VERSION "eCMP INFO-DIV vehicle review 2026-11-03; 125000 bit/s; PSA-RE 67f7581e7622410efdbb29c7eda3b86982b9b450; Apache-2.0"

NS_ :

BS_:

BU_: AAS AMPLI AVP BCM BGP BSG BSI BTA BTEL BTT CDC CMB CRT DIAG_TOOL EDP_C EMF FMUX IC ICSV IDVR IVC_D MATT MDS OVIP PDS_C RAD RBG SDCM VTH WLC

BO_ 305 ICSV_AudioSourceCommand: 8 ICSV
 SG_ ListJumpRequest : 63|8@0+ (1,0) [0|254] ""  CDC
 SG_ CdChangerKnobStepCounter : 55|8@0+ (1,0) [0|255] ""  CDC
 SG_ ValidatedItemNumber : 42|3@0+ (1,0) [0|7] ""  CDC
 SG_ UnicodeSupport : 43|1@0+ (1,0) [0|1] ""  CDC
 SG_ CdChangerListMode : 44|1@0+ (1,0) [0|1] ""  CDC
 SG_ DisplayListLineCount : 47|3@0+ (1,0) [1|6] ""  CDC
 SG_ TrackNumberSelect : 39|8@0+ (1,0) [1|255] ""  CDC
 SG_ ListFocusItemNumber : 26|3@0+ (1,0) [0|7] ""  CDC
 SG_ Unused1 : 31|5@0+ (1,0) [0|31] ""  CDC
 SG_ DiscNumberCommand : 19|4@0+ (1,0) [0|15] ""  CDC
 SG_ NextDiscNumberCommand : 23|4@0+ (1,0) [0|15] ""  CDC
 SG_ CdPlayMode : 9|2@0+ (1,0) [0|3] ""  CDC
 SG_ TrackDiscRepeatMode : 11|2@0+ (1,0) [0|3] ""  CDC
 SG_ AudioMasterMp3Compatible : 12|1@0+ (1,0) [0|1] ""  CDC
 SG_ CdChangerCommandSeries : 15|3@0+ (1,0) [0|7] ""  CDC
 SG_ CdChangerCommand : 2|3@0+ (1,0) [0|7] ""  CDC
 SG_ RandomTrackRestartRequest : 3|1@0+ (1,0) [0|1] ""  CDC
 SG_ CdcKnobSyncRequest : 4|1@0+ (1,0) [0|1] ""  CDC
 SG_ RandomTableSeek : 6|2@0+ (1,0) [0|3] ""  CDC
 SG_ CdChangerOnOff : 7|1@0+ (1,0) [0|1] ""  CDC

BO_ 321 SDCM_UidTableEncryptedToBsi: 8 SDCM
 SG_ FlowPadding5 m3 : 63|8@0+ (1,0) [0|255] "raw"  BSI
 SG_ FirstData6 m1 : 63|8@0+ (1,0) [0|255] "raw"  BSI
 SG_ UnknownData7 m4 : 63|8@0+ (1,0) [0|255] "raw"  BSI
 SG_ ConsecutiveData7 m2 : 63|8@0+ (1,0) [0|255] "raw"  BSI
 SG_ SingleData7 m0 : 63|8@0+ (1,0) [0|255] "raw"  BSI
 SG_ FlowPadding4 m3 : 55|8@0+ (1,0) [0|255] "raw"  BSI
 SG_ FirstData5 m1 : 55|8@0+ (1,0) [0|255] "raw"  BSI
 SG_ UnknownData6 m4 : 55|8@0+ (1,0) [0|255] "raw"  BSI
 SG_ ConsecutiveData6 m2 : 55|8@0+ (1,0) [0|255] "raw"  BSI
 SG_ SingleData6 m0 : 55|8@0+ (1,0) [0|255] "raw"  BSI
 SG_ FlowPadding3 m3 : 47|8@0+ (1,0) [0|255] "raw"  BSI
 SG_ FirstData4 m1 : 47|8@0+ (1,0) [0|255] "raw"  BSI
 SG_ UnknownData5 m4 : 47|8@0+ (1,0) [0|255] "raw"  BSI
 SG_ ConsecutiveData5 m2 : 47|8@0+ (1,0) [0|255] "raw"  BSI
 SG_ SingleData5 m0 : 47|8@0+ (1,0) [0|255] "raw"  BSI
 SG_ FlowPadding2 m3 : 39|8@0+ (1,0) [0|255] "raw"  BSI
 SG_ FirstData3 m1 : 39|8@0+ (1,0) [0|255] "raw"  BSI
 SG_ UnknownData4 m4 : 39|8@0+ (1,0) [0|255] "raw"  BSI
 SG_ ConsecutiveData4 m2 : 39|8@0+ (1,0) [0|255] "raw"  BSI
 SG_ SingleData4 m0 : 39|8@0+ (1,0) [0|255] "raw"  BSI
 SG_ FlowPadding1 m3 : 31|8@0+ (1,0) [0|255] "raw"  BSI
 SG_ FirstData2 m1 : 31|8@0+ (1,0) [0|255] "raw"  BSI
 SG_ UnknownData3 m4 : 31|8@0+ (1,0) [0|255] "raw"  BSI
 SG_ ConsecutiveData3 m2 : 31|8@0+ (1,0) [0|255] "raw"  BSI
 SG_ SingleData3 m0 : 31|8@0+ (1,0) [0|255] "raw"  BSI
 SG_ FirstData1 m1 : 23|8@0+ (1,0) [0|255] "raw"  BSI
 SG_ UnknownData2 m4 : 23|8@0+ (1,0) [0|255] "raw"  BSI
 SG_ ConsecutiveData2 m2 : 23|8@0+ (1,0) [0|255] "raw"  BSI
 SG_ SingleData2 m0 : 23|8@0+ (1,0) [0|255] "raw"  BSI
 SG_ SeparationTimeRaw m3 : 23|8@0+ (1,0) [0|255] "raw"  BSI
 SG_ UnknownData1 m4 : 15|8@0+ (1,0) [0|255] "raw"  BSI
 SG_ ConsecutiveData1 m2 : 15|8@0+ (1,0) [0|255] "raw"  BSI
 SG_ SingleData1 m0 : 15|8@0+ (1,0) [0|255] "raw"  BSI
 SG_ BlockSize m3 : 15|8@0+ (1,0) [0|255] "raw"  BSI
 SG_ UnknownPciLow m4 : 3|4@0+ (1,0) [0|15] "raw"  BSI
 SG_ FlowStatus m3 : 3|4@0+ (1,0) [0|15] "raw"  BSI
 SG_ ConsecutiveSequence m2 : 3|4@0+ (1,0) [0|15] "raw"  BSI
 SG_ FirstFrameLength m1 : 3|12@0+ (1,0) [0|4095] "raw"  BSI
 SG_ SingleFrameLength m0 : 3|4@0+ (1,0) [0|15] "raw"  BSI
 SG_ IsoTpFrameType M : 7|4@0+ (1,0) [0|15] ""  BSI

BO_ 347 EMF_ProfileSettingsScreen: 8 EMF
 SG_ AmlaActivationRequest : 56|1@0+ (1,0) [0|1] ""  BSI
 SG_ AfsActivationRequest : 57|1@0+ (1,0) [0|1] ""  BSI
 SG_ ArsActivationRequest : 58|1@0+ (1,0) [0|1] ""  BSI
 SG_ IrvInhibitRequest : 59|1@0+ (1,0) [0|1] ""  BSI
 SG_ DaeModeSelection4wd : 61|2@0+ (1,0) [0|3] ""  BSI
 SG_ DaeModeSelection : 63|2@0+ (1,0) [0|3] ""  BSI
 SG_ DriverAlertAssistActivati_e419b7 : 48|1@0+ (1,0) [0|1] ""  BSI
 SG_ LoadedArmAccessLockRequest : 49|1@0+ (1,0) [0|1] ""  BSI
 SG_ LoadedArmAccessRequest : 50|1@0+ (1,0) [0|1] ""  BSI
 SG_ IlvScreenRequest : 51|1@0+ (1,0) [0|1] ""  BSI
 SG_ GrilleLightingFunctionStatus : 52|1@0+ (1,0) [0|1] ""  BSI
 SG_ CafrActivationRequest : 53|1@0+ (1,0) [0|1] ""  BSI
 SG_ UserProfileSelection : 55|2@0+ (1,0) [0|3] ""  BSI
 SG_ EtsrActivationRequest : 40|1@0+ (1,0) [0|1] ""  BSI
 SG_ SeeModeSelection : 41|1@0+ (1,0) [0|1] ""  BSI
 SG_ ReverseMirrorIndexingRequest : 42|1@0+ (1,0) [0|1] ""  BSI
 SG_ TpmsInitFunctionRequest : 43|1@0+ (1,0) [0|1] ""  BSI
 SG_ CollisionRiskBrakingType : 44|1@0+ (1,0) [0|1] ""  BSI
 SG_ ArcSensitivityLevel : 46|2@0+ (1,0) [0|3] ""  BSI
 SG_ ArcFunctionActive : 47|1@0+ (1,0) [0|1] ""  BSI
 SG_ ConfigurableButtonFunction : 35|4@0+ (1,0) [0|15] ""  BSI
 SG_ RearFlapMotorizationFunct_177f8c : 36|1@0+ (1,0) [0|1] ""  BSI
 SG_ AutomaticRearWiperInReverse : 37|1@0+ (1,0) [0|1] ""  BSI
 SG_ BlindSpotMonitoringFeedbackType : 38|1@0+ (1,0) [0|1] ""  BSI
 SG_ ParkingAidSetup : 39|1@0+ (1,0) [0|1] ""  BSI
 SG_ AutomaticHeadlightsSwitchingOn : 24|1@0+ (1,0) [0|1] ""  BSI
 SG_ UnlockingLightingDuration : 26|2@0+ (1,0) [0|3] ""  BSI
 SG_ UnlockingLightingFunction : 27|1@0+ (1,0) [0|1] ""  BSI
 SG_ MotorwayLightingFunction : 28|1@0+ (1,0) [0|1] ""  BSI
 SG_ FollowMeHomeDuration : 30|2@0+ (1,0) [0|3] ""  BSI
 SG_ FollowMeHome : 31|1@0+ (1,0) [0|1] ""  BSI
 SG_ AmbientLighting : 16|1@0+ (1,0) [0|1] ""  BSI
 SG_ DlrFunction : 17|1@0+ (1,0) [0|1] ""  BSI
 SG_ AdaptiveLighting : 18|1@0+ (1,0) [0|1] ""  BSI
 SG_ DriverGreeting : 19|1@0+ (1,0) [0|1] ""  BSI
 SG_ RearOpeningsSelectivityStatus : 20|1@0+ (1,0) [0|1] ""  BSI
 SG_ CabOpeningsSelectivityFun_dd2313 : 21|1@0+ (1,0) [0|1] ""  BSI
 SG_ DoorUnlockingModeOnKey : 22|1@0+ (1,0) [0|1] ""  BSI
 SG_ AutomaticElectricParkingB_11b15b : 23|1@0+ (1,0) [0|1] ""  BSI
 SG_ VehicleSoundHarmony : 9|2@0+ (1,0) [0|3] ""  BSI
 SG_ VehicleConfigurationDataValid : 10|1@0+ (1,0) [0|1] ""  BSI
 SG_ AmbientLightingLevel : 13|3@0+ (1,0) [0|7] ""  BSI
 SG_ TemperatureUnit : 14|1@0+ (1,0) [0|1] ""  BSI
 SG_ ConfigVolumeUnit : 15|1@0+ (1,0) [0|1] ""  BSI
 SG_ ConfigConsumptionUnit : 0|1@0+ (1,0) [0|1] ""  BSI
 SG_ DistanceUnit : 1|1@0+ (1,0) [0|1] ""  BSI
 SG_ VehicleLanguage : 6|5@0+ (1,0) [0|31] ""  BSI
 SG_ UnitLanguageDataValidity : 7|1@0+ (1,0) [0|1] ""  BSI

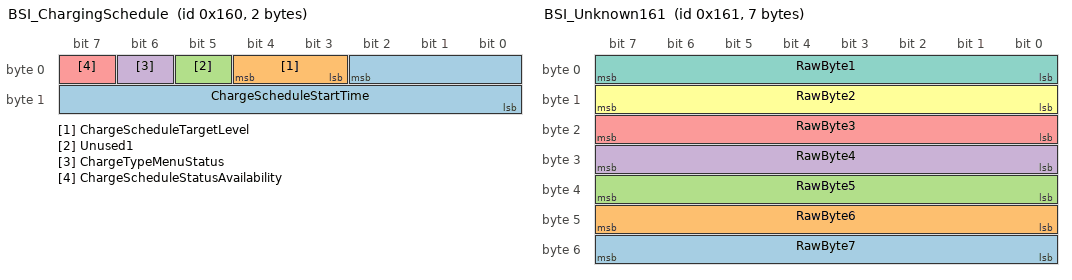
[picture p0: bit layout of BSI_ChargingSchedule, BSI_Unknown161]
BO_ 352 BSI_ChargingSchedule: 2 BSI
 SG_ ChargeScheduleStartTime : 2|11@0+ (1,0) [0|1440] "min"  MDS,BTEL,OVIP
 SG_ ChargeScheduleTargetLevel : 4|2@0+ (1,0) [0|3] ""  MDS,BTEL,OVIP
 SG_ Unused1 : 5|1@0+ (1,0) [0|1] ""  MDS,BTEL,OVIP
 SG_ ChargeTypeMenuStatus : 6|1@0+ (1,0) [0|1] ""  MDS,BTEL,OVIP
 SG_ ChargeScheduleStatusAvailability : 7|1@0+ (1,0) [0|1] ""  MDS,BTEL,OVIP

BO_ 353 BSI_Unknown161: 7 BSI
 SG_ RawByte7 : 55|8@0+ (1,0) [0|255] "raw" Vector__XXX
 SG_ RawByte6 : 47|8@0+ (1,0) [0|255] "raw" Vector__XXX
 SG_ RawByte5 : 39|8@0+ (1,0) [0|255] "raw" Vector__XXX
 SG_ RawByte4 : 31|8@0+ (1,0) [0|255] "raw" Vector__XXX
 SG_ RawByte3 : 23|8@0+ (1,0) [0|255] "raw" Vector__XXX
 SG_ RawByte2 : 15|8@0+ (1,0) [0|255] "raw" Vector__XXX
 SG_ RawByte1 : 7|8@0+ (1,0) [0|255] "raw" Vector__XXX

BO_ 354 ICSV_CdChangerStatus: 7 ICSV
 SG_ CdcFrontPushButtonNumber : 51|4@0+ (1,0) [0|15] ""  RAD,EMF,BTEL,OVIP,BSI
 SG_ CdcEjectLoadButtonPressed : 53|2@0+ (1,0) [0|3] ""  RAD,EMF,BTEL,OVIP,BSI
 SG_ Unused5 : 55|2@0+ (1,0) [0|3] ""  RAD,EMF,BTEL,OVIP,BSI
 SG_ DiscPresenceCd1 : 40|1@0+ (1,0) [0|1] ""  RAD,EMF,BTEL,OVIP,BSI
 SG_ DiscPresenceCd2 : 41|1@0+ (1,0) [0|1] ""  RAD,EMF,BTEL,OVIP,BSI
 SG_ DiscPresenceCd3 : 42|1@0+ (1,0) [0|1] ""  RAD,EMF,BTEL,OVIP,BSI
 SG_ DiscPresenceCd4 : 43|1@0+ (1,0) [0|1] ""  RAD,EMF,BTEL,OVIP,BSI
 SG_ DiscPresenceCd5 : 44|1@0+ (1,0) [0|1] ""  RAD,EMF,BTEL,OVIP,BSI
 SG_ DiscPresenceCd6 : 45|1@0+ (1,0) [0|1] ""  RAD,EMF,BTEL,OVIP,BSI
 SG_ DiscPresenceCd7 : 46|1@0+ (1,0) [0|1] ""  RAD,EMF,BTEL,OVIP,BSI
 SG_ DiscPresenceCd8 : 47|1@0+ (1,0) [0|1] ""  RAD,EMF,BTEL,OVIP,BSI
 SG_ Unused4 : 39|8@0+ (1,0) [0|255] ""  RAD,EMF,BTEL,OVIP,BSI
 SG_ CdcCurrentDiscNumber : 27|4@0+ (1,0) [1|15] ""  RAD,EMF,BTEL,OVIP,BSI
 SG_ Unused3 : 29|2@0+ (1,0) [0|3] ""  RAD,EMF,BTEL,OVIP,BSI
 SG_ CdcAccessType : 31|2@0+ (1,0) [0|3] ""  RAD,EMF,BTEL,OVIP,BSI
 SG_ CdcCapacity : 19|4@0+ (1,0) [0|15] ""  RAD,EMF,BTEL,OVIP,BSI
 SG_ CdcMagazinePresence : 20|1@0+ (1,0) [0|1] ""  RAD,EMF,BTEL,OVIP,BSI
 SG_ CdcDoorStatus : 21|1@0+ (1,0) [0|1] ""  RAD,EMF,BTEL,OVIP,BSI
 SG_ CdcStatusError : 22|1@0+ (1,0) [0|1] ""  RAD,EMF,BTEL,OVIP,BSI
 SG_ CdcOverTemperature : 23|1@0+ (1,0) [0|1] ""  RAD,EMF,BTEL,OVIP,BSI
 SG_ CdcPlayerState : 10|3@0+ (1,0) [0|7] ""  RAD,EMF,BTEL,OVIP,BSI
 SG_ CdcTextAvailable : 11|1@0+ (1,0) [0|1] ""  RAD,EMF,BTEL,OVIP,BSI
 SG_ DiscError : 12|1@0+ (1,0) [0|1] ""  RAD,EMF,BTEL,OVIP,BSI
 SG_ DiscUpsideDown : 13|1@0+ (1,0) [0|1] ""  RAD,EMF,BTEL,OVIP,BSI
 SG_ CdcMp3Support : 14|1@0+ (1,0) [0|1] ""  RAD,EMF,BTEL,OVIP,BSI
 SG_ CdcDiscAccessInProgress : 15|1@0+ (1,0) [0|1] ""  RAD,EMF,BTEL,OVIP,BSI
 SG_ Unused2 : 1|2@0+ (1,0) [0|3] ""  RAD,EMF,BTEL,OVIP,BSI
 SG_ CdcTrackDiscRepeatState : 3|2@0+ (1,0) [0|3] ""  RAD,EMF,BTEL,OVIP,BSI
 SG_ Unused1 : 4|1@0+ (1,0) [0|1] ""  RAD,EMF,BTEL,OVIP,BSI
 SG_ CdcChangerType : 5|1@0+ (1,0) [0|1] ""  RAD,EMF,BTEL,OVIP,BSI
 SG_ CdcListModeRequest : 6|1@0+ (1,0) [0|1] ""  RAD,EMF,BTEL,OVIP,BSI
 SG_ CdcOnOffStatus : 7|1@0+ (1,0) [0|1] ""  RAD,EMF,BTEL,OVIP,BSI

BO_ 355 ICSV_KmlListNone: 8 ICSV
 SG_ FlowPadding5 m3 : 63|8@0+ (1,0) [0|255] "raw"  EMF
 SG_ FirstData6 m1 : 63|8@0+ (1,0) [0|255] "raw"  EMF
 SG_ UnknownData7 m4 : 63|8@0+ (1,0) [0|255] "raw"  EMF
 SG_ ConsecutiveData7 m2 : 63|8@0+ (1,0) [0|255] "raw"  EMF
 SG_ SingleData7 m0 : 63|8@0+ (1,0) [0|255] "raw"  EMF
 SG_ FlowPadding4 m3 : 55|8@0+ (1,0) [0|255] "raw"  EMF
 SG_ FirstData5 m1 : 55|8@0+ (1,0) [0|255] "raw"  EMF
 SG_ UnknownData6 m4 : 55|8@0+ (1,0) [0|255] "raw"  EMF
 SG_ ConsecutiveData6 m2 : 55|8@0+ (1,0) [0|255] "raw"  EMF
 SG_ SingleData6 m0 : 55|8@0+ (1,0) [0|255] "raw"  EMF
 SG_ FlowPadding3 m3 : 47|8@0+ (1,0) [0|255] "raw"  EMF
 SG_ FirstData4 m1 : 47|8@0+ (1,0) [0|255] "raw"  EMF
 SG_ UnknownData5 m4 : 47|8@0+ (1,0) [0|255] "raw"  EMF
 SG_ ConsecutiveData5 m2 : 47|8@0+ (1,0) [0|255] "raw"  EMF
 SG_ SingleData5 m0 : 47|8@0+ (1,0) [0|255] "raw"  EMF
 SG_ FlowPadding2 m3 : 39|8@0+ (1,0) [0|255] "raw"  EMF
 SG_ FirstData3 m1 : 39|8@0+ (1,0) [0|255] "raw"  EMF
 SG_ UnknownData4 m4 : 39|8@0+ (1,0) [0|255] "raw"  EMF
 SG_ ConsecutiveData4 m2 : 39|8@0+ (1,0) [0|255] "raw"  EMF
 SG_ SingleData4 m0 : 39|8@0+ (1,0) [0|255] "raw"  EMF
 SG_ FlowPadding1 m3 : 31|8@0+ (1,0) [0|255] "raw"  EMF
 SG_ FirstData2 m1 : 31|8@0+ (1,0) [0|255] "raw"  EMF
 SG_ UnknownData3 m4 : 31|8@0+ (1,0) [0|255] "raw"  EMF
 SG_ ConsecutiveData3 m2 : 31|8@0+ (1,0) [0|255] "raw"  EMF
 SG_ SingleData3 m0 : 31|8@0+ (1,0) [0|255] "raw"  EMF
 SG_ FirstData1 m1 : 23|8@0+ (1,0) [0|255] "raw"  EMF
 SG_ UnknownData2 m4 : 23|8@0+ (1,0) [0|255] "raw"  EMF
 SG_ ConsecutiveData2 m2 : 23|8@0+ (1,0) [0|255] "raw"  EMF
 SG_ SingleData2 m0 : 23|8@0+ (1,0) [0|255] "raw"  EMF
 SG_ SeparationTimeRaw m3 : 23|8@0+ (1,0) [0|255] "raw"  EMF
 SG_ UnknownData1 m4 : 15|8@0+ (1,0) [0|255] "raw"  EMF
 SG_ ConsecutiveData1 m2 : 15|8@0+ (1,0) [0|255] "raw"  EMF
 SG_ SingleData1 m0 : 15|8@0+ (1,0) [0|255] "raw"  EMF
 SG_ BlockSize m3 : 15|8@0+ (1,0) [0|255] "raw"  EMF
 SG_ UnknownPciLow m4 : 3|4@0+ (1,0) [0|15] "raw"  EMF
 SG_ FlowStatus m3 : 3|4@0+ (1,0) [0|15] "raw"  EMF
 SG_ ConsecutiveSequence m2 : 3|4@0+ (1,0) [0|15] "raw"  EMF
 SG_ FirstFrameLength m1 : 3|12@0+ (1,0) [0|4095] "raw"  EMF
 SG_ SingleFrameLength m0 : 3|4@0+ (1,0) [0|15] "raw"  EMF
 SG_ IsoTpFrameType M : 7|4@0+ (1,0) [0|15] ""  EMF

BO_ 357 BTEL_RadioStatusGeneral: 6 BTEL
 SG_ RawByte6 : 47|8@0+ (1,0) [0|255] "raw" Vector__XXX
 SG_ Unused1 : 38|7@0+ (1,0) [0|127] ""  CRT,FMUX,CMB,EMF,BSI,AMPLI,MDS,BTA
 SG_ MixedChannelMute : 39|1@0+ (1,0) [0|1] ""  CRT,FMUX,CMB,EMF,BSI,AMPLI,MDS,BTA
 SG_ BtSrc : 25|2@0+ (1,0) [0|3] ""  CRT,FMUX,CMB,EMF,BSI,AMPLI,MDS,BTA
 SG_ SupportedDigitalRadio : 28|3@0+ (1,0) [0|7] ""  CRT,FMUX,CMB,EMF,BSI,AMPLI,MDS,BTA
 SG_ CdAudioCompression : 31|3@0+ (1,0) [0|7] ""  CRT,FMUX,CMB,EMF,BSI,AMPLI,MDS,BTA
 SG_ NoSrc : 18|3@0+ (1,0) [0|7] ""  CRT,FMUX,CMB,EMF,BSI,AMPLI,MDS,BTA
 SG_ SrcKml : 19|1@0+ (1,0) [0|1] ""  CRT,FMUX,CMB,EMF,BSI,AMPLI,MDS,BTA
 SG_ SrcSel : 22|3@0+ (1,0) [0|7] ""  CRT,FMUX,CMB,EMF,BSI,AMPLI,MDS,BTA
 SG_ SrcMix : 23|1@0+ (1,0) [0|1] ""  CRT,FMUX,CMB,EMF,BSI,AMPLI,MDS,BTA
 SG_ TimeshiftHoldRequest : 8|1@0+ (1,0) [0|1] ""  CRT,FMUX,CMB,EMF,BSI,AMPLI,MDS,BTA
 SG_ UsbSrc : 10|2@0+ (1,0) [0|3] ""  CRT,FMUX,CMB,EMF,BSI,AMPLI,MDS,BTA
 SG_ CdcSrc : 12|2@0+ (1,0) [0|3] ""  CRT,FMUX,CMB,EMF,BSI,AMPLI,MDS,BTA
 SG_ CdSrc : 14|2@0+ (1,0) [0|3] ""  CRT,FMUX,CMB,EMF,BSI,AMPLI,MDS,BTA
 SG_ TunSrc : 15|1@0+ (1,0) [0|1] ""  CRT,FMUX,CMB,EMF,BSI,AMPLI,MDS,BTA
 SG_ UsbSourceType : 0|1@0+ (1,0) [0|1] ""  CRT,FMUX,CMB,EMF,BSI,AMPLI,MDS,BTA
 SG_ DynamicsCompression : 1|1@0+ (1,0) [0|1] ""  CRT,FMUX,CMB,EMF,BSI,AMPLI,MDS,BTA
 SG_ HifiVersion : 2|1@0+ (1,0) [0|1] ""  CRT,FMUX,CMB,EMF,BSI,AMPLI,MDS,BTA
 SG_ BiTuner : 3|1@0+ (1,0) [0|1] ""  CRT,FMUX,CMB,EMF,BSI,AMPLI,MDS,BTA
 SG_ RadioOnRequest : 4|1@0+ (1,0) [0|1] ""  CRT,FMUX,CMB,EMF,BSI,AMPLI,MDS,BTA
 SG_ Mute : 5|1@0+ (1,0) [0|1] ""  CRT,FMUX,CMB,EMF,BSI,AMPLI,MDS,BTA
 SG_ AmpliOn : 6|1@0+ (1,0) [0|1] ""  CRT,FMUX,CMB,EMF,BSI,AMPLI,MDS,BTA
 SG_ Power : 7|1@0+ (1,0) [0|1] ""  CRT,FMUX,CMB,EMF,BSI,AMPLI,MDS,BTA

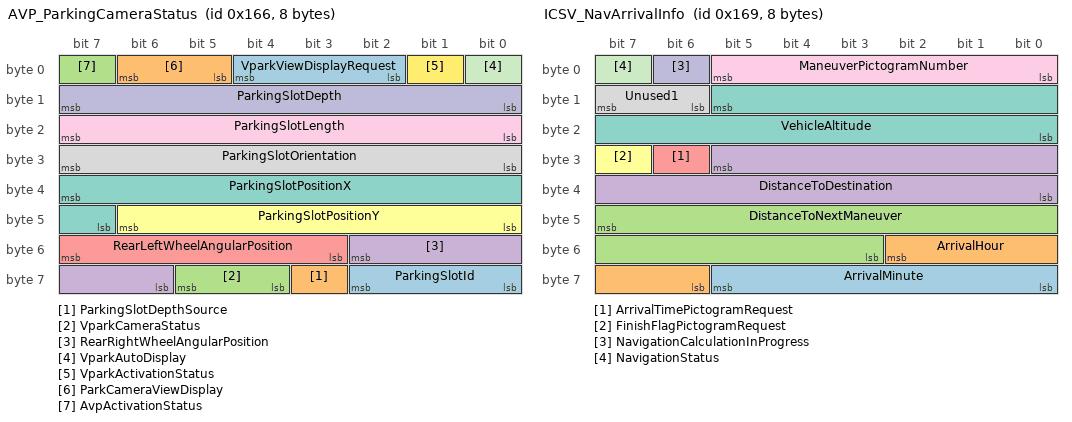
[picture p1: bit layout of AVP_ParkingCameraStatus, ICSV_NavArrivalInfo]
BO_ 358 AVP_ParkingCameraStatus: 8 AVP
 SG_ ParkingSlotId : 58|3@0+ (1,0) [0|7] ""  ICSV,CMB,BTEL,OVIP,AAS,RAD
 SG_ ParkingSlotDepthSource : 59|1@0+ (1,0) [0|1] ""  ICSV,CMB,BTEL,OVIP,AAS,RAD
 SG_ VparkCameraStatus : 61|2@0+ (1,0) [0|3] ""  ICSV,CMB,BTEL,OVIP,AAS,RAD
 SG_ RearRightWheelAngularPosition : 50|5@0+ (1,0) [0|31] ""  ICSV,CMB,BTEL,OVIP,AAS,RAD
 SG_ RearLeftWheelAngularPosition : 55|5@0+ (1,0) [0|31] ""  ICSV,CMB,BTEL,OVIP,AAS,RAD
 SG_ ParkingSlotPositionY : 46|7@0+ (4,-252) [-252|252] "cm"  ICSV,CMB,BTEL,OVIP,AAS,RAD
 SG_ ParkingSlotPositionX : 39|9@0+ (4,-1020) [-1020|1024] "cm"  ICSV,CMB,BTEL,OVIP,AAS,RAD
 SG_ ParkingSlotOrientation : 31|8@0+ (1,0) [0|255] "°"  ICSV,CMB,BTEL,OVIP,AAS,RAD
 SG_ ParkingSlotLength : 23|8@0+ (4,0) [0|1020] "cm"  ICSV,CMB,BTEL,OVIP,AAS,RAD
 SG_ ParkingSlotDepth : 15|8@0+ (4,0) [0|1020] "cm"  ICSV,CMB,BTEL,OVIP,AAS,RAD
 SG_ VparkAutoDisplay : 0|1@0+ (1,0) [0|1] ""  ICSV,CMB,BTEL,OVIP,AAS,RAD
 SG_ VparkActivationStatus : 1|1@0+ (1,0) [0|1] ""  ICSV,CMB,BTEL,OVIP,AAS,RAD
 SG_ VparkViewDisplayRequest : 4|3@0+ (1,0) [0|7] ""  ICSV,CMB,BTEL,OVIP,AAS,RAD
 SG_ ParkCameraViewDisplay : 6|2@0+ (1,0) [0|3] ""  ICSV,CMB,BTEL,OVIP,AAS,RAD
 SG_ AvpActivationStatus : 7|1@0+ (1,0) [0|1] ""  ICSV,CMB,BTEL,OVIP,AAS,RAD

BO_ 359 BTEL_EmfControlData: 8 BTEL
 SG_ Unused3 : 57|2@0+ (1,0) [0|3] ""  CMB,BSI,RAD,ICSV
 SG_ MainMenuSelection : 60|3@0+ (1,0) [0|7] ""  CMB,BSI,RAD,ICSV
 SG_ WifiSettingsUpdateAck : 61|1@0+ (1,0) [0|1] ""  CMB,BSI,RAD,ICSV
 SG_ HmiUserAction : 63|2@0+ (1,0) [0|3] ""  CMB,BSI,RAD,ICSV
 SG_ HmiPopupIdAck : 55|8@0+ (1,0) [0|255] ""  CMB,BSI,RAD,ICSV
 SG_ InteractiveMessagePointer : 38|15@0+ (1,0) [0|32767] ""  CMB,BSI,RAD,ICSV
 SG_ CheckStopRequest : 39|1@0+ (1,0) [0|1] ""  CMB,BSI,RAD,ICSV
 SG_ TotalMileageForTrip : 23|16@0+ (0.5,0) [0|10000] "km"  CMB,BSI,RAD,ICSV
 SG_ PreconditioningDelay : 11|4@0+ (5,0) [0|30] "min"  CMB,BSI,RAD,ICSV
 SG_ TelematicsFunctionsStatus : 12|1@0+ (1,0) [0|1] ""  CMB,BSI,RAD,ICSV
 SG_ BlackPanelStatus : 13|1@0+ (1,0) [0|1] ""  CMB,BSI,RAD,ICSV
 SG_ Unused2 : 14|1@0+ (1,0) [0|1] ""  CMB,BSI,RAD,ICSV
 SG_ ThermalPreconditioningRequest : 15|1@0+ (1,0) [0|1] ""  CMB,BSI,RAD,ICSV
 SG_ Unused1 : 2|3@0+ (1,0) [0|7] ""  CMB,BSI,RAD,ICSV
 SG_ ResetMaintenanceRequest : 3|1@0+ (1,0) [0|1] ""  CMB,BSI,RAD,ICSV
 SG_ EmergencyCallStatus : 4|1@0+ (1,0) [0|1] ""  CMB,BSI,RAD,ICSV
 SG_ CheckAlertRequest : 5|1@0+ (1,0) [0|1] ""  CMB,BSI,RAD,ICSV
 SG_ ResetTotalsTrip2Request : 6|1@0+ (1,0) [0|1] ""  CMB,BSI,RAD,ICSV
 SG_ ResetTotalsTrip1Request : 7|1@0+ (1,0) [0|1] ""  CMB,BSI,RAD,ICSV

BO_ 360 BSI_CombineAlertsIndicators: 8 BSI
 SG_ HadcWarningLightControl : 57|2@0+ (1,0) [0|3] ""  OVIP,CMB,VTH,MATT,MDS,BTEL,RAD
 SG_ LaneDepartureWarningLightRequest : 59|2@0+ (1,0) [0|3] ""  OVIP,CMB,VTH,MATT,MDS,BTEL,RAD
 SG_ HudRightWarningLight : 60|1@0+ (1,0) [0|1] ""  OVIP,CMB,VTH,MATT,MDS,BTEL,RAD
 SG_ HudLeftWarningLight : 61|1@0+ (1,0) [0|1] ""  OVIP,CMB,VTH,MATT,MDS,BTEL,RAD
 SG_ FarcIndicatorRequest : 63|2@0+ (1,0) [0|3] ""  OVIP,CMB,VTH,MATT,MDS,BTEL,RAD
 SG_ BrakeAssistFault : 48|1@0+ (1,0) [0|1] ""  OVIP,CMB,VTH,MATT,MDS,BTEL,RAD
 SG_ CurrentGearDrive : 52|4@0+ (1,0) [0|15] ""  OVIP,CMB,VTH,MATT,MDS,BTEL,RAD
 SG_ EmfAvailabilityAck : 53|1@0+ (1,0) [0|1] ""  OVIP,CMB,VTH,MATT,MDS,BTEL,RAD
 SG_ AmbienceButtonAuthorization : 54|1@0+ (1,0) [0|1] ""  OVIP,CMB,VTH,MATT,MDS,BTEL,RAD
 SG_ HudEnabled : 55|1@0+ (1,0) [0|1] ""  OVIP,CMB,VTH,MATT,MDS,BTEL,RAD
 SG_ Unused1 : 40|1@0+ (1,0) [0|1] ""  OVIP,CMB,VTH,MATT,MDS,BTEL,RAD
 SG_ DaFaultLightTestMode : 41|1@0+ (1,0) [0|1] ""  OVIP,CMB,VTH,MATT,MDS,BTEL,RAD
 SG_ DaFault2UpdateBit : 42|1@0+ (1,0) [0|1] ""  OVIP,CMB,VTH,MATT,MDS,BTEL,RAD
 SG_ DaFaultType : 44|2@0+ (1,0) [0|3] ""  OVIP,CMB,VTH,MATT,MDS,BTEL,RAD
 SG_ DaFault1UpdateBit : 45|1@0+ (1,0) [0|1] ""  OVIP,CMB,VTH,MATT,MDS,BTEL,RAD
 SG_ DaFaultIndicatorRequest : 47|2@0+ (1,0) [0|3] ""  OVIP,CMB,VTH,MATT,MDS,BTEL,RAD
 SG_ SttIndicator : 33|2@0+ (1,0) [0|3] ""  OVIP,CMB,VTH,MATT,MDS,BTEL,RAD
 SG_ PowerSteeringFault : 34|1@0+ (1,0) [0|1] ""  OVIP,CMB,VTH,MATT,MDS,BTEL,RAD
 SG_ Caar : 36|2@0+ (1,0) [0|3] ""  OVIP,CMB,VTH,MATT,MDS,BTEL,RAD
 SG_ SafetyFault : 37|1@0+ (1,0) [0|1] ""  OVIP,CMB,VTH,MATT,MDS,BTEL,RAD
 SG_ TurnLightsFault : 38|1@0+ (1,0) [0|1] ""  OVIP,CMB,VTH,MATT,MDS,BTEL,RAD
 SG_ DieselWaterFault : 39|1@0+ (1,0) [0|1] ""  OVIP,CMB,VTH,MATT,MDS,BTEL,RAD
 SG_ MilRequestUpdateBit : 24|1@0+ (1,0) [0|1] ""  OVIP,CMB,VTH,MATT,MDS,BTEL,RAD
 SG_ EobdFault : 25|1@0+ (1,0) [0|1] ""  OVIP,CMB,VTH,MATT,MDS,BTEL,RAD
 SG_ BrakesFault : 26|1@0+ (1,0) [0|1] ""  OVIP,CMB,VTH,MATT,MDS,BTEL,RAD
 SG_ GearboxFault : 27|1@0+ (1,0) [0|1] ""  OVIP,CMB,VTH,MATT,MDS,BTEL,RAD
 SG_ AsrFault : 28|1@0+ (1,0) [0|1] ""  OVIP,CMB,VTH,MATT,MDS,BTEL,RAD
 SG_ AbsFault : 29|1@0+ (1,0) [0|1] ""  OVIP,CMB,VTH,MATT,MDS,BTEL,RAD
 SG_ ParkingBrakeTightFault : 30|1@0+ (1,0) [0|1] ""  OVIP,CMB,VTH,MATT,MDS,BTEL,RAD
 SG_ ParkingBrakeFault : 31|1@0+ (1,0) [0|1] ""  OVIP,CMB,VTH,MATT,MDS,BTEL,RAD
 SG_ AlternatorFault : 16|1@0+ (1,0) [0|1] ""  OVIP,CMB,VTH,MATT,MDS,BTEL,RAD
 SG_ BatteryFault : 17|1@0+ (1,0) [0|1] ""  OVIP,CMB,VTH,MATT,MDS,BTEL,RAD
 SG_ SuspensionFault : 18|1@0+ (1,0) [0|1] ""  OVIP,CMB,VTH,MATT,MDS,BTEL,RAD
 SG_ RefEhbFault : 19|1@0+ (1,0) [0|1] ""  OVIP,CMB,VTH,MATT,MDS,BTEL,RAD
 SG_ RearRearRightSeatbeltBlink : 20|1@0+ (1,0) [0|1] ""  OVIP,CMB,VTH,MATT,MDS,BTEL,RAD
 SG_ RearRearRightSeatbelt : 21|1@0+ (1,0) [0|1] ""  OVIP,CMB,VTH,MATT,MDS,BTEL,RAD
 SG_ RearRearLeftSeatbeltBlink : 22|1@0+ (1,0) [0|1] ""  OVIP,CMB,VTH,MATT,MDS,BTEL,RAD
 SG_ RearRearLeftSeatbelt : 23|1@0+ (1,0) [0|1] ""  OVIP,CMB,VTH,MATT,MDS,BTEL,RAD
 SG_ PlusStartIndicator : 8|1@0+ (1,0) [0|1] ""  OVIP,CMB,VTH,MATT,MDS,BTEL,RAD
 SG_ MaxRpmLvl2 : 9|1@0+ (1,0) [0|1] ""  OVIP,CMB,VTH,MATT,MDS,BTEL,RAD
 SG_ MaxRpmLvl1 : 10|1@0+ (1,0) [0|1] ""  OVIP,CMB,VTH,MATT,MDS,BTEL,RAD
 SG_ AutoWipeStatus : 11|1@0+ (1,0) [0|1] ""  OVIP,CMB,VTH,MATT,MDS,BTEL,RAD
 SG_ ParticleFilterFault : 12|1@0+ (1,0) [0|1] ""  OVIP,CMB,VTH,MATT,MDS,BTEL,RAD
 SG_ PollutionFault : 13|1@0+ (1,0) [0|1] ""  OVIP,CMB,VTH,MATT,MDS,BTEL,RAD
 SG_ PunctureAlert : 14|1@0+ (1,0) [0|1] ""  OVIP,CMB,VTH,MATT,MDS,BTEL,RAD
 SG_ UnderinflationAlert : 15|1@0+ (1,0) [0|1] ""  OVIP,CMB,VTH,MATT,MDS,BTEL,RAD
 SG_ DsgFaultLightState : 0|1@0+ (1,0) [0|1] ""  OVIP,CMB,VTH,MATT,MDS,BTEL,RAD
 SG_ ColdEngineAlert : 1|1@0+ (1,0) [0|1] ""  OVIP,CMB,VTH,MATT,MDS,BTEL,RAD
 SG_ BrakeLevelAlert : 2|1@0+ (1,0) [0|1] ""  OVIP,CMB,VTH,MATT,MDS,BTEL,RAD
 SG_ OilPressureAlert : 3|1@0+ (1,0) [0|1] ""  OVIP,CMB,VTH,MATT,MDS,BTEL,RAD
 SG_ OilLevelAlert : 4|1@0+ (1,0) [0|1] ""  OVIP,CMB,VTH,MATT,MDS,BTEL,RAD
 SG_ CoolantLevelAlert : 5|1@0+ (1,0) [0|1] ""  OVIP,CMB,VTH,MATT,MDS,BTEL,RAD
 SG_ GearboxRatioCount : 6|1@0+ (1,0) [0|1] ""  OVIP,CMB,VTH,MATT,MDS,BTEL,RAD
 SG_ CoolantTemperatureAlert : 7|1@0+ (1,0) [0|1] ""  OVIP,CMB,VTH,MATT,MDS,BTEL,RAD

BO_ 361 ICSV_NavArrivalInfo: 8 ICSV
 SG_ ArrivalMinute : 61|6@0+ (1,0) [0|59] "min"  BSI,VTH,MATT,CMB
 SG_ ArrivalHour : 50|5@0+ (1,0) [0|23] "h"  BSI,VTH,MATT,CMB
 SG_ DistanceToNextManeuver : 47|13@0+ (1,0) [0|8191] ""  BSI,VTH,MATT,CMB
 SG_ DistanceToDestination : 29|14@0+ (1,0) [0|16383] ""  BSI,VTH,MATT,CMB
 SG_ ArrivalTimePictogramRequest : 30|1@0+ (1,0) [0|1] ""  BSI,VTH,MATT,CMB
 SG_ FinishFlagPictogramRequest : 31|1@0+ (1,0) [0|1] ""  BSI,VTH,MATT,CMB
 SG_ VehicleAltitude : 13|14@0+ (1,-999) [-999|15383] "m"  BSI,VTH,MATT,CMB
 SG_ Unused1 : 15|2@0+ (1,0) [0|3] ""  BSI,VTH,MATT,CMB
 SG_ ManeuverPictogramNumber : 5|6@0+ (1,0) [0|63] ""  BSI,VTH,MATT,CMB
 SG_ NavigationCalculationInProgress : 6|1@0+ (1,0) [0|1] ""  BSI,VTH,MATT,CMB
 SG_ NavigationStatus : 7|1@0+ (1,0) [0|1] ""  BSI,VTH,MATT,CMB

BO_ 385 BSI_UidTableEncryptedToSdcm: 8 BSI
 SG_ FlowPadding5 m3 : 63|8@0+ (1,0) [0|255] "raw"  SDCM
 SG_ FirstData6 m1 : 63|8@0+ (1,0) [0|255] "raw"  SDCM
 SG_ UnknownData7 m4 : 63|8@0+ (1,0) [0|255] "raw"  SDCM
 SG_ ConsecutiveData7 m2 : 63|8@0+ (1,0) [0|255] "raw"  SDCM
 SG_ SingleData7 m0 : 63|8@0+ (1,0) [0|255] "raw"  SDCM
 SG_ FlowPadding4 m3 : 55|8@0+ (1,0) [0|255] "raw"  SDCM
 SG_ FirstData5 m1 : 55|8@0+ (1,0) [0|255] "raw"  SDCM
 SG_ UnknownData6 m4 : 55|8@0+ (1,0) [0|255] "raw"  SDCM
 SG_ ConsecutiveData6 m2 : 55|8@0+ (1,0) [0|255] "raw"  SDCM
 SG_ SingleData6 m0 : 55|8@0+ (1,0) [0|255] "raw"  SDCM
 SG_ FlowPadding3 m3 : 47|8@0+ (1,0) [0|255] "raw"  SDCM
 SG_ FirstData4 m1 : 47|8@0+ (1,0) [0|255] "raw"  SDCM
 SG_ UnknownData5 m4 : 47|8@0+ (1,0) [0|255] "raw"  SDCM
 SG_ ConsecutiveData5 m2 : 47|8@0+ (1,0) [0|255] "raw"  SDCM
 SG_ SingleData5 m0 : 47|8@0+ (1,0) [0|255] "raw"  SDCM
 SG_ FlowPadding2 m3 : 39|8@0+ (1,0) [0|255] "raw"  SDCM
 SG_ FirstData3 m1 : 39|8@0+ (1,0) [0|255] "raw"  SDCM
 SG_ UnknownData4 m4 : 39|8@0+ (1,0) [0|255] "raw"  SDCM
 SG_ ConsecutiveData4 m2 : 39|8@0+ (1,0) [0|255] "raw"  SDCM
 SG_ SingleData4 m0 : 39|8@0+ (1,0) [0|255] "raw"  SDCM
 SG_ FlowPadding1 m3 : 31|8@0+ (1,0) [0|255] "raw"  SDCM
 SG_ FirstData2 m1 : 31|8@0+ (1,0) [0|255] "raw"  SDCM
 SG_ UnknownData3 m4 : 31|8@0+ (1,0) [0|255] "raw"  SDCM
 SG_ ConsecutiveData3 m2 : 31|8@0+ (1,0) [0|255] "raw"  SDCM
 SG_ SingleData3 m0 : 31|8@0+ (1,0) [0|255] "raw"  SDCM
 SG_ FirstData1 m1 : 23|8@0+ (1,0) [0|255] "raw"  SDCM
 SG_ UnknownData2 m4 : 23|8@0+ (1,0) [0|255] "raw"  SDCM
 SG_ ConsecutiveData2 m2 : 23|8@0+ (1,0) [0|255] "raw"  SDCM
 SG_ SingleData2 m0 : 23|8@0+ (1,0) [0|255] "raw"  SDCM
 SG_ SeparationTimeRaw m3 : 23|8@0+ (1,0) [0|255] "raw"  SDCM
 SG_ UnknownData1 m4 : 15|8@0+ (1,0) [0|255] "raw"  SDCM
 SG_ ConsecutiveData1 m2 : 15|8@0+ (1,0) [0|255] "raw"  SDCM
 SG_ SingleData1 m0 : 15|8@0+ (1,0) [0|255] "raw"  SDCM
 SG_ BlockSize m3 : 15|8@0+ (1,0) [0|255] "raw"  SDCM
 SG_ UnknownPciLow m4 : 3|4@0+ (1,0) [0|15] "raw"  SDCM
 SG_ FlowStatus m3 : 3|4@0+ (1,0) [0|15] "raw"  SDCM
 SG_ ConsecutiveSequence m2 : 3|4@0+ (1,0) [0|15] "raw"  SDCM
 SG_ FirstFrameLength m1 : 3|12@0+ (1,0) [0|4095] "raw"  SDCM
 SG_ SingleFrameLength m0 : 3|4@0+ (1,0) [0|15] "raw"  SDCM
 SG_ IsoTpFrameType M : 7|4@0+ (1,0) [0|15] ""  SDCM

BO_ 387 MDS_OdiEventPacketBuffer: 4 MDS
 SG_ OdiEventPacketBuffer : 7|32@0+ (1,0) [0|4294967295] ""  BTEL

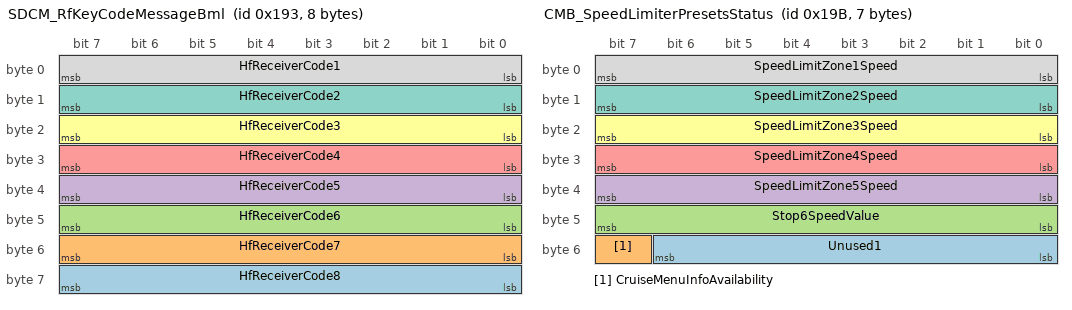
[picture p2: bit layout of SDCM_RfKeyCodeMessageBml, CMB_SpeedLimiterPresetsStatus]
BO_ 403 SDCM_RfKeyCodeMessageBml: 8 SDCM
 SG_ HfReceiverCode8 : 63|8@0+ (1,0) [0|255] ""  BSI,BCM
 SG_ HfReceiverCode7 : 55|8@0+ (1,0) [0|255] ""  BSI,BCM
 SG_ HfReceiverCode6 : 47|8@0+ (1,0) [0|255] ""  BSI,BCM
 SG_ HfReceiverCode5 : 39|8@0+ (1,0) [0|255] ""  BSI,BCM
 SG_ HfReceiverCode4 : 31|8@0+ (1,0) [0|255] ""  BSI,BCM
 SG_ HfReceiverCode3 : 23|8@0+ (1,0) [0|255] ""  BSI,BCM
 SG_ HfReceiverCode2 : 15|8@0+ (1,0) [0|255] ""  BSI,BCM
 SG_ HfReceiverCode1 : 7|8@0+ (1,0) [0|255] ""  BSI,BCM

BO_ 411 CMB_SpeedLimiterPresetsStatus: 7 CMB
 SG_ Unused1 : 54|7@0+ (1,0) [0|127] ""  BSI
 SG_ CruiseMenuInfoAvailability : 55|1@0+ (1,0) [0|1] ""  BSI
 SG_ Stop6SpeedValue : 47|8@0+ (1,0) [0|253] "km/h"  BSI
 SG_ SpeedLimitZone5Speed : 39|8@0+ (1,0) [0|254] "km/h"  BSI
 SG_ SpeedLimitZone4Speed : 31|8@0+ (1,0) [0|254] "km/h"  BSI
 SG_ SpeedLimitZone3Speed : 23|8@0+ (1,0) [0|254] "km/h"  BSI
 SG_ SpeedLimitZone2Speed : 15|8@0+ (1,0) [0|254] "km/h"  BSI
 SG_ SpeedLimitZone1Speed : 7|8@0+ (1,0) [0|254] "km/h"  BSI

BO_ 412 BSI_EcoDrivingAdvice: 8 BSI
 SG_ Unused3 : 56|1@0+ (1,0) [0|1] ""  BTEL,OVIP,CMB,MATT
 SG_ EcocoachAdvice31Active : 57|1@0+ (1,0) [0|1] ""  BTEL,OVIP,CMB,MATT
 SG_ EcocoachAdvice30Active : 58|1@0+ (1,0) [0|1] ""  BTEL,OVIP,CMB,MATT
 SG_ EcocoachAdvice29Active : 59|1@0+ (1,0) [0|1] ""  BTEL,OVIP,CMB,MATT
 SG_ EcocoachAdvice28Active : 60|1@0+ (1,0) [0|1] ""  BTEL,OVIP,CMB,MATT
 SG_ EcocoachAdvice27Active : 61|1@0+ (1,0) [0|1] ""  BTEL,OVIP,CMB,MATT
 SG_ EcocoachAdvice26Active : 62|1@0+ (1,0) [0|1] ""  BTEL,OVIP,CMB,MATT
 SG_ EcocoachAdvice25Active : 63|1@0+ (1,0) [0|1] ""  BTEL,OVIP,CMB,MATT
 SG_ EcocoachAdvice24Active : 48|1@0+ (1,0) [0|1] ""  BTEL,OVIP,CMB,MATT
 SG_ EcocoachAdvice23Active : 49|1@0+ (1,0) [0|1] ""  BTEL,OVIP,CMB,MATT
 SG_ EcocoachAdvice22Active : 50|1@0+ (1,0) [0|1] ""  BTEL,OVIP,CMB,MATT
 SG_ EcocoachAdvice21Active : 51|1@0+ (1,0) [0|1] ""  BTEL,OVIP,CMB,MATT
 SG_ EcocoachAdvice20Active : 52|1@0+ (1,0) [0|1] ""  BTEL,OVIP,CMB,MATT
 SG_ EcocoachAdvice19Active : 53|1@0+ (1,0) [0|1] ""  BTEL,OVIP,CMB,MATT
 SG_ EcocoachAdvice18Active : 54|1@0+ (1,0) [0|1] ""  BTEL,OVIP,CMB,MATT
 SG_ EcocoachAdvice17Active : 55|1@0+ (1,0) [0|1] ""  BTEL,OVIP,CMB,MATT
 SG_ EcocoachAdvice16Active : 40|1@0+ (1,0) [0|1] ""  BTEL,OVIP,CMB,MATT
 SG_ EcocoachAdvice15Active : 41|1@0+ (1,0) [0|1] ""  BTEL,OVIP,CMB,MATT
 SG_ EcocoachAdvice14Active : 42|1@0+ (1,0) [0|1] ""  BTEL,OVIP,CMB,MATT
 SG_ EcocoachAdvice13Active : 43|1@0+ (1,0) [0|1] ""  BTEL,OVIP,CMB,MATT
 SG_ EcocoachAdvice12Active : 44|1@0+ (1,0) [0|1] ""  BTEL,OVIP,CMB,MATT
 SG_ EcocoachAdvice11Active : 45|1@0+ (1,0) [0|1] ""  BTEL,OVIP,CMB,MATT
 SG_ EcocoachAdvice10Active : 46|1@0+ (1,0) [0|1] ""  BTEL,OVIP,CMB,MATT
 SG_ EcocoachAdvice9Active : 47|1@0+ (1,0) [0|1] ""  BTEL,OVIP,CMB,MATT
 SG_ EcocoachAdvice8Active : 32|1@0+ (1,0) [0|1] ""  BTEL,OVIP,CMB,MATT
 SG_ EcocoachAdvice7Active : 33|1@0+ (1,0) [0|1] ""  BTEL,OVIP,CMB,MATT
 SG_ EcocoachAdvice6Active : 34|1@0+ (1,0) [0|1] ""  BTEL,OVIP,CMB,MATT
 SG_ EcocoachAdvice5Active : 35|1@0+ (1,0) [0|1] ""  BTEL,OVIP,CMB,MATT
 SG_ EcocoachAdvice4Active : 36|1@0+ (1,0) [0|1] ""  BTEL,OVIP,CMB,MATT
 SG_ EcocoachAdvice3Active : 37|1@0+ (1,0) [0|1] ""  BTEL,OVIP,CMB,MATT
 SG_ EcocoachAdvice2Active : 38|1@0+ (1,0) [0|1] ""  BTEL,OVIP,CMB,MATT
 SG_ EcocoachAdvice1Active : 39|1@0+ (1,0) [0|1] ""  BTEL,OVIP,CMB,MATT
 SG_ Unused2 : 24|1@0+ (1,0) [0|1] ""  BTEL,OVIP,CMB,MATT
 SG_ EcocoachFreewheelTime : 23|15@0+ (1,0) [0|32765] "min"  BTEL,OVIP,CMB,MATT
 SG_ Unused1 : 9|2@0+ (1,0) [0|3] ""  BTEL,OVIP,CMB,MATT
 SG_ EcocoachFreewheelDistance : 7|14@0+ (1,0) [0|10000] "km"  BTEL,OVIP,CMB,MATT

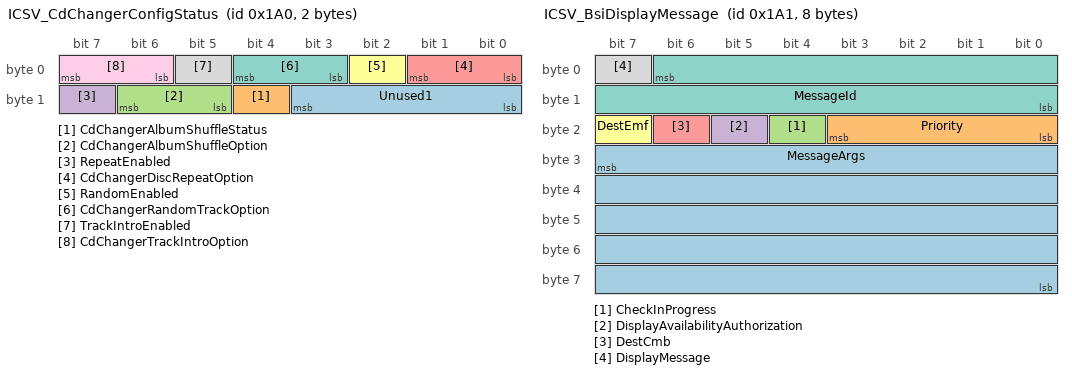
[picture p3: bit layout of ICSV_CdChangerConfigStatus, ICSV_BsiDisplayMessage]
BO_ 416 ICSV_CdChangerConfigStatus: 2 ICSV
 SG_ Unused1 : 11|4@0+ (1,0) [0|15] ""  EMF,BTEL,RAD,OVIP
 SG_ CdChangerAlbumShuffleStatus : 12|1@0+ (1,0) [0|1] ""  EMF,BTEL,RAD,OVIP
 SG_ CdChangerAlbumShuffleOption : 14|2@0+ (1,0) [0|3] ""  EMF,BTEL,RAD,OVIP
 SG_ RepeatEnabled : 15|1@0+ (1,0) [0|1] ""  EMF,BTEL,RAD,OVIP
 SG_ CdChangerDiscRepeatOption : 1|2@0+ (1,0) [0|3] ""  EMF,BTEL,RAD,OVIP
 SG_ RandomEnabled : 2|1@0+ (1,0) [0|1] ""  EMF,BTEL,RAD,OVIP
 SG_ CdChangerRandomTrackOption : 4|2@0+ (1,0) [0|3] ""  EMF,BTEL,RAD,OVIP
 SG_ TrackIntroEnabled : 5|1@0+ (1,0) [0|1] ""  EMF,BTEL,RAD,OVIP
 SG_ CdChangerTrackIntroOption : 7|2@0+ (1,0) [0|3] ""  EMF,BTEL,RAD,OVIP

BO_ 417 ICSV_BsiDisplayMessage: 8 ICSV
 SG_ MessageArgs : 31|40@0+ (1,0) [0|1099511627775] ""  EMF,CMB,BTEL,MATT,OVIP,VTH,RAD
 SG_ Priority : 19|4@0+ (1,0) [0|14] ""  EMF,CMB,BTEL,MATT,OVIP,VTH,RAD
 SG_ CheckInProgress : 20|1@0+ (1,0) [0|1] ""  EMF,CMB,BTEL,MATT,OVIP,VTH,RAD
 SG_ DisplayAvailabilityAuthorization : 21|1@0+ (1,0) [0|1] ""  EMF,CMB,BTEL,MATT,OVIP,VTH,RAD
 SG_ DestCmb : 22|1@0+ (1,0) [0|1] ""  EMF,CMB,BTEL,MATT,OVIP,VTH,RAD
 SG_ DestEmf : 23|1@0+ (1,0) [0|1] ""  EMF,CMB,BTEL,MATT,OVIP,VTH,RAD
 SG_ MessageId : 6|15@0+ (1,0) [0|32767] ""  EMF,CMB,BTEL,MATT,OVIP,VTH,RAD
 SG_ DisplayMessage : 7|1@0+ (1,0) [0|1] ""  EMF,CMB,BTEL,MATT,OVIP,VTH,RAD

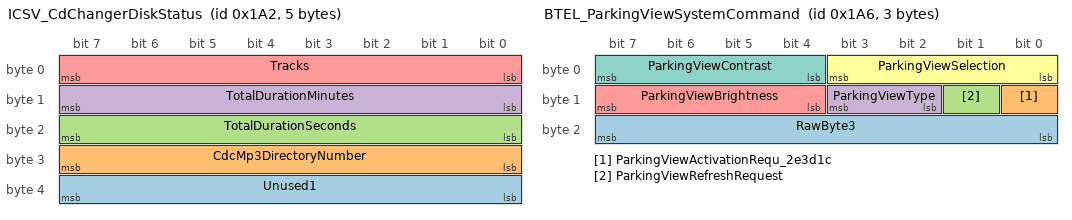
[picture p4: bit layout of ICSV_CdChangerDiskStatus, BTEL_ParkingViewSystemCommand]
BO_ 418 ICSV_CdChangerDiskStatus: 5 ICSV
 SG_ Unused1 : 39|8@0+ (1,0) [0|255] ""  RAD,BTEL,OVIP,EMF
 SG_ CdcMp3DirectoryNumber : 31|8@0+ (1,0) [0|254] ""  RAD,BTEL,OVIP,EMF
 SG_ TotalDurationSeconds : 23|8@0+ (1,0) [0|254] ""  RAD,BTEL,OVIP,EMF
 SG_ TotalDurationMinutes : 15|8@0+ (1,0) [0|254] ""  RAD,BTEL,OVIP,EMF
 SG_ Tracks : 7|8@0+ (1,0) [0|254] ""  RAD,BTEL,OVIP,EMF

BO_ 419 RAD_HandsfreeKitGeneralInfo: 7 RAD
 SG_ Unused1 : 49|2@0+ (1,0) [0|3] ""  OVIP,EMF,BSI
 SG_ AutoHoldModeConfig : 51|2@0+ (1,0) [0|3] ""  OVIP,EMF,BSI
 SG_ AutoHoldMode : 52|1@0+ (1,0) [0|1] ""  OVIP,EMF,BSI
 SG_ CallType : 55|3@0+ (1,0) [0|7] ""  OVIP,EMF,BSI
 SG_ BatteryStatusSimple : 47|8@0+ (1,0) [0|100] ""  OVIP,EMF,BSI
 SG_ PairingListAccess : 33|2@0+ (1,0) [0|3] ""  OVIP,EMF,BSI
 SG_ ImportDirectoryAccess : 35|2@0+ (1,0) [0|3] ""  OVIP,EMF,BSI
 SG_ CallLogAvailable : 37|2@0+ (1,0) [0|3] ""  OVIP,EMF,BSI
 SG_ CombinedDirectoryAccess : 39|2@0+ (1,0) [0|3] ""  OVIP,EMF,BSI
 SG_ PhoneBatteryLevel : 31|8@0+ (1,0) [0|100] ""  OVIP,EMF,BSI
 SG_ NetworkQuality : 23|8@0+ (1,0) [0|100] ""  OVIP,EMF,BSI
 SG_ PairingStatus : 8|1@0+ (1,0) [0|1] ""  OVIP,EMF,BSI
 SG_ BluetoothAvailable : 9|1@0+ (1,0) [0|1] ""  OVIP,EMF,BSI
 SG_ KmlMuteRequest : 10|1@0+ (1,0) [0|1] ""  OVIP,EMF,BSI
 SG_ Charging : 11|1@0+ (1,0) [0|1] ""  OVIP,EMF,BSI
 SG_ CallForwarding : 12|1@0+ (1,0) [0|1] ""  OVIP,EMF,BSI
 SG_ VoicemailStatus : 13|1@0+ (1,0) [0|1] ""  OVIP,EMF,BSI
 SG_ MessagesStatus : 15|2@0+ (1,0) [0|3] ""  OVIP,EMF,BSI
 SG_ VoicemailAvailable : 0|1@0+ (1,0) [0|1] ""  OVIP,EMF,BSI
 SG_ RoamingStatus : 1|1@0+ (1,0) [0|1] ""  OVIP,EMF,BSI
 SG_ SecretMode : 2|1@0+ (1,0) [0|1] ""  OVIP,EMF,BSI
 SG_ HeadsetStatus : 3|1@0+ (1,0) [0|1] ""  OVIP,EMF,BSI
 SG_ AutoAnswerModeConfig : 5|2@0+ (1,0) [0|3] ""  OVIP,EMF,BSI
 SG_ AutoAnswerMode : 6|1@0+ (1,0) [0|1] ""  OVIP,EMF,BSI
 SG_ NumberAvailable : 7|1@0+ (1,0) [0|1] ""  OVIP,EMF,BSI

BO_ 421 ICSV_RadioStatusVolume: 1 ICSV
 SG_ Volume : 4|5@0+ (1,0) [0|30] ""  CRT,FMUX,EMF,AMPLI
 SG_ VolumeChanging : 7|3@0+ (1,0) [0|7] ""  CRT,FMUX,EMF,AMPLI

BO_ 422 BTEL_ParkingViewSystemCommand: 3 BTEL
 SG_ RawByte3 : 23|8@0+ (1,0) [0|255] "raw" Vector__XXX
 SG_ ParkingViewActivationRequ_2e3d1c : 8|1@0+ (1,0) [0|1] ""  BSI
 SG_ ParkingViewRefreshRequest : 9|1@0+ (1,0) [0|1] ""  BSI
 SG_ ParkingViewType : 11|2@0+ (1,0) [0|3] ""  BSI
 SG_ ParkingViewBrightness : 15|4@0+ (1,-5) [-5|5] ""  BSI
 SG_ ParkingViewSelection : 3|4@0+ (1,0) [0|15] ""  BSI
 SG_ ParkingViewContrast : 7|4@0+ (1,-5) [-5|5] ""  BSI

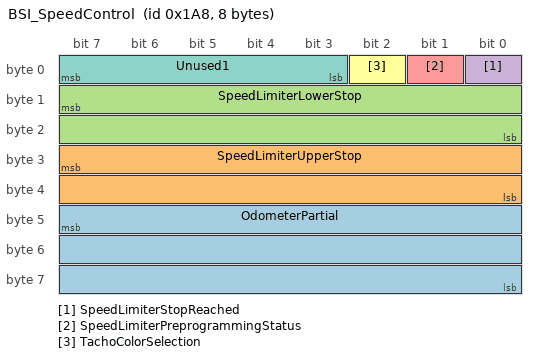
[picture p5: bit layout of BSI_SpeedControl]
BO_ 424 BSI_SpeedControl: 8 BSI
 SG_ OdometerPartial : 47|24@0+ (0.001,0) [0|16777.214] "km"  BGP,CMB,VTH,MATT
 SG_ SpeedLimiterUpperStop : 31|16@0+ (0.01,0) [0|254] "km/h"  BGP,CMB,VTH,MATT
 SG_ SpeedLimiterLowerStop : 15|16@0+ (0.01,0) [0|254] "km/h"  BGP,CMB,VTH,MATT
 SG_ SpeedLimiterStopReached : 0|1@0+ (1,0) [0|1] ""  BGP,CMB,VTH,MATT
 SG_ SpeedLimiterPreprogrammingStatus : 1|1@0+ (1,0) [0|1] ""  BGP,CMB,VTH,MATT
 SG_ TachoColorSelection : 2|1@0+ (1,0) [0|1] ""  BGP,CMB,VTH,MATT
 SG_ Unused1 : 7|5@0+ (1,0) [0|31] ""  BGP,CMB,VTH,MATT

BO_ 425 ICSV_IviButtonRequests: 8 ICSV
 SG_ ParkingCameraViewSelection : 58|3@0+ (1,0) [0|7] ""  AAS,BSI,CMB,AVP
 SG_ CruiseProgrammedSpeedRequest : 59|1@0+ (1,0) [0|1] ""  AAS,BSI,CMB,AVP
 SG_ SurroundCameraPanoramicVi_18c86a : 60|1@0+ (1,0) [0|1] ""  AAS,BSI,CMB,AVP
 SG_ SurroundCameraFrontViewButton : 61|1@0+ (1,0) [0|1] ""  AAS,BSI,CMB,AVP
 SG_ SurroundCameraRearViewButton : 62|1@0+ (1,0) [0|1] ""  AAS,BSI,CMB,AVP
 SG_ SurroundCameraActivationButton : 63|1@0+ (1,0) [0|1] ""  AAS,BSI,CMB,AVP
 SG_ CheckButtonRequest : 48|1@0+ (1,0) [0|1] ""  AAS,BSI,CMB,AVP
 SG_ TouchscreenBrightnessRequest : 52|4@0+ (1,0) [0|15] ""  AAS,BSI,CMB,AVP
 SG_ BtelOperatingPhase : 54|2@0+ (1,0) [0|3] ""  AAS,BSI,CMB,AVP
 SG_ SttButtonStatus : 55|1@0+ (1,0) [0|1] ""  AAS,BSI,CMB,AVP
 SG_ TpmsButtonInput : 40|1@0+ (1,0) [0|1] ""  AAS,BSI,CMB,AVP
 SG_ PushButtonPressed : 41|1@0+ (1,0) [0|1] ""  AAS,BSI,CMB,AVP
 SG_ ScpStateChangeRequest : 42|1@0+ (1,0) [0|1] ""  AAS,BSI,CMB,AVP
 SG_ MediaDisplayFaultArc : 43|1@0+ (1,0) [0|1] ""  AAS,BSI,CMB,AVP
 SG_ CruiseProgrammedSpeedPosition : 46|3@0+ (1,0) [0|7] ""  AAS,BSI,CMB,AVP
 SG_ CruiseProgrammedSpeedValidation : 47|1@0+ (1,0) [0|1] ""  AAS,BSI,CMB,AVP
 SG_ CruiseProgrammedSpeedSetpoint : 39|8@0+ (1,0) [0|254] "km/h"  AAS,BSI,CMB,AVP
 SG_ CruiseSetpointMemoRequest : 24|1@0+ (1,0) [0|1] ""  AAS,BSI,CMB,AVP
 SG_ MpdButtonStatus : 25|1@0+ (1,0) [0|1] ""  AAS,BSI,CMB,AVP
 SG_ AasButtonStatus : 26|1@0+ (1,0) [0|1] ""  AAS,BSI,CMB,AVP
 SG_ CafrButtonInput : 27|1@0+ (1,0) [0|1] ""  AAS,BSI,CMB,AVP
 SG_ SideTrajectoryButtonStatus : 28|1@0+ (1,0) [0|1] ""  AAS,BSI,CMB,AVP
 SG_ SamButtonStatus : 29|1@0+ (1,0) [0|1] ""  AAS,BSI,CMB,AVP
 SG_ ArtivPlusButtonStatus : 30|1@0+ (1,0) [0|1] ""  AAS,BSI,CMB,AVP
 SG_ ArtivMinusButtonStatus : 31|1@0+ (1,0) [0|1] ""  AAS,BSI,CMB,AVP
 SG_ InteractiveMessagePointer : 14|15@0+ (1,0) [0|32767] ""  AAS,BSI,CMB,AVP
 SG_ CheckStopRequest : 15|1@0+ (1,0) [0|1] ""  AAS,BSI,CMB,AVP
 SG_ ResetTotalsTrip2Request : 0|1@0+ (1,0) [0|1] ""  AAS,BSI,CMB,AVP
 SG_ ResetTotalsTrip1Request : 1|1@0+ (1,0) [0|1] ""  AAS,BSI,CMB,AVP
 SG_ ArtivButtonStatus : 2|1@0+ (1,0) [0|1] ""  AAS,BSI,CMB,AVP
 SG_ CpkMenuSelection : 4|2@0+ (1,0) [0|3] ""  AAS,BSI,CMB,AVP
 SG_ TelematicsFunctionsStatus : 5|1@0+ (1,0) [0|1] ""  AAS,BSI,CMB,AVP
 SG_ EmergencyCallStatus : 6|1@0+ (1,0) [0|1] ""  AAS,BSI,CMB,AVP
 SG_ BlackPanelStatus : 7|1@0+ (1,0) [0|1] ""  AAS,BSI,CMB,AVP

BO_TX_BU_ 305 : ICSV,BTEL,RAD,OVIP;
BO_TX_BU_ 347 : EMF,RAD,MATT,BTEL,CMB,ICSV,OVIP;
BO_TX_BU_ 354 : ICSV,CDC;
BO_TX_BU_ 355 : ICSV,RAD;
BO_TX_BU_ 357 : BTEL,ICSV,RAD,OVIP;
BO_TX_BU_ 359 : BTEL,EMF;
BO_TX_BU_ 361 : ICSV,BTEL,OVIP;
BO_TX_BU_ 411 : CMB,ICSV,BTEL,OVIP;
BO_TX_BU_ 416 : ICSV,CDC;
BO_TX_BU_ 417 : ICSV,BSI;
BO_TX_BU_ 418 : ICSV,CDC;
BO_TX_BU_ 419 : RAD,ICSV;
BO_TX_BU_ 421 : ICSV,OVIP,BTEL,RAD;
BO_TX_BU_ 425 : ICSV,BTEL,OVIP;
CM_ BO_ 305 "DATABASE_CANDIDATE: physical interpretation unverified; capture/layout evidence reported separately. INFO-DIV CAN, 125000 bit/s; CAN ID 0x131. PSA-RE title: AUDIO_SOURCE_COMMAND. CD player / audio source commands sent for network monitoring purposes: play/stop, disc and track number, playback mode and random seek. Source: https://github.com/prototux/PSA-RE/blob/67f7581e7622410efdbb29c7eda3b86982b9b450/buses/AEE2010.full/LS.INFO-DIV/131.yml. Source sender alternatives: ICSV,BTEL,RAD,OVIP; physical TX/gateway forwarding not verified. Observed 5869 frames in info_apka.csv,info_buzeni_obc.csv,info_charging.csv,info_standby.csv,info_start_jizda.csv,infocan.csv; DLCs [8]. ";
CM_ SG_ 305 ListJumpRequest "DATABASE_CANDIDATE: physical interpretation unverified; capture/layout evidence reported separately. PSA-RE bits 8.7-8.0. Request to jump within the list Upstream default raw=255 (not necessarily valid data).";
CM_ SG_ 305 CdChangerKnobStepCounter "DATABASE_CANDIDATE: physical interpretation unverified; capture/layout evidence reported separately. PSA-RE bits 7.7-7.0. CD changer control knob step counter Upstream default raw=0 (not necessarily valid data).";
CM_ SG_ 305 ValidatedItemNumber "DATABASE_CANDIDATE: physical interpretation unverified; capture/layout evidence reported separately. PSA-RE bits 6.2-6.0. Number of the validated list item Upstream default raw=0 (not necessarily valid data).";
CM_ SG_ 305 UnicodeSupport "DATABASE_CANDIDATE: physical interpretation unverified; capture/layout evidence reported separately. PSA-RE bits 6.3. Unicode support handled by the system (Japanese/Chinese) Upstream default raw=0 (not necessarily valid data).";
CM_ SG_ 305 CdChangerListMode "DATABASE_CANDIDATE: physical interpretation unverified; capture/layout evidence reported separately. PSA-RE bits 6.4. CD changer list mode requested Upstream default raw=0 (not necessarily valid data).";
CM_ SG_ 305 DisplayListLineCount "DATABASE_CANDIDATE: physical interpretation unverified; capture/layout evidence reported separately. PSA-RE bits 6.7-6.5. Number of lines that can be displayed on the EMF (multifunction display) Upstream default raw=1 (not necessarily valid data).";
CM_ SG_ 305 TrackNumberSelect "DATABASE_CANDIDATE: physical interpretation unverified; capture/layout evidence reported separately. PSA-RE bits 5.7-5.0. Track number selection command Upstream default raw=0 (not necessarily valid data).";
CM_ SG_ 305 ListFocusItemNumber "DATABASE_CANDIDATE: physical interpretation unverified; capture/layout evidence reported separately. PSA-RE bits 4.2-4.0. Number of the list item that must take the focus Upstream default raw=0 (not necessarily valid data).";
CM_ SG_ 305 Unused1 "DATABASE_CANDIDATE: physical interpretation unverified; capture/layout evidence reported separately. PSA-RE bits 4.7-4.3. ";
CM_ SG_ 305 DiscNumberCommand "DATABASE_CANDIDATE: physical interpretation unverified; capture/layout evidence reported separately. PSA-RE bits 3.3-3.0. Command for the number of the disc to play Upstream default raw=0 (not necessarily valid data).";
CM_ SG_ 305 NextDiscNumberCommand "DATABASE_CANDIDATE: physical interpretation unverified; capture/layout evidence reported separately. PSA-RE bits 3.7-3.4. Command for the number of the next disc to play Upstream default raw=0 (not necessarily valid data).";
CM_ SG_ 305 CdPlayMode "DATABASE_CANDIDATE: physical interpretation unverified; capture/layout evidence reported separately. PSA-RE bits 2.1-2.0. CD play mode control (normal, shuffle tracks, shuffle discs, shuffle tracks and discs) Upstream default raw=0 (not necessarily valid data).";
CM_ SG_ 305 TrackDiscRepeatMode "DATABASE_CANDIDATE: physical interpretation unverified; capture/layout evidence reported separately. PSA-RE bits 2.3-2.2. Track / disc repeat mode control Upstream default raw=0 (not necessarily valid data).";
CM_ SG_ 305 AudioMasterMp3Compatible "DATABASE_CANDIDATE: physical interpretation unverified; capture/layout evidence reported separately. PSA-RE bits 2.4. Audio master unit is compatible with MP3 CD changer Upstream default raw=0 (not necessarily valid data).";
CM_ SG_ 305 CdChangerCommandSeries "DATABASE_CANDIDATE: physical interpretation unverified; capture/layout evidence reported separately. PSA-RE bits 2.7-2.5. CD changer command series (rest, up, down, invalid, OK) Upstream default raw=0 (not necessarily valid data).";
CM_ SG_ 305 CdChangerCommand "DATABASE_CANDIDATE: physical interpretation unverified; capture/layout evidence reported separately. PSA-RE bits 1.2-1.0. CD changer transport command (eject, stop, pause, play, fast-forward) Upstream default raw=1 (not necessarily valid data).";
CM_ SG_ 305 RandomTrackRestartRequest "DATABASE_CANDIDATE: physical interpretation unverified; capture/layout evidence reported separately. PSA-RE bits 1.3. Request to return to the start of the track in random mode Upstream default raw=0 (not necessarily valid data).";
CM_ SG_ 305 CdcKnobSyncRequest "DATABASE_CANDIDATE: physical interpretation unverified; capture/layout evidence reported separately. PSA-RE bits 1.4. CD changer scroll knob synchronization request Upstream default raw=0 (not necessarily valid data).";
CM_ SG_ 305 RandomTableSeek "DATABASE_CANDIDATE: physical interpretation unverified; capture/layout evidence reported separately. PSA-RE bits 1.6-1.5. Seek up/down within the CD changer's random play table Upstream default raw=0 (not necessarily valid data).";
CM_ SG_ 305 CdChangerOnOff "DATABASE_CANDIDATE: physical interpretation unverified; capture/layout evidence reported separately. PSA-RE bits 1.7. CD changer on/off Upstream default raw=0 (not necessarily valid data).";
CM_ BO_ 321 "DATABASE_CANDIDATE: physical interpretation unverified; capture/layout evidence reported separately. INFO-DIV CAN, 125000 bit/s; CAN ID 0x141. PSA-RE title: UID_TABLE_ENCRYPTED_TO_BSI. Encrypted identifier table transmitted to the BSI Source: https://github.com/prototux/PSA-RE/blob/67f7581e7622410efdbb29c7eda3b86982b9b450/buses/AEE2010.full/LS.INFO-DIV/141.yml. Source sender alternatives: SDCM; physical TX/gateway forwarding not verified. WIRE ISO-TP ONLY: normal addressing candidate, maximum Classical CAN DLC 8; actual DLC may be shorter. Data includes padding. No reassembly, text, DID or application-layer decoding. Original application layouts are preserved in source JSON; do not decode them at wire offsets. Unresolved alternative source layouts preserved in source JSON. ";
CM_ SG_ 321 FlowPadding5 "TRANSPORT_CANDIDATE: normal-addressing ISO-TP. PSA-RE bits 8.7-8.0. ";
CM_ SG_ 321 FirstData6 "TRANSPORT_CANDIDATE: normal-addressing ISO-TP. PSA-RE bits 8.7-8.0. ";
CM_ SG_ 321 UnknownData7 "TRANSPORT_CANDIDATE: normal-addressing ISO-TP. PSA-RE bits 8.7-8.0. ";
CM_ SG_ 321 ConsecutiveData7 "TRANSPORT_CANDIDATE: normal-addressing ISO-TP. PSA-RE bits 8.7-8.0. ";
CM_ SG_ 321 SingleData7 "TRANSPORT_CANDIDATE: normal-addressing ISO-TP. PSA-RE bits 8.7-8.0. ";
CM_ SG_ 321 FlowPadding4 "TRANSPORT_CANDIDATE: normal-addressing ISO-TP. PSA-RE bits 7.7-7.0. ";
CM_ SG_ 321 FirstData5 "TRANSPORT_CANDIDATE: normal-addressing ISO-TP. PSA-RE bits 7.7-7.0. ";
CM_ SG_ 321 UnknownData6 "TRANSPORT_CANDIDATE: normal-addressing ISO-TP. PSA-RE bits 7.7-7.0. ";
CM_ SG_ 321 ConsecutiveData6 "TRANSPORT_CANDIDATE: normal-addressing ISO-TP. PSA-RE bits 7.7-7.0. ";
CM_ SG_ 321 SingleData6 "TRANSPORT_CANDIDATE: normal-addressing ISO-TP. PSA-RE bits 7.7-7.0. ";
CM_ SG_ 321 FlowPadding3 "TRANSPORT_CANDIDATE: normal-addressing ISO-TP. PSA-RE bits 6.7-6.0. ";
CM_ SG_ 321 FirstData4 "TRANSPORT_CANDIDATE: normal-addressing ISO-TP. PSA-RE bits 6.7-6.0. ";
CM_ SG_ 321 UnknownData5 "TRANSPORT_CANDIDATE: normal-addressing ISO-TP. PSA-RE bits 6.7-6.0. ";
CM_ SG_ 321 ConsecutiveData5 "TRANSPORT_CANDIDATE: normal-addressing ISO-TP. PSA-RE bits 6.7-6.0. ";
CM_ SG_ 321 SingleData5 "TRANSPORT_CANDIDATE: normal-addressing ISO-TP. PSA-RE bits 6.7-6.0. ";
CM_ SG_ 321 FlowPadding2 "TRANSPORT_CANDIDATE: normal-addressing ISO-TP. PSA-RE bits 5.7-5.0. ";
CM_ SG_ 321 FirstData3 "TRANSPORT_CANDIDATE: normal-addressing ISO-TP. PSA-RE bits 5.7-5.0. ";
CM_ SG_ 321 UnknownData4 "TRANSPORT_CANDIDATE: normal-addressing ISO-TP. PSA-RE bits 5.7-5.0. ";
CM_ SG_ 321 ConsecutiveData4 "TRANSPORT_CANDIDATE: normal-addressing ISO-TP. PSA-RE bits 5.7-5.0. ";
CM_ SG_ 321 SingleData4 "TRANSPORT_CANDIDATE: normal-addressing ISO-TP. PSA-RE bits 5.7-5.0. ";
CM_ SG_ 321 FlowPadding1 "TRANSPORT_CANDIDATE: normal-addressing ISO-TP. PSA-RE bits 4.7-4.0. ";
CM_ SG_ 321 FirstData2 "TRANSPORT_CANDIDATE: normal-addressing ISO-TP. PSA-RE bits 4.7-4.0. ";
CM_ SG_ 321 UnknownData3 "TRANSPORT_CANDIDATE: normal-addressing ISO-TP. PSA-RE bits 4.7-4.0. ";
CM_ SG_ 321 ConsecutiveData3 "TRANSPORT_CANDIDATE: normal-addressing ISO-TP. PSA-RE bits 4.7-4.0. ";
CM_ SG_ 321 SingleData3 "TRANSPORT_CANDIDATE: normal-addressing ISO-TP. PSA-RE bits 4.7-4.0. ";
CM_ SG_ 321 FirstData1 "TRANSPORT_CANDIDATE: normal-addressing ISO-TP. PSA-RE bits 3.7-3.0. ";
CM_ SG_ 321 UnknownData2 "TRANSPORT_CANDIDATE: normal-addressing ISO-TP. PSA-RE bits 3.7-3.0. ";
CM_ SG_ 321 ConsecutiveData2 "TRANSPORT_CANDIDATE: normal-addressing ISO-TP. PSA-RE bits 3.7-3.0. ";
CM_ SG_ 321 SingleData2 "TRANSPORT_CANDIDATE: normal-addressing ISO-TP. PSA-RE bits 3.7-3.0. ";
CM_ SG_ 321 SeparationTimeRaw "TRANSPORT_CANDIDATE: normal-addressing ISO-TP. PSA-RE bits 3.7-3.0. Raw STmin code; 0xF1..0xF9 are not milliseconds.";
CM_ SG_ 321 UnknownData1 "TRANSPORT_CANDIDATE: normal-addressing ISO-TP. PSA-RE bits 2.7-2.0. ";
CM_ SG_ 321 ConsecutiveData1 "TRANSPORT_CANDIDATE: normal-addressing ISO-TP. PSA-RE bits 2.7-2.0. ";
CM_ SG_ 321 SingleData1 "TRANSPORT_CANDIDATE: normal-addressing ISO-TP. PSA-RE bits 2.7-2.0. ";
CM_ SG_ 321 BlockSize "TRANSPORT_CANDIDATE: normal-addressing ISO-TP. PSA-RE bits 2.7-2.0. ";
CM_ SG_ 321 UnknownPciLow "TRANSPORT_CANDIDATE: normal-addressing ISO-TP. PSA-RE bits 1.3-1.0. ";
CM_ SG_ 321 FlowStatus "TRANSPORT_CANDIDATE: normal-addressing ISO-TP. PSA-RE bits 1.3-1.0. ";
CM_ SG_ 321 ConsecutiveSequence "TRANSPORT_CANDIDATE: normal-addressing ISO-TP. PSA-RE bits 1.3-1.0. ";
CM_ SG_ 321 FirstFrameLength "TRANSPORT_CANDIDATE: normal-addressing ISO-TP. PSA-RE bits 1.3-2.0. 12-bit declared PDU length; not a reassembled value.";
CM_ SG_ 321 SingleFrameLength "TRANSPORT_CANDIDATE: normal-addressing ISO-TP. PSA-RE bits 1.3-1.0. Declared data length; not a validity check.";
CM_ SG_ 321 IsoTpFrameType "TRANSPORT_CANDIDATE: normal-addressing ISO-TP. PSA-RE bits 1.7-1.4. PCI high nibble; normal addressing candidate.";
CM_ BO_ 347 "DATABASE_CANDIDATE: physical interpretation unverified; capture/layout evidence reported separately. INFO-DIV CAN, 125000 bit/s; CAN ID 0x15B. PSA-RE title: PROFILE_SETTINGS_SCREEN. Driver profile and settings screen requests (part 1): welcome, parking aid, units and language, lock/alert menus. Source: https://github.com/prototux/PSA-RE/blob/67f7581e7622410efdbb29c7eda3b86982b9b450/buses/AEE2010.full/LS.INFO-DIV/15B.yml. Source sender alternatives: EMF,RAD,MATT,BTEL,CMB,ICSV,OVIP; physical TX/gateway forwarding not verified. ";
CM_ SG_ 347 AmlaActivationRequest "DATABASE_CANDIDATE: physical interpretation unverified; capture/layout evidence reported separately. PSA-RE bits 8.0. Request to activate the AMLA function Upstream default raw=1 (not necessarily valid data).";
CM_ SG_ 347 AfsActivationRequest "DATABASE_CANDIDATE: physical interpretation unverified; capture/layout evidence reported separately. PSA-RE bits 8.1. Request to activate the adaptive front lighting (AFS) function Upstream default raw=0 (not necessarily valid data).";
CM_ SG_ 347 ArsActivationRequest "DATABASE_CANDIDATE: physical interpretation unverified; capture/layout evidence reported separately. PSA-RE bits 8.2. Request to activate the ARS function Upstream default raw=0 (not necessarily valid data).";
CM_ SG_ 347 IrvInhibitRequest "DATABASE_CANDIDATE: physical interpretation unverified; capture/layout evidence reported separately. PSA-RE bits 8.3. Request to activate the IRV inhibition function Upstream default raw=1 (not necessarily valid data).";
CM_ SG_ 347 DaeModeSelection4wd "DATABASE_CANDIDATE: physical interpretation unverified; capture/layout evidence reported separately. PSA-RE bits 8.5-8.4. DAE mode request for 4WD: sport or normal Upstream default raw=0 (not necessarily valid data).";
CM_ SG_ 347 DaeModeSelection "DATABASE_CANDIDATE: physical interpretation unverified; capture/layout evidence reported separately. PSA-RE bits 8.7-8.6. DAE mode request: sport or normal Upstream default raw=0 (not necessarily valid data).";
CM_ SG_ 347 DriverAlertAssistActivati_e419b7 "DATABASE_CANDIDATE: physical interpretation unverified; capture/layout evidence reported separately. PSA-RE bits 7.0. Request to activate the Driver Alert Assist function Upstream default raw=0 (not necessarily valid data).";
CM_ SG_ 347 LoadedArmAccessLockRequest "DATABASE_CANDIDATE: physical interpretation unverified; capture/layout evidence reported separately. PSA-RE bits 7.1. Request to activate the loaded-arm access locking function Upstream default raw=0 (not necessarily valid data).";
CM_ SG_ 347 LoadedArmAccessRequest "DATABASE_CANDIDATE: physical interpretation unverified; capture/layout evidence reported separately. PSA-RE bits 7.2. Request to activate the loaded-arm access function Upstream default raw=0 (not necessarily valid data).";
CM_ SG_ 347 IlvScreenRequest "DATABASE_CANDIDATE: physical interpretation unverified; capture/layout evidence reported separately. PSA-RE bits 7.3. Request to display the ILV function screen Upstream default raw=0 (not necessarily valid data).";
CM_ SG_ 347 GrilleLightingFunctionStatus "DATABASE_CANDIDATE: physical interpretation unverified; capture/layout evidence reported separately. PSA-RE bits 7.4. Radiator grille lighting function status Upstream default raw=0 (not necessarily valid data).";
CM_ SG_ 347 CafrActivationRequest "DATABASE_CANDIDATE: physical interpretation unverified; capture/layout evidence reported separately. PSA-RE bits 7.5. Request to activate the CAFR function Upstream default raw=0 (not necessarily valid data).";
CM_ SG_ 347 UserProfileSelection "DATABASE_CANDIDATE: physical interpretation unverified; capture/layout evidence reported separately. PSA-RE bits 7.7-7.6. Selected user profile Upstream default raw=0 (not necessarily valid data).";
CM_ SG_ 347 EtsrActivationRequest "DATABASE_CANDIDATE: physical interpretation unverified; capture/layout evidence reported separately. PSA-RE bits 6.0. Request to activate the ETSR (trailer stability) function Upstream default raw=0 (not necessarily valid data).";
CM_ SG_ 347 SeeModeSelection "DATABASE_CANDIDATE: physical interpretation unverified; capture/layout evidence reported separately. PSA-RE bits 6.1. Request of the SEE function mode: permanent or temporary deselection Upstream default raw=0 (not necessarily valid data).";
CM_ SG_ 347 ReverseMirrorIndexingRequest "DATABASE_CANDIDATE: physical interpretation unverified; capture/layout evidence reported separately. PSA-RE bits 6.2. Request to index the mirror when reverse gear is engaged Upstream default raw=0 (not necessarily valid data).";
CM_ SG_ 347 TpmsInitFunctionRequest "DATABASE_CANDIDATE: physical interpretation unverified; capture/layout evidence reported separately. PSA-RE bits 6.3. Request to activate the tyre pressure monitoring (TPMS) initialization function Upstream default raw=0 (not necessarily valid data).";
CM_ SG_ 347 CollisionRiskBrakingType "DATABASE_CANDIDATE: physical interpretation unverified; capture/layout evidence reported separately. PSA-RE bits 6.4. Type of braking on collision risk alert Upstream default raw=0 (not necessarily valid data).";
CM_ SG_ 347 ArcSensitivityLevel "DATABASE_CANDIDATE: physical interpretation unverified; capture/layout evidence reported separately. PSA-RE bits 6.6-6.5. ARC function sensitivity level Upstream default raw=2 (not necessarily valid data).";
CM_ SG_ 347 ArcFunctionActive "DATABASE_CANDIDATE: physical interpretation unverified; capture/layout evidence reported separately. PSA-RE bits 6.7. ARC function activation status Upstream default raw=0 (not necessarily valid data).";
CM_ SG_ 347 ConfigurableButtonFunction "DATABASE_CANDIDATE: physical interpretation unverified; capture/layout evidence reported separately. PSA-RE bits 5.3-5.0. Function currently assigned to the configurable key Upstream default raw=0 (not necessarily valid data).";
CM_ SG_ 347 RearFlapMotorizationFunct_177f8c "DATABASE_CANDIDATE: physical interpretation unverified; capture/layout evidence reported separately. PSA-RE bits 5.4. Rear flap motorization function status Upstream default raw=0 (not necessarily valid data).";
CM_ SG_ 347 AutomaticRearWiperInReverse "DATABASE_CANDIDATE: physical interpretation unverified; capture/layout evidence reported separately. PSA-RE bits 5.5. Memorized activation status of the automatic rear wiper in reverse gear function Upstream default raw=0 (not necessarily valid data).";
CM_ SG_ 347 BlindSpotMonitoringFeedbackType "DATABASE_CANDIDATE: physical interpretation unverified; capture/layout evidence reported separately. PSA-RE bits 5.6. Type of blind spot monitoring information feedback Upstream default raw=0 (not necessarily valid data).";
CM_ SG_ 347 ParkingAidSetup "DATABASE_CANDIDATE: physical interpretation unverified; capture/layout evidence reported separately. PSA-RE bits 5.7. Type of user feedback returned by the parking aid function Upstream default raw=0 (not necessarily valid data).";
CM_ SG_ 347 AutomaticHeadlightsSwitchingOn "DATABASE_CANDIDATE: physical interpretation unverified; capture/layout evidence reported separately. PSA-RE bits 4.0. Memorized activation status of the automatic headlights switching on function";
CM_ SG_ 347 UnlockingLightingDuration "DATABASE_CANDIDATE: physical interpretation unverified; capture/layout evidence reported separately. PSA-RE bits 4.2-4.1. Unlocking lighting duration setting Upstream default raw=0 (not necessarily valid data).";
CM_ SG_ 347 UnlockingLightingFunction "DATABASE_CANDIDATE: physical interpretation unverified; capture/layout evidence reported separately. PSA-RE bits 4.3. Memorized activation status of the unlocking lighting function Upstream default raw=0 (not necessarily valid data).";
CM_ SG_ 347 MotorwayLightingFunction "DATABASE_CANDIDATE: physical interpretation unverified; capture/layout evidence reported separately. PSA-RE bits 4.4. Memorized activation status of the motorway lighting function Upstream default raw=0 (not necessarily valid data).";
CM_ SG_ 347 FollowMeHomeDuration "DATABASE_CANDIDATE: physical interpretation unverified; capture/layout evidence reported separately. PSA-RE bits 4.6-4.5. \"Follow me Home\" escort lighting duration setting Upstream default raw=0 (not necessarily valid data).";
CM_ SG_ 347 FollowMeHome "DATABASE_CANDIDATE: physical interpretation unverified; capture/layout evidence reported separately. PSA-RE bits 4.7. Memorized activation status of the \"Follow me Home\" escort lighting function";
CM_ SG_ 347 AmbientLighting "DATABASE_CANDIDATE: physical interpretation unverified; capture/layout evidence reported separately. PSA-RE bits 3.0. Memorized activation status of the ambient lighting function";
CM_ SG_ 347 DlrFunction "DATABASE_CANDIDATE: physical interpretation unverified; capture/layout evidence reported separately. PSA-RE bits 3.1. Memorized activation status of the daytime running lights function";
CM_ SG_ 347 AdaptiveLighting "DATABASE_CANDIDATE: physical interpretation unverified; capture/layout evidence reported separately. PSA-RE bits 3.2. Memorized activation status of the adaptive lighting function";
CM_ SG_ 347 DriverGreeting "DATABASE_CANDIDATE: physical interpretation unverified; capture/layout evidence reported separately. PSA-RE bits 3.3. Driver greeting function activation status";
CM_ SG_ 347 RearOpeningsSelectivityStatus "DATABASE_CANDIDATE: physical interpretation unverified; capture/layout evidence reported separately. PSA-RE bits 3.4. Rear openings selectivity status Upstream default raw=0 (not necessarily valid data).";
CM_ SG_ 347 CabOpeningsSelectivityFun_dd2313 "DATABASE_CANDIDATE: physical interpretation unverified; capture/layout evidence reported separately. PSA-RE bits 3.5. Cab openings selectivity function status Upstream default raw=0 (not necessarily valid data).";
CM_ SG_ 347 DoorUnlockingModeOnKey "DATABASE_CANDIDATE: physical interpretation unverified; capture/layout evidence reported separately. PSA-RE bits 3.6. Openings selectivity via remote key status Upstream default raw=0 (not necessarily valid data).";
CM_ SG_ 347 AutomaticElectricParkingB_11b15b "DATABASE_CANDIDATE: physical interpretation unverified; capture/layout evidence reported separately. PSA-RE bits 3.7. Automatic electric parking brake application function status";
CM_ SG_ 347 VehicleSoundHarmony "DATABASE_CANDIDATE: physical interpretation unverified; capture/layout evidence reported separately. PSA-RE bits 2.1-2.0. Vehicle sound harmony setting Upstream default raw=0 (not necessarily valid data).";
CM_ SG_ 347 VehicleConfigurationDataValid "DATABASE_CANDIDATE: physical interpretation unverified; capture/layout evidence reported separately. PSA-RE bits 2.2. Validity of the vehicle configuration data Upstream default raw=0 (not necessarily valid data).";
CM_ SG_ 347 AmbientLightingLevel "DATABASE_CANDIDATE: physical interpretation unverified; capture/layout evidence reported separately. PSA-RE bits 2.5-2.3. Ambient lighting level Upstream default raw=3 (not necessarily valid data).";
CM_ SG_ 347 TemperatureUnit "DATABASE_CANDIDATE: physical interpretation unverified; capture/layout evidence reported separately. PSA-RE bits 2.6. Temperature unit chosen by the customer Upstream default raw=0 (not necessarily valid data).";
CM_ SG_ 347 ConfigVolumeUnit "DATABASE_CANDIDATE: physical interpretation unverified; capture/layout evidence reported separately. PSA-RE bits 2.7. Volume unit configuration (litre or gallon) Upstream default raw=0 (not necessarily valid data).";
CM_ SG_ 347 ConfigConsumptionUnit "DATABASE_CANDIDATE: physical interpretation unverified; capture/layout evidence reported separately. PSA-RE bits 1.0. Fuel consumption unit (volume per 100 distance units, or distance per volume unit) Upstream default raw=0 (not necessarily valid data).";
CM_ SG_ 347 DistanceUnit "DATABASE_CANDIDATE: physical interpretation unverified; capture/layout evidence reported separately. PSA-RE bits 1.1. Distance unit Upstream default raw=0 (not necessarily valid data).";
CM_ SG_ 347 VehicleLanguage "DATABASE_CANDIDATE: physical interpretation unverified; capture/layout evidence reported separately. PSA-RE bits 1.6-1.2. Current language used in the vehicle Upstream default raw=0 (not necessarily valid data).";
CM_ SG_ 347 UnitLanguageDataValidity "DATABASE_CANDIDATE: physical interpretation unverified; capture/layout evidence reported separately. PSA-RE bits 1.7. Validity of the speed unit information transmitted in the same frame Upstream default raw=0 (not necessarily valid data).";
CM_ BO_ 352 "DATABASE_CANDIDATE: physical interpretation unverified; capture/layout evidence reported separately. INFO-DIV CAN, 125000 bit/s; CAN ID 0x160. PSA-RE title: CHARGING_SCHEDULE. Battery charging schedule profile information, defined by the profile message structure. Source: https://github.com/prototux/PSA-RE/blob/67f7581e7622410efdbb29c7eda3b86982b9b450/buses/AEE2010.full/LS.INFO-DIV/160.yml. Source sender alternatives: BSI; physical TX/gateway forwarding not verified. Observed 1176 frames in info_apka.csv,info_buzeni_obc.csv,info_charging.csv,info_standby.csv,info_start_jizda.csv,infocan.csv; DLCs [2]. ";
CM_ SG_ 352 ChargeScheduleStartTime "DATABASE_CANDIDATE: physical interpretation unverified; capture/layout evidence reported separately. PSA-RE bits 1.2-2.0. Memorized start time of the charging schedule, in minutes since midnight Upstream default raw=0 (not necessarily valid data).";
CM_ SG_ 352 ChargeScheduleTargetLevel "DATABASE_CANDIDATE: physical interpretation unverified; capture/layout evidence reported separately. PSA-RE bits 1.4-1.3. Memorized target charge level of the charging schedule Upstream default raw=1 (not necessarily valid data).";
CM_ SG_ 352 Unused1 "DATABASE_CANDIDATE: physical interpretation unverified; capture/layout evidence reported separately. PSA-RE bits 1.5. ";
CM_ SG_ 352 ChargeTypeMenuStatus "DATABASE_CANDIDATE: physical interpretation unverified; capture/layout evidence reported separately. PSA-RE bits 1.6. Memorized charging type menu status (immediate or deferred) Upstream default raw=0 (not necessarily valid data).";
CM_ SG_ 352 ChargeScheduleStatusAvailability "DATABASE_CANDIDATE: physical interpretation unverified; capture/layout evidence reported separately. PSA-RE bits 1.7. Availability of the charging schedule status information Upstream default raw=0 (not necessarily valid data).";
CM_ BO_ 353 "VEHICLE_LAYOUT_UNKNOWN: No supported EV interpretation: all353 captured payloads are 00 00 3C 00 00 00 FD; upstream oil/fuel labels are not vehicle measurements and no battery mapping is established. Raw bytes only; original interpretation retained in source JSON. INFO-DIV CAN, 125000 bit/s; CAN ID 0x161. PSA-RE title: BSI_GAUGES. Fuel level, oil level and oil temperature gauges from the BSI. Source: https://github.com/prototux/PSA-RE/blob/67f7581e7622410efdbb29c7eda3b86982b9b450/buses/AEE2010.full/LS.INFO-DIV/161.yml. Source sender alternatives: BSI; physical TX/gateway forwarding not verified. Observed 1175 frames in info_apka.csv,info_buzeni_obc.csv,info_charging.csv,info_standby.csv,info_start_jizda.csv,infocan.csv; DLCs [7]. Unresolved alternative source layouts preserved in source JSON. ";
CM_ SG_ 353 RawByte7 "RAW. PSA-RE bits 7.7-7.0. Unmapped/padding bits, no physical interpretation.";
CM_ SG_ 353 RawByte6 "RAW. PSA-RE bits 6.7-6.0. Unmapped/padding bits, no physical interpretation.";
CM_ SG_ 353 RawByte5 "RAW. PSA-RE bits 5.7-5.0. Unmapped/padding bits, no physical interpretation.";
CM_ SG_ 353 RawByte4 "RAW. PSA-RE bits 4.7-4.0. Unmapped/padding bits, no physical interpretation.";
CM_ SG_ 353 RawByte3 "RAW. PSA-RE bits 3.7-3.0. Unmapped/padding bits, no physical interpretation.";
CM_ SG_ 353 RawByte2 "RAW. PSA-RE bits 2.7-2.0. Unmapped/padding bits, no physical interpretation.";
CM_ SG_ 353 RawByte1 "RAW. PSA-RE bits 1.7-1.0. Unmapped/padding bits, no physical interpretation.";
CM_ BO_ 354 "DATABASE_CANDIDATE: physical interpretation unverified; capture/layout evidence reported separately. INFO-DIV CAN, 125000 bit/s; CAN ID 0x162. PSA-RE title: CD_CHANGER_STATUS. CD changer status: access, disk read errors, MP3 support and per-disk availability (CD1-CD6). Source: https://github.com/prototux/PSA-RE/blob/67f7581e7622410efdbb29c7eda3b86982b9b450/buses/AEE2010.full/LS.INFO-DIV/162.yml. Source sender alternatives: ICSV,CDC; physical TX/gateway forwarding not verified. ";
CM_ SG_ 354 CdcFrontPushButtonNumber "DATABASE_CANDIDATE: physical interpretation unverified; capture/layout evidence reported separately. PSA-RE bits 7.3-7.0. Number of the push-button pressed (front-loading changer only) Upstream default raw=0 (not necessarily valid data).";
CM_ SG_ 354 CdcEjectLoadButtonPressed "DATABASE_CANDIDATE: physical interpretation unverified; capture/layout evidence reported separately. PSA-RE bits 7.5-7.4. Eject or Load command push-button pressed Upstream default raw=0 (not necessarily valid data).";
CM_ SG_ 354 Unused5 "DATABASE_CANDIDATE: physical interpretation unverified; capture/layout evidence reported separately. PSA-RE bits 7.7-7.6. ";
CM_ SG_ 354 DiscPresenceCd1 "DATABASE_CANDIDATE: physical interpretation unverified; capture/layout evidence reported separately. PSA-RE bits 6.0. Presence of disc 1 in the changer Upstream default raw=0 (not necessarily valid data).";
CM_ SG_ 354 DiscPresenceCd2 "DATABASE_CANDIDATE: physical interpretation unverified; capture/layout evidence reported separately. PSA-RE bits 6.1. Presence of disc 2 in the changer Upstream default raw=0 (not necessarily valid data).";
CM_ SG_ 354 DiscPresenceCd3 "DATABASE_CANDIDATE: physical interpretation unverified; capture/layout evidence reported separately. PSA-RE bits 6.2. Presence of disc 3 in the changer Upstream default raw=0 (not necessarily valid data).";
CM_ SG_ 354 DiscPresenceCd4 "DATABASE_CANDIDATE: physical interpretation unverified; capture/layout evidence reported separately. PSA-RE bits 6.3. Presence of disc 4 in the changer Upstream default raw=0 (not necessarily valid data).";
CM_ SG_ 354 DiscPresenceCd5 "DATABASE_CANDIDATE: physical interpretation unverified; capture/layout evidence reported separately. PSA-RE bits 6.4. Presence of disc 5 in the changer Upstream default raw=0 (not necessarily valid data).";
CM_ SG_ 354 DiscPresenceCd6 "DATABASE_CANDIDATE: physical interpretation unverified; capture/layout evidence reported separately. PSA-RE bits 6.5. Presence of disc 6 in the changer Upstream default raw=0 (not necessarily valid data).";
CM_ SG_ 354 DiscPresenceCd7 "DATABASE_CANDIDATE: physical interpretation unverified; capture/layout evidence reported separately. PSA-RE bits 6.6. Presence of disc 7 in the changer Upstream default raw=0 (not necessarily valid data).";
CM_ SG_ 354 DiscPresenceCd8 "DATABASE_CANDIDATE: physical interpretation unverified; capture/layout evidence reported separately. PSA-RE bits 6.7. Presence of disc 8 in the changer Upstream default raw=0 (not necessarily valid data).";
CM_ SG_ 354 Unused4 "DATABASE_CANDIDATE: physical interpretation unverified; capture/layout evidence reported separately. PSA-RE bits 5.7-5.0. ";
CM_ SG_ 354 CdcCurrentDiscNumber "DATABASE_CANDIDATE: physical interpretation unverified; capture/layout evidence reported separately. PSA-RE bits 4.3-4.0. Current disc number Upstream default raw=0 (not necessarily valid data).";
CM_ SG_ 354 Unused3 "DATABASE_CANDIDATE: physical interpretation unverified; capture/layout evidence reported separately. PSA-RE bits 4.5-4.4. ";
CM_ SG_ 354 CdcAccessType "DATABASE_CANDIDATE: physical interpretation unverified; capture/layout evidence reported separately. PSA-RE bits 4.7-4.6. CD changer access type Upstream default raw=0 (not necessarily valid data).";
CM_ SG_ 354 CdcCapacity "DATABASE_CANDIDATE: physical interpretation unverified; capture/layout evidence reported separately. PSA-RE bits 3.3-3.0. CD changer capacity, 1 to 15 discs Upstream default raw=1 (not necessarily valid data).";
CM_ SG_ 354 CdcMagazinePresence "DATABASE_CANDIDATE: physical interpretation unverified; capture/layout evidence reported separately. PSA-RE bits 3.4. CD changer magazine presence Upstream default raw=1 (not necessarily valid data).";
CM_ SG_ 354 CdcDoorStatus "DATABASE_CANDIDATE: physical interpretation unverified; capture/layout evidence reported separately. PSA-RE bits 3.5. CD changer door status Upstream default raw=0 (not necessarily valid data).";
CM_ SG_ 354 CdcStatusError "DATABASE_CANDIDATE: physical interpretation unverified; capture/layout evidence reported separately. PSA-RE bits 3.6. CDC status (normal or error) Upstream default raw=0 (not necessarily valid data).";
CM_ SG_ 354 CdcOverTemperature "DATABASE_CANDIDATE: physical interpretation unverified; capture/layout evidence reported separately. PSA-RE bits 3.7. CD changer over-temperature status Upstream default raw=0 (not necessarily valid data).";
CM_ SG_ 354 CdcPlayerState "DATABASE_CANDIDATE: physical interpretation unverified; capture/layout evidence reported separately. PSA-RE bits 2.2-2.0. CD player state (CDC) Upstream default raw=0 (not necessarily valid data).";
CM_ SG_ 354 CdcTextAvailable "DATABASE_CANDIDATE: physical interpretation unverified; capture/layout evidence reported separately. PSA-RE bits 2.3. CD text available (CD-Text or ID3 tag) Upstream default raw=0 (not necessarily valid data).";
CM_ SG_ 354 DiscError "DATABASE_CANDIDATE: physical interpretation unverified; capture/layout evidence reported separately. PSA-RE bits 2.4. Disc unreadable Upstream default raw=0 (not necessarily valid data).";
CM_ SG_ 354 DiscUpsideDown "DATABASE_CANDIDATE: physical interpretation unverified; capture/layout evidence reported separately. PSA-RE bits 2.5. Disc inserted upside down Upstream default raw=0 (not necessarily valid data).";
CM_ SG_ 354 CdcMp3Support "DATABASE_CANDIDATE: physical interpretation unverified; capture/layout evidence reported separately. PSA-RE bits 2.6. CD changer supporting MP3/WMA/AAC formats";
CM_ SG_ 354 CdcDiscAccessInProgress "DATABASE_CANDIDATE: physical interpretation unverified; capture/layout evidence reported separately. PSA-RE bits 2.7. CD changer access to the disc in progress Upstream default raw=0 (not necessarily valid data).";
CM_ SG_ 354 Unused2 "DATABASE_CANDIDATE: physical interpretation unverified; capture/layout evidence reported separately. PSA-RE bits 1.1-1.0. ";
CM_ SG_ 354 CdcTrackDiscRepeatState "DATABASE_CANDIDATE: physical interpretation unverified; capture/layout evidence reported separately. PSA-RE bits 1.3-1.2. Track/disc repeat state (CDC) Upstream default raw=0 (not necessarily valid data).";
CM_ SG_ 354 Unused1 "DATABASE_CANDIDATE: physical interpretation unverified; capture/layout evidence reported separately. PSA-RE bits 1.4. ";
CM_ SG_ 354 CdcChangerType "DATABASE_CANDIDATE: physical interpretation unverified; capture/layout evidence reported separately. PSA-RE bits 1.5. CD changer type Upstream default raw=0 (not necessarily valid data).";
CM_ SG_ 354 CdcListModeRequest "DATABASE_CANDIDATE: physical interpretation unverified; capture/layout evidence reported separately. PSA-RE bits 1.6. CD/MP3 list mode request Upstream default raw=0 (not necessarily valid data).";
CM_ SG_ 354 CdcOnOffStatus "DATABASE_CANDIDATE: physical interpretation unverified; capture/layout evidence reported separately. PSA-RE bits 1.7. CD changer on/off status Upstream default raw=0 (not necessarily valid data).";
CM_ BO_ 355 "DATABASE_CANDIDATE: physical interpretation unverified; capture/layout evidence reported separately. INFO-DIV CAN, 125000 bit/s; CAN ID 0x163. PSA-RE title: KML_LIST_NONE. Family of frames sharing this ID: the content depends on SENT_LIST_TYPE Source: https://github.com/prototux/PSA-RE/blob/67f7581e7622410efdbb29c7eda3b86982b9b450/buses/AEE2010.full/LS.INFO-DIV/163.yml. Source sender alternatives: ICSV,RAD; physical TX/gateway forwarding not verified. WIRE ISO-TP ONLY: normal addressing candidate, maximum Classical CAN DLC 8; actual DLC may be shorter. Data includes padding. No reassembly, text, DID or application-layer decoding. Original application layouts are preserved in source JSON; do not decode them at wire offsets. Unresolved alternative source layouts preserved in source JSON. ";
CM_ SG_ 355 FlowPadding5 "TRANSPORT_CANDIDATE: normal-addressing ISO-TP. PSA-RE bits 8.7-8.0. ";
CM_ SG_ 355 FirstData6 "TRANSPORT_CANDIDATE: normal-addressing ISO-TP. PSA-RE bits 8.7-8.0. ";
CM_ SG_ 355 UnknownData7 "TRANSPORT_CANDIDATE: normal-addressing ISO-TP. PSA-RE bits 8.7-8.0. ";
CM_ SG_ 355 ConsecutiveData7 "TRANSPORT_CANDIDATE: normal-addressing ISO-TP. PSA-RE bits 8.7-8.0. ";
CM_ SG_ 355 SingleData7 "TRANSPORT_CANDIDATE: normal-addressing ISO-TP. PSA-RE bits 8.7-8.0. ";
CM_ SG_ 355 FlowPadding4 "TRANSPORT_CANDIDATE: normal-addressing ISO-TP. PSA-RE bits 7.7-7.0. ";
CM_ SG_ 355 FirstData5 "TRANSPORT_CANDIDATE: normal-addressing ISO-TP. PSA-RE bits 7.7-7.0. ";
CM_ SG_ 355 UnknownData6 "TRANSPORT_CANDIDATE: normal-addressing ISO-TP. PSA-RE bits 7.7-7.0. ";
CM_ SG_ 355 ConsecutiveData6 "TRANSPORT_CANDIDATE: normal-addressing ISO-TP. PSA-RE bits 7.7-7.0. ";
CM_ SG_ 355 SingleData6 "TRANSPORT_CANDIDATE: normal-addressing ISO-TP. PSA-RE bits 7.7-7.0. ";
CM_ SG_ 355 FlowPadding3 "TRANSPORT_CANDIDATE: normal-addressing ISO-TP. PSA-RE bits 6.7-6.0. ";
CM_ SG_ 355 FirstData4 "TRANSPORT_CANDIDATE: normal-addressing ISO-TP. PSA-RE bits 6.7-6.0. ";
CM_ SG_ 355 UnknownData5 "TRANSPORT_CANDIDATE: normal-addressing ISO-TP. PSA-RE bits 6.7-6.0. ";
CM_ SG_ 355 ConsecutiveData5 "TRANSPORT_CANDIDATE: normal-addressing ISO-TP. PSA-RE bits 6.7-6.0. ";
CM_ SG_ 355 SingleData5 "TRANSPORT_CANDIDATE: normal-addressing ISO-TP. PSA-RE bits 6.7-6.0. ";
CM_ SG_ 355 FlowPadding2 "TRANSPORT_CANDIDATE: normal-addressing ISO-TP. PSA-RE bits 5.7-5.0. ";
CM_ SG_ 355 FirstData3 "TRANSPORT_CANDIDATE: normal-addressing ISO-TP. PSA-RE bits 5.7-5.0. ";
CM_ SG_ 355 UnknownData4 "TRANSPORT_CANDIDATE: normal-addressing ISO-TP. PSA-RE bits 5.7-5.0. ";
CM_ SG_ 355 ConsecutiveData4 "TRANSPORT_CANDIDATE: normal-addressing ISO-TP. PSA-RE bits 5.7-5.0. ";
CM_ SG_ 355 SingleData4 "TRANSPORT_CANDIDATE: normal-addressing ISO-TP. PSA-RE bits 5.7-5.0. ";
CM_ SG_ 355 FlowPadding1 "TRANSPORT_CANDIDATE: normal-addressing ISO-TP. PSA-RE bits 4.7-4.0. ";
CM_ SG_ 355 FirstData2 "TRANSPORT_CANDIDATE: normal-addressing ISO-TP. PSA-RE bits 4.7-4.0. ";
CM_ SG_ 355 UnknownData3 "TRANSPORT_CANDIDATE: normal-addressing ISO-TP. PSA-RE bits 4.7-4.0. ";
CM_ SG_ 355 ConsecutiveData3 "TRANSPORT_CANDIDATE: normal-addressing ISO-TP. PSA-RE bits 4.7-4.0. ";
CM_ SG_ 355 SingleData3 "TRANSPORT_CANDIDATE: normal-addressing ISO-TP. PSA-RE bits 4.7-4.0. ";
CM_ SG_ 355 FirstData1 "TRANSPORT_CANDIDATE: normal-addressing ISO-TP. PSA-RE bits 3.7-3.0. ";
CM_ SG_ 355 UnknownData2 "TRANSPORT_CANDIDATE: normal-addressing ISO-TP. PSA-RE bits 3.7-3.0. ";
CM_ SG_ 355 ConsecutiveData2 "TRANSPORT_CANDIDATE: normal-addressing ISO-TP. PSA-RE bits 3.7-3.0. ";
CM_ SG_ 355 SingleData2 "TRANSPORT_CANDIDATE: normal-addressing ISO-TP. PSA-RE bits 3.7-3.0. ";
CM_ SG_ 355 SeparationTimeRaw "TRANSPORT_CANDIDATE: normal-addressing ISO-TP. PSA-RE bits 3.7-3.0. Raw STmin code; 0xF1..0xF9 are not milliseconds.";
CM_ SG_ 355 UnknownData1 "TRANSPORT_CANDIDATE: normal-addressing ISO-TP. PSA-RE bits 2.7-2.0. ";
CM_ SG_ 355 ConsecutiveData1 "TRANSPORT_CANDIDATE: normal-addressing ISO-TP. PSA-RE bits 2.7-2.0. ";
CM_ SG_ 355 SingleData1 "TRANSPORT_CANDIDATE: normal-addressing ISO-TP. PSA-RE bits 2.7-2.0. ";
CM_ SG_ 355 BlockSize "TRANSPORT_CANDIDATE: normal-addressing ISO-TP. PSA-RE bits 2.7-2.0. ";
CM_ SG_ 355 UnknownPciLow "TRANSPORT_CANDIDATE: normal-addressing ISO-TP. PSA-RE bits 1.3-1.0. ";
CM_ SG_ 355 FlowStatus "TRANSPORT_CANDIDATE: normal-addressing ISO-TP. PSA-RE bits 1.3-1.0. ";
CM_ SG_ 355 ConsecutiveSequence "TRANSPORT_CANDIDATE: normal-addressing ISO-TP. PSA-RE bits 1.3-1.0. ";
CM_ SG_ 355 FirstFrameLength "TRANSPORT_CANDIDATE: normal-addressing ISO-TP. PSA-RE bits 1.3-2.0. 12-bit declared PDU length; not a reassembled value.";
CM_ SG_ 355 SingleFrameLength "TRANSPORT_CANDIDATE: normal-addressing ISO-TP. PSA-RE bits 1.3-1.0. Declared data length; not a validity check.";
CM_ SG_ 355 IsoTpFrameType "TRANSPORT_CANDIDATE: normal-addressing ISO-TP. PSA-RE bits 1.7-1.4. PCI high nibble; normal addressing candidate.";
CM_ BO_ 357 "DATABASE_CANDIDATE: physical interpretation unverified; capture/layout evidence reported separately. INFO-DIV CAN, 125000 bit/s; CAN ID 0x165. PSA-RE title: RADIO_STATUS_GENERAL. Radio general status: amplifier on, dual-tuner mode, CD/CD-changer source, compressed audio format, Hi-Fi, mute, source presence and power state. Source: https://github.com/prototux/PSA-RE/blob/67f7581e7622410efdbb29c7eda3b86982b9b450/buses/AEE2010.full/LS.INFO-DIV/165.yml. Source sender alternatives: BTEL,ICSV,RAD,OVIP; physical TX/gateway forwarding not verified. Observed 5878 frames in info_apka.csv,info_buzeni_obc.csv,info_charging.csv,info_standby.csv,info_start_jizda.csv,infocan.csv; DLCs [6]. SOURCE_DLC_MISMATCH: source 5, observed/exported 6. Fitting fields retained; additional bytes raw. ";
CM_ SG_ 357 RawByte6 "RAW. PSA-RE bits 6.7-6.0. Unmapped/padding bits, no physical interpretation.";
CM_ SG_ 357 Unused1 "DATABASE_CANDIDATE: physical interpretation unverified; capture/layout evidence reported separately. PSA-RE bits 5.6-5.0. ";
CM_ SG_ 357 MixedChannelMute "DATABASE_CANDIDATE: physical interpretation unverified; capture/layout evidence reported separately. PSA-RE bits 5.7. Mute of the additional channel for functionnal sound Upstream default raw=0 (not necessarily valid data).";
CM_ SG_ 357 BtSrc "DATABASE_CANDIDATE: physical interpretation unverified; capture/layout evidence reported separately. PSA-RE bits 4.1-4.0. Bluetooth source present on the radio Upstream default raw=0 (not necessarily valid data).";
CM_ SG_ 357 SupportedDigitalRadio "DATABASE_CANDIDATE: physical interpretation unverified; capture/layout evidence reported separately. PSA-RE bits 4.4-4.2. Supported types of digital radio Upstream default raw=0 (not necessarily valid data).";
CM_ SG_ 357 CdAudioCompression "DATABASE_CANDIDATE: physical interpretation unverified; capture/layout evidence reported separately. PSA-RE bits 4.7-4.5. Audio compression formats supported by the CD Upstream default raw=0 (not necessarily valid data).";
CM_ SG_ 357 NoSrc "DATABASE_CANDIDATE: physical interpretation unverified; capture/layout evidence reported separately. PSA-RE bits 3.2-3.0. Change of audio source rejected Upstream default raw=0 (not necessarily valid data).";
CM_ SG_ 357 SrcKml "DATABASE_CANDIDATE: physical interpretation unverified; capture/layout evidence reported separately. PSA-RE bits 3.3. Switching to source with KML configuration Upstream default raw=0 (not necessarily valid data).";
CM_ SG_ 357 SrcSel "DATABASE_CANDIDATE: physical interpretation unverified; capture/layout evidence reported separately. PSA-RE bits 3.6-3.4. Audio source selected Upstream default raw=0 (not necessarily valid data).";
CM_ SG_ 357 SrcMix "DATABASE_CANDIDATE: physical interpretation unverified; capture/layout evidence reported separately. PSA-RE bits 3.7. Mixing the source with the current source Upstream default raw=0 (not necessarily valid data).";
CM_ SG_ 357 TimeshiftHoldRequest "DATABASE_CANDIDATE: physical interpretation unverified; capture/layout evidence reported separately. PSA-RE bits 2.0. Request network hold on to bufferise the radio Upstream default raw=0 (not necessarily valid data).";
CM_ SG_ 357 UsbSrc "DATABASE_CANDIDATE: physical interpretation unverified; capture/layout evidence reported separately. PSA-RE bits 2.2-2.1. USB source present on the car radio Upstream default raw=0 (not necessarily valid data).";
CM_ SG_ 357 CdcSrc "DATABASE_CANDIDATE: physical interpretation unverified; capture/layout evidence reported separately. PSA-RE bits 2.4-2.3. CD charger source present on the car radio Upstream default raw=0 (not necessarily valid data).";
CM_ SG_ 357 CdSrc "DATABASE_CANDIDATE: physical interpretation unverified; capture/layout evidence reported separately. PSA-RE bits 2.6-2.5. Internal CD source present on the car radio Upstream default raw=0 (not necessarily valid data).";
CM_ SG_ 357 TunSrc "DATABASE_CANDIDATE: physical interpretation unverified; capture/layout evidence reported separately. PSA-RE bits 2.7. Tuner source present on the car radio Upstream default raw=0 (not necessarily valid data).";
CM_ SG_ 357 UsbSourceType "DATABASE_CANDIDATE: physical interpretation unverified; capture/layout evidence reported separately. PSA-RE bits 1.0. type of selected USB source Upstream default raw=0 (not necessarily valid data).";
CM_ SG_ 357 DynamicsCompression "DATABASE_CANDIDATE: physical interpretation unverified; capture/layout evidence reported separately. PSA-RE bits 1.1. Dynamics compression Upstream default raw=0 (not necessarily valid data).";
CM_ SG_ 357 HifiVersion "DATABASE_CANDIDATE: physical interpretation unverified; capture/layout evidence reported separately. PSA-RE bits 1.2. HIFI version Upstream default raw=0 (not necessarily valid data).";
CM_ SG_ 357 BiTuner "DATABASE_CANDIDATE: physical interpretation unverified; capture/layout evidence reported separately. PSA-RE bits 1.3. Car radio equipped with a 2nd tuner Upstream default raw=0 (not necessarily valid data).";
CM_ SG_ 357 RadioOnRequest "DATABASE_CANDIDATE: physical interpretation unverified; capture/layout evidence reported separately. PSA-RE bits 1.4. request ON radio Upstream default raw=0 (not necessarily valid data).";
CM_ SG_ 357 Mute "DATABASE_CANDIDATE: physical interpretation unverified; capture/layout evidence reported separately. PSA-RE bits 1.5. Enabled/non-enabled mute Upstream default raw=0 (not necessarily valid data).";
CM_ SG_ 357 AmpliOn "DATABASE_CANDIDATE: physical interpretation unverified; capture/layout evidence reported separately. PSA-RE bits 1.6. Status of the car radio in relation to dissemination of sound, including auxiliary sources (PAS, TEL ...) Upstream default raw=0 (not necessarily valid data).";
CM_ SG_ 357 Power "DATABASE_CANDIDATE: physical interpretation unverified; capture/layout evidence reported separately. PSA-RE bits 1.7. Car radio state Upstream default raw=0 (not necessarily valid data).";
CM_ BO_ 358 "DATABASE_CANDIDATE: physical interpretation unverified; capture/layout evidence reported separately. INFO-DIV CAN, 125000 bit/s; CAN ID 0x166. PSA-RE title: PARKING_CAMERA_STATUS. Parking camera status: view display mode, activation state, wheel reference counters and detected parking slot data. Source: https://github.com/prototux/PSA-RE/blob/67f7581e7622410efdbb29c7eda3b86982b9b450/buses/AEE2010.full/LS.INFO-DIV/166.yml. Source sender alternatives: AVP; physical TX/gateway forwarding not verified. ";
CM_ SG_ 358 ParkingSlotId "DATABASE_CANDIDATE: physical interpretation unverified; capture/layout evidence reported separately. PSA-RE bits 8.2-8.0. Identifier of the measured parking space Upstream default raw=0 (not necessarily valid data).";
CM_ SG_ 358 ParkingSlotDepthSource "DATABASE_CANDIDATE: physical interpretation unverified; capture/layout evidence reported separately. PSA-RE bits 8.3. Whether the parking space depth is estimated or measured Upstream default raw=0 (not necessarily valid data).";
CM_ SG_ 358 VparkCameraStatus "DATABASE_CANDIDATE: physical interpretation unverified; capture/layout evidence reported separately. PSA-RE bits 8.5-8.4. VPARK functionality state, with the type of operational camera Upstream default raw=0 (not necessarily valid data).";
CM_ SG_ 358 RearRightWheelAngularPosition "DATABASE_CANDIDATE: physical interpretation unverified; capture/layout evidence reported separately. PSA-RE bits 7.2-8.6. Angular position of the rear right road wheel at the moment of measurement Upstream default raw=0 (not necessarily valid data).";
CM_ SG_ 358 RearLeftWheelAngularPosition "DATABASE_CANDIDATE: physical interpretation unverified; capture/layout evidence reported separately. PSA-RE bits 7.7-7.3. Angular position of the rear left road wheel at the moment of measurement Upstream default raw=0 (not necessarily valid data).";
CM_ SG_ 358 ParkingSlotPositionY "DATABASE_CANDIDATE: physical interpretation unverified; capture/layout evidence reported separately. PSA-RE bits 6.6-6.0. Y position of the measured parking space relative to the vehicle centre axis Upstream default raw=63 (not necessarily valid data).";
CM_ SG_ 358 ParkingSlotPositionX "DATABASE_CANDIDATE: physical interpretation unverified; capture/layout evidence reported separately. PSA-RE bits 5.7-6.7. X position of the measured parking space relative to the vehicle centre axis Upstream default raw=255 (not necessarily valid data).";
CM_ SG_ 358 ParkingSlotOrientation "DATABASE_CANDIDATE: physical interpretation unverified; capture/layout evidence reported separately. PSA-RE bits 4.7-4.0. Orientation of the measured parking space relative to the vehicle centre axis Upstream default raw=0 (not necessarily valid data).";
CM_ SG_ 358 ParkingSlotLength "DATABASE_CANDIDATE: physical interpretation unverified; capture/layout evidence reported separately. PSA-RE bits 3.7-3.0. Length of the measured parking space Upstream default raw=0 (not necessarily valid data).";
CM_ SG_ 358 ParkingSlotDepth "DATABASE_CANDIDATE: physical interpretation unverified; capture/layout evidence reported separately. PSA-RE bits 2.7-2.0. Depth of the measured parking space Upstream default raw=0 (not necessarily valid data).";
CM_ SG_ 358 VparkAutoDisplay "DATABASE_CANDIDATE: physical interpretation unverified; capture/layout evidence reported separately. PSA-RE bits 1.0. Automatic VPARK display Upstream default raw=0 (not necessarily valid data).";
CM_ SG_ 358 VparkActivationStatus "DATABASE_CANDIDATE: physical interpretation unverified; capture/layout evidence reported separately. PSA-RE bits 1.1. VPARK activation state Upstream default raw=0 (not necessarily valid data).";
CM_ SG_ 358 VparkViewDisplayRequest "DATABASE_CANDIDATE: physical interpretation unverified; capture/layout evidence reported separately. PSA-RE bits 1.4-1.2. Request for VPARK display, with the type of view to show in contextual view Upstream default raw=0 (not necessarily valid data).";
CM_ SG_ 358 ParkCameraViewDisplay "DATABASE_CANDIDATE: physical interpretation unverified; capture/layout evidence reported separately. PSA-RE bits 1.6-1.5. Front parking assist (AVP) view display Upstream default raw=0 (not necessarily valid data).";
CM_ SG_ 358 AvpActivationStatus "DATABASE_CANDIDATE: physical interpretation unverified; capture/layout evidence reported separately. PSA-RE bits 1.7. Front parking assist (AVP) activation status Upstream default raw=0 (not necessarily valid data).";
CM_ BO_ 359 "DATABASE_CANDIDATE: physical interpretation unverified; capture/layout evidence reported separately. INFO-DIV CAN, 125000 bit/s; CAN ID 0x167. PSA-RE title: EMF_CONTROL_DATA. EMF control data, used for network supervision (sent every 100 ms while awake): action, emergency call, climate preconditioning request, reset requests, total odometer and interactive message pointer. Source: https://github.com/prototux/PSA-RE/blob/67f7581e7622410efdbb29c7eda3b86982b9b450/buses/AEE2010.full/LS.INFO-DIV/167.yml. Source sender alternatives: BTEL,EMF; physical TX/gateway forwarding not verified. ";
CM_ SG_ 359 Unused3 "DATABASE_CANDIDATE: physical interpretation unverified; capture/layout evidence reported separately. PSA-RE bits 8.1-8.0. ";
CM_ SG_ 359 MainMenuSelection "DATABASE_CANDIDATE: physical interpretation unverified; capture/layout evidence reported separately. PSA-RE bits 8.4-8.2. Menu selected by the user Upstream default raw=7 (not necessarily valid data).";
CM_ SG_ 359 WifiSettingsUpdateAck "DATABASE_CANDIDATE: physical interpretation unverified; capture/layout evidence reported separately. PSA-RE bits 8.5. Acknowledgement that Wi-Fi settings have been received Upstream default raw=0 (not necessarily valid data).";
CM_ SG_ 359 HmiUserAction "DATABASE_CANDIDATE: physical interpretation unverified; capture/layout evidence reported separately. PSA-RE bits 8.7-8.6. User action on the display Upstream default raw=0 (not necessarily valid data).";
CM_ SG_ 359 HmiPopupIdAck "DATABASE_CANDIDATE: physical interpretation unverified; capture/layout evidence reported separately. PSA-RE bits 7.7-7.0. Acknowledgement of the pop-up identifier to display Upstream default raw=0 (not necessarily valid data).";
CM_ SG_ 359 InteractiveMessagePointer "DATABASE_CANDIDATE: physical interpretation unverified; capture/layout evidence reported separately. PSA-RE bits 5.6-6.0. Displayed message requiring a driver response Upstream default raw=32767 (not necessarily valid data).";
CM_ SG_ 359 CheckStopRequest "DATABASE_CANDIDATE: physical interpretation unverified; capture/layout evidence reported separately. PSA-RE bits 5.7. Request to stop the Check function Upstream default raw=0 (not necessarily valid data).";
CM_ SG_ 359 TotalMileageForTrip "DATABASE_CANDIDATE: physical interpretation unverified; capture/layout evidence reported separately. PSA-RE bits 3.7-4.0. Total trip mileage Raw invalid=65535; numeric DBC decoders may still scale it: check raw before use. Upstream default raw=65535 (not necessarily valid data).";
CM_ SG_ 359 PreconditioningDelay "DATABASE_CANDIDATE: physical interpretation unverified; capture/layout evidence reported separately. PSA-RE bits 2.3-2.0. Preconditioning delay Upstream default raw=6 (not necessarily valid data).";
CM_ SG_ 359 TelematicsFunctionsStatus "DATABASE_CANDIDATE: physical interpretation unverified; capture/layout evidence reported separately. PSA-RE bits 2.4. Telematics functions status Upstream default raw=0 (not necessarily valid data).";
CM_ SG_ 359 BlackPanelStatus "DATABASE_CANDIDATE: physical interpretation unverified; capture/layout evidence reported separately. PSA-RE bits 2.5. Black Panel (dark display) function status Upstream default raw=0 (not necessarily valid data).";
CM_ SG_ 359 Unused2 "DATABASE_CANDIDATE: physical interpretation unverified; capture/layout evidence reported separately. PSA-RE bits 2.6. ";
CM_ SG_ 359 ThermalPreconditioningRequest "DATABASE_CANDIDATE: physical interpretation unverified; capture/layout evidence reported separately. PSA-RE bits 2.7. Thermal preconditioning request Upstream default raw=0 (not necessarily valid data).";
CM_ SG_ 359 Unused1 "DATABASE_CANDIDATE: physical interpretation unverified; capture/layout evidence reported separately. PSA-RE bits 1.2-1.0. ";
CM_ SG_ 359 ResetMaintenanceRequest "DATABASE_CANDIDATE: physical interpretation unverified; capture/layout evidence reported separately. PSA-RE bits 1.3. Maintenance counter reset request Upstream default raw=1 (not necessarily valid data).";
CM_ SG_ 359 EmergencyCallStatus "DATABASE_CANDIDATE: physical interpretation unverified; capture/layout evidence reported separately. PSA-RE bits 1.4. Emergency call (eCall) in progress Upstream default raw=0 (not necessarily valid data).";
CM_ SG_ 359 CheckAlertRequest "DATABASE_CANDIDATE: physical interpretation unverified; capture/layout evidence reported separately. PSA-RE bits 1.5. Request to recall active alerts (Check function) Upstream default raw=0 (not necessarily valid data).";
CM_ SG_ 359 ResetTotalsTrip2Request "DATABASE_CANDIDATE: physical interpretation unverified; capture/layout evidence reported separately. PSA-RE bits 1.6. Reset request for trip 2 cumulative totals Upstream default raw=0 (not necessarily valid data).";
CM_ SG_ 359 ResetTotalsTrip1Request "DATABASE_CANDIDATE: physical interpretation unverified; capture/layout evidence reported separately. PSA-RE bits 1.7. Reset request for trip 1 cumulative totals Upstream default raw=0 (not necessarily valid data).";
CM_ BO_ 360 "DATABASE_CANDIDATE: physical interpretation unverified; capture/layout evidence reported separately. INFO-DIV CAN, 125000 bit/s; CAN ID 0x168. PSA-RE title: COMBINE_ALERTS_INDICATORS. Instrument cluster telltale lamp commands sent on change: ABS, ASR, steering assist, parking brake and service/system faults. Source: https://github.com/prototux/PSA-RE/blob/67f7581e7622410efdbb29c7eda3b86982b9b450/buses/AEE2010.full/LS.INFO-DIV/168.yml. Source sender alternatives: BSI; physical TX/gateway forwarding not verified. Observed 2939 frames in info_apka.csv,info_buzeni_obc.csv,info_charging.csv,info_standby.csv,info_start_jizda.csv,infocan.csv; DLCs [8]. ";
CM_ SG_ 360 HadcWarningLightControl "DATABASE_CANDIDATE: physical interpretation unverified; capture/layout evidence reported separately. PSA-RE bits 8.1-8.0. HADC (hill descent control) indicator light control Upstream default raw=0 (not necessarily valid data).";
CM_ SG_ 360 LaneDepartureWarningLightRequest "DATABASE_CANDIDATE: physical interpretation unverified; capture/layout evidence reported separately. PSA-RE bits 8.3-8.2. Lane departure warning light request Upstream default raw=0 (not necessarily valid data).";
CM_ SG_ 360 HudRightWarningLight "DATABASE_CANDIDATE: physical interpretation unverified; capture/layout evidence reported separately. PSA-RE bits 8.4. Right warning light control in the head-up display Upstream default raw=0 (not necessarily valid data).";
CM_ SG_ 360 HudLeftWarningLight "DATABASE_CANDIDATE: physical interpretation unverified; capture/layout evidence reported separately. PSA-RE bits 8.5. Left warning light control in the head-up display Upstream default raw=0 (not necessarily valid data).";
CM_ SG_ 360 FarcIndicatorRequest "DATABASE_CANDIDATE: physical interpretation unverified; capture/layout evidence reported separately. PSA-RE bits 8.7-8.6. FARC warning light request (off/steady/blinking) Upstream default raw=0 (not necessarily valid data).";
CM_ SG_ 360 BrakeAssistFault "DATABASE_CANDIDATE: physical interpretation unverified; capture/layout evidence reported separately. PSA-RE bits 7.0. Brake assist fault indicator request Upstream default raw=0 (not necessarily valid data).";
CM_ SG_ 360 CurrentGearDrive "DATABASE_CANDIDATE: physical interpretation unverified; capture/layout evidence reported separately. PSA-RE bits 7.4-7.1. Gear to display in drive mode Upstream default raw=0 (not necessarily valid data).";
CM_ SG_ 360 EmfAvailabilityAck "DATABASE_CANDIDATE: physical interpretation unverified; capture/layout evidence reported separately. PSA-RE bits 7.5. EMF availability acknowledgment Upstream default raw=1 (not necessarily valid data).";
CM_ SG_ 360 AmbienceButtonAuthorization "DATABASE_CANDIDATE: physical interpretation unverified; capture/layout evidence reported separately. PSA-RE bits 7.6. Ambient lighting button input authorization Upstream default raw=1 (not necessarily valid data).";
CM_ SG_ 360 HudEnabled "DATABASE_CANDIDATE: physical interpretation unverified; capture/layout evidence reported separately. PSA-RE bits 7.7. Head-up display operation enabled Upstream default raw=0 (not necessarily valid data).";
CM_ SG_ 360 Unused1 "DATABASE_CANDIDATE: physical interpretation unverified; capture/layout evidence reported separately. PSA-RE bits 6.0. ";
CM_ SG_ 360 DaFaultLightTestMode "DATABASE_CANDIDATE: physical interpretation unverified; capture/layout evidence reported separately. PSA-RE bits 6.1. Red DA fault indicator request state, test mode Upstream default raw=0 (not necessarily valid data).";
CM_ SG_ 360 DaFault2UpdateBit "DATABASE_CANDIDATE: physical interpretation unverified; capture/layout evidence reported separately. PSA-RE bits 6.2. Update bit for DA fault type (DA_FAULT_TYPE) Upstream default raw=0 (not necessarily valid data).";
CM_ SG_ 360 DaFaultType "DATABASE_CANDIDATE: physical interpretation unverified; capture/layout evidence reported separately. PSA-RE bits 6.4-6.3. DA fault type Upstream default raw=0 (not necessarily valid data).";
CM_ SG_ 360 DaFault1UpdateBit "DATABASE_CANDIDATE: physical interpretation unverified; capture/layout evidence reported separately. PSA-RE bits 6.5. Update bit for DA fault indicator request (DA_FAULT_INDICATOR_REQUEST) Upstream default raw=0 (not necessarily valid data).";
CM_ SG_ 360 DaFaultIndicatorRequest "DATABASE_CANDIDATE: physical interpretation unverified; capture/layout evidence reported separately. PSA-RE bits 6.7-6.6. DA fault indicator request state (off/red/orange) Upstream default raw=0 (not necessarily valid data).";
CM_ SG_ 360 SttIndicator "DATABASE_CANDIDATE: physical interpretation unverified; capture/layout evidence reported separately. PSA-RE bits 5.1-5.0. Stop & Start indicator light request Upstream default raw=0 (not necessarily valid data).";
CM_ SG_ 360 PowerSteeringFault "DATABASE_CANDIDATE: physical interpretation unverified; capture/layout evidence reported separately. PSA-RE bits 5.2. Power steering fault Upstream default raw=0 (not necessarily valid data).";
CM_ SG_ 360 Caar "DATABASE_CANDIDATE: physical interpretation unverified; capture/layout evidence reported separately. PSA-RE bits 5.4-5.3. CAAR indicator light request Upstream default raw=0 (not necessarily valid data).";
CM_ SG_ 360 SafetyFault "DATABASE_CANDIDATE: physical interpretation unverified; capture/layout evidence reported separately. PSA-RE bits 5.5. Passive safety fault Upstream default raw=0 (not necessarily valid data).";
CM_ SG_ 360 TurnLightsFault "DATABASE_CANDIDATE: physical interpretation unverified; capture/layout evidence reported separately. PSA-RE bits 5.6. Cornering light fault Upstream default raw=0 (not necessarily valid data).";
CM_ SG_ 360 DieselWaterFault "DATABASE_CANDIDATE: physical interpretation unverified; capture/layout evidence reported separately. PSA-RE bits 5.7. Water in diesel fuel filter fault Upstream default raw=0 (not necessarily valid data).";
CM_ SG_ 360 MilRequestUpdateBit "DATABASE_CANDIDATE: physical interpretation unverified; capture/layout evidence reported separately. PSA-RE bits 4.0. Update bit for MIL indicator request Upstream default raw=0 (not necessarily valid data).";
CM_ SG_ 360 EobdFault "DATABASE_CANDIDATE: physical interpretation unverified; capture/layout evidence reported separately. PSA-RE bits 4.1. EOBD fault (MIL) Upstream default raw=0 (not necessarily valid data).";
CM_ SG_ 360 BrakesFault "DATABASE_CANDIDATE: physical interpretation unverified; capture/layout evidence reported separately. PSA-RE bits 4.2. Brake pad wear fault Upstream default raw=0 (not necessarily valid data).";
CM_ SG_ 360 GearboxFault "DATABASE_CANDIDATE: physical interpretation unverified; capture/layout evidence reported separately. PSA-RE bits 4.3. Gearbox fault Upstream default raw=0 (not necessarily valid data).";
CM_ SG_ 360 AsrFault "DATABASE_CANDIDATE: physical interpretation unverified; capture/layout evidence reported separately. PSA-RE bits 4.4. ESP/ASR (traction control) fault Upstream default raw=0 (not necessarily valid data).";
CM_ SG_ 360 AbsFault "DATABASE_CANDIDATE: physical interpretation unverified; capture/layout evidence reported separately. PSA-RE bits 4.5. ABS/EHB fault Upstream default raw=0 (not necessarily valid data).";
CM_ SG_ 360 ParkingBrakeTightFault "DATABASE_CANDIDATE: physical interpretation unverified; capture/layout evidence reported separately. PSA-RE bits 4.6. Electric parking brake application fault Upstream default raw=0 (not necessarily valid data).";
CM_ SG_ 360 ParkingBrakeFault "DATABASE_CANDIDATE: physical interpretation unverified; capture/layout evidence reported separately. PSA-RE bits 4.7. Electric parking brake system fault Upstream default raw=0 (not necessarily valid data).";
CM_ SG_ 360 AlternatorFault "DATABASE_CANDIDATE: physical interpretation unverified; capture/layout evidence reported separately. PSA-RE bits 3.0. Alternator fault Upstream default raw=0 (not necessarily valid data).";
CM_ SG_ 360 BatteryFault "DATABASE_CANDIDATE: physical interpretation unverified; capture/layout evidence reported separately. PSA-RE bits 3.1. Battery charge fault Upstream default raw=0 (not necessarily valid data).";
CM_ SG_ 360 SuspensionFault "DATABASE_CANDIDATE: physical interpretation unverified; capture/layout evidence reported separately. PSA-RE bits 3.2. Serious suspension fault Upstream default raw=0 (not necessarily valid data).";
CM_ SG_ 360 RefEhbFault "DATABASE_CANDIDATE: physical interpretation unverified; capture/layout evidence reported separately. PSA-RE bits 3.3. Serious REF/EHB fault Upstream default raw=0 (not necessarily valid data).";
CM_ SG_ 360 RearRearRightSeatbeltBlink "DATABASE_CANDIDATE: physical interpretation unverified; capture/layout evidence reported separately. PSA-RE bits 3.4. Third row right seatbelt reminder light blinking request Upstream default raw=0 (not necessarily valid data).";
CM_ SG_ 360 RearRearRightSeatbelt "DATABASE_CANDIDATE: physical interpretation unverified; capture/layout evidence reported separately. PSA-RE bits 3.5. Third row right seatbelt reminder Upstream default raw=0 (not necessarily valid data).";
CM_ SG_ 360 RearRearLeftSeatbeltBlink "DATABASE_CANDIDATE: physical interpretation unverified; capture/layout evidence reported separately. PSA-RE bits 3.6. Third row left seatbelt reminder light blinking request Upstream default raw=0 (not necessarily valid data).";
CM_ SG_ 360 RearRearLeftSeatbelt "DATABASE_CANDIDATE: physical interpretation unverified; capture/layout evidence reported separately. PSA-RE bits 3.7. Third row left seatbelt reminder Upstream default raw=0 (not necessarily valid data).";
CM_ SG_ 360 PlusStartIndicator "DATABASE_CANDIDATE: physical interpretation unverified; capture/layout evidence reported separately. PSA-RE bits 2.0. +START indicator light control Upstream default raw=0 (not necessarily valid data).";
CM_ SG_ 360 MaxRpmLvl2 "DATABASE_CANDIDATE: physical interpretation unverified; capture/layout evidence reported separately. PSA-RE bits 2.1. Engine speed limit threshold 2 LED request Upstream default raw=0 (not necessarily valid data).";
CM_ SG_ 360 MaxRpmLvl1 "DATABASE_CANDIDATE: physical interpretation unverified; capture/layout evidence reported separately. PSA-RE bits 2.2. Engine speed limit threshold 1 LED request Upstream default raw=0 (not necessarily valid data).";
CM_ SG_ 360 AutoWipeStatus "DATABASE_CANDIDATE: physical interpretation unverified; capture/layout evidence reported separately. PSA-RE bits 2.3. Automatic wiping function status Upstream default raw=0 (not necessarily valid data).";
CM_ SG_ 360 ParticleFilterFault "DATABASE_CANDIDATE: physical interpretation unverified; capture/layout evidence reported separately. PSA-RE bits 2.4. Particulate filter indicator light request Upstream default raw=0 (not necessarily valid data).";
CM_ SG_ 360 PollutionFault "DATABASE_CANDIDATE: physical interpretation unverified; capture/layout evidence reported separately. PSA-RE bits 2.5. Serious pollution fault (catalyst risk) Upstream default raw=0 (not necessarily valid data).";
CM_ SG_ 360 PunctureAlert "DATABASE_CANDIDATE: physical interpretation unverified; capture/layout evidence reported separately. PSA-RE bits 2.6. Puncture alert Upstream default raw=0 (not necessarily valid data).";
CM_ SG_ 360 UnderinflationAlert "DATABASE_CANDIDATE: physical interpretation unverified; capture/layout evidence reported separately. PSA-RE bits 2.7. Tyre underinflation alert Upstream default raw=0 (not necessarily valid data).";
CM_ SG_ 360 DsgFaultLightState "DATABASE_CANDIDATE: physical interpretation unverified; capture/layout evidence reported separately. PSA-RE bits 1.0. Tyre pressure monitoring fault light state Upstream default raw=0 (not necessarily valid data).";
CM_ SG_ 360 ColdEngineAlert "DATABASE_CANDIDATE: physical interpretation unverified; capture/layout evidence reported separately. PSA-RE bits 1.1. Cold engine alert Upstream default raw=0 (not necessarily valid data).";
CM_ SG_ 360 BrakeLevelAlert "DATABASE_CANDIDATE: physical interpretation unverified; capture/layout evidence reported separately. PSA-RE bits 1.2. Brake fluid level alert Upstream default raw=0 (not necessarily valid data).";
CM_ SG_ 360 OilPressureAlert "DATABASE_CANDIDATE: physical interpretation unverified; capture/layout evidence reported separately. PSA-RE bits 1.3. Oil pressure alert Upstream default raw=0 (not necessarily valid data).";
CM_ SG_ 360 OilLevelAlert "DATABASE_CANDIDATE: physical interpretation unverified; capture/layout evidence reported separately. PSA-RE bits 1.4. Oil level alert Upstream default raw=0 (not necessarily valid data).";
CM_ SG_ 360 CoolantLevelAlert "DATABASE_CANDIDATE: physical interpretation unverified; capture/layout evidence reported separately. PSA-RE bits 1.5. Coolant level alert Upstream default raw=0 (not necessarily valid data).";
CM_ SG_ 360 GearboxRatioCount "DATABASE_CANDIDATE: physical interpretation unverified; capture/layout evidence reported separately. PSA-RE bits 1.6. Number of gearbox ratios to display Upstream default raw=0 (not necessarily valid data).";
CM_ SG_ 360 CoolantTemperatureAlert "DATABASE_CANDIDATE: physical interpretation unverified; capture/layout evidence reported separately. PSA-RE bits 1.7. Coolant temperature alert Upstream default raw=0 (not necessarily valid data).";
CM_ BO_ 361 "DATABASE_CANDIDATE: physical interpretation unverified; capture/layout evidence reported separately. INFO-DIV CAN, 125000 bit/s; CAN ID 0x169. PSA-RE title: NAV_ARRIVAL_INFO. Navigation guidance data to the display: altitude, arrival estimate, remaining distance and calculation status. Source: https://github.com/prototux/PSA-RE/blob/67f7581e7622410efdbb29c7eda3b86982b9b450/buses/AEE2010.full/LS.INFO-DIV/169.yml. Source sender alternatives: ICSV,BTEL,OVIP; physical TX/gateway forwarding not verified. ";
CM_ SG_ 361 ArrivalMinute "DATABASE_CANDIDATE: physical interpretation unverified; capture/layout evidence reported separately. PSA-RE bits 8.5-8.0. Minutes of arrival Raw invalid=63; numeric DBC decoders may still scale it: check raw before use. Upstream default raw=63 (not necessarily valid data).";
CM_ SG_ 361 ArrivalHour "DATABASE_CANDIDATE: physical interpretation unverified; capture/layout evidence reported separately. PSA-RE bits 7.2-8.6. Hour of arrival Raw invalid=31; numeric DBC decoders may still scale it: check raw before use. Upstream default raw=31 (not necessarily valid data).";
CM_ SG_ 361 DistanceToNextManeuver "DATABASE_CANDIDATE: physical interpretation unverified; capture/layout evidence reported separately. PSA-RE bits 6.7-7.3. Distance to the next navigation manoeuvre Upstream default raw=8191 (not necessarily valid data).";
CM_ SG_ 361 DistanceToDestination "DATABASE_CANDIDATE: physical interpretation unverified; capture/layout evidence reported separately. PSA-RE bits 4.5-5.0. Distance to destination Upstream default raw=16383 (not necessarily valid data).";
CM_ SG_ 361 ArrivalTimePictogramRequest "DATABASE_CANDIDATE: physical interpretation unverified; capture/layout evidence reported separately. PSA-RE bits 4.6. Arrival-time pictogram request Upstream default raw=0 (not necessarily valid data).";
CM_ SG_ 361 FinishFlagPictogramRequest "DATABASE_CANDIDATE: physical interpretation unverified; capture/layout evidence reported separately. PSA-RE bits 4.7. Finish (arrival) flag pictogram request Upstream default raw=0 (not necessarily valid data).";
CM_ SG_ 361 VehicleAltitude "DATABASE_CANDIDATE: physical interpretation unverified; capture/layout evidence reported separately. PSA-RE bits 2.5-3.0. Vehicle altitude Raw invalid=16383; numeric DBC decoders may still scale it: check raw before use. Upstream default raw=16383 (not necessarily valid data).";
CM_ SG_ 361 Unused1 "DATABASE_CANDIDATE: physical interpretation unverified; capture/layout evidence reported separately. PSA-RE bits 2.7-2.6. ";
CM_ SG_ 361 ManeuverPictogramNumber "DATABASE_CANDIDATE: physical interpretation unverified; capture/layout evidence reported separately. PSA-RE bits 1.5-1.0. Number of the manoeuvre pictogram to display (correspondence between number and graphic is ECU-specific) Upstream default raw=0 (not necessarily valid data).";
CM_ SG_ 361 NavigationCalculationInProgress "DATABASE_CANDIDATE: physical interpretation unverified; capture/layout evidence reported separately. PSA-RE bits 1.6. Navigation route calculation in progress Upstream default raw=0 (not necessarily valid data).";
CM_ SG_ 361 NavigationStatus "DATABASE_CANDIDATE: physical interpretation unverified; capture/layout evidence reported separately. PSA-RE bits 1.7. Navigation status Upstream default raw=0 (not necessarily valid data).";
CM_ BO_ 385 "DATABASE_CANDIDATE: physical interpretation unverified; capture/layout evidence reported separately. INFO-DIV CAN, 125000 bit/s; CAN ID 0x181. PSA-RE title: UID_TABLE_ENCRYPTED_TO_SDCM. Encrypted identifier table transmitted to the SDCM Source: https://github.com/prototux/PSA-RE/blob/67f7581e7622410efdbb29c7eda3b86982b9b450/buses/AEE2010.full/LS.INFO-DIV/181.yml. Source sender alternatives: BSI; physical TX/gateway forwarding not verified. WIRE ISO-TP ONLY: normal addressing candidate, maximum Classical CAN DLC 8; actual DLC may be shorter. Data includes padding. No reassembly, text, DID or application-layer decoding. Original application layouts are preserved in source JSON; do not decode them at wire offsets. Unresolved alternative source layouts preserved in source JSON. ";
CM_ SG_ 385 FlowPadding5 "TRANSPORT_CANDIDATE: normal-addressing ISO-TP. PSA-RE bits 8.7-8.0. ";
CM_ SG_ 385 FirstData6 "TRANSPORT_CANDIDATE: normal-addressing ISO-TP. PSA-RE bits 8.7-8.0. ";
CM_ SG_ 385 UnknownData7 "TRANSPORT_CANDIDATE: normal-addressing ISO-TP. PSA-RE bits 8.7-8.0. ";
CM_ SG_ 385 ConsecutiveData7 "TRANSPORT_CANDIDATE: normal-addressing ISO-TP. PSA-RE bits 8.7-8.0. ";
CM_ SG_ 385 SingleData7 "TRANSPORT_CANDIDATE: normal-addressing ISO-TP. PSA-RE bits 8.7-8.0. ";
CM_ SG_ 385 FlowPadding4 "TRANSPORT_CANDIDATE: normal-addressing ISO-TP. PSA-RE bits 7.7-7.0. ";
CM_ SG_ 385 FirstData5 "TRANSPORT_CANDIDATE: normal-addressing ISO-TP. PSA-RE bits 7.7-7.0. ";
CM_ SG_ 385 UnknownData6 "TRANSPORT_CANDIDATE: normal-addressing ISO-TP. PSA-RE bits 7.7-7.0. ";
CM_ SG_ 385 ConsecutiveData6 "TRANSPORT_CANDIDATE: normal-addressing ISO-TP. PSA-RE bits 7.7-7.0. ";
CM_ SG_ 385 SingleData6 "TRANSPORT_CANDIDATE: normal-addressing ISO-TP. PSA-RE bits 7.7-7.0. ";
CM_ SG_ 385 FlowPadding3 "TRANSPORT_CANDIDATE: normal-addressing ISO-TP. PSA-RE bits 6.7-6.0. ";
CM_ SG_ 385 FirstData4 "TRANSPORT_CANDIDATE: normal-addressing ISO-TP. PSA-RE bits 6.7-6.0. ";
CM_ SG_ 385 UnknownData5 "TRANSPORT_CANDIDATE: normal-addressing ISO-TP. PSA-RE bits 6.7-6.0. ";
CM_ SG_ 385 ConsecutiveData5 "TRANSPORT_CANDIDATE: normal-addressing ISO-TP. PSA-RE bits 6.7-6.0. ";
CM_ SG_ 385 SingleData5 "TRANSPORT_CANDIDATE: normal-addressing ISO-TP. PSA-RE bits 6.7-6.0. ";
CM_ SG_ 385 FlowPadding2 "TRANSPORT_CANDIDATE: normal-addressing ISO-TP. PSA-RE bits 5.7-5.0. ";
CM_ SG_ 385 FirstData3 "TRANSPORT_CANDIDATE: normal-addressing ISO-TP. PSA-RE bits 5.7-5.0. ";
CM_ SG_ 385 UnknownData4 "TRANSPORT_CANDIDATE: normal-addressing ISO-TP. PSA-RE bits 5.7-5.0. ";
CM_ SG_ 385 ConsecutiveData4 "TRANSPORT_CANDIDATE: normal-addressing ISO-TP. PSA-RE bits 5.7-5.0. ";
CM_ SG_ 385 SingleData4 "TRANSPORT_CANDIDATE: normal-addressing ISO-TP. PSA-RE bits 5.7-5.0. ";
CM_ SG_ 385 FlowPadding1 "TRANSPORT_CANDIDATE: normal-addressing ISO-TP. PSA-RE bits 4.7-4.0. ";
CM_ SG_ 385 FirstData2 "TRANSPORT_CANDIDATE: normal-addressing ISO-TP. PSA-RE bits 4.7-4.0. ";
CM_ SG_ 385 UnknownData3 "TRANSPORT_CANDIDATE: normal-addressing ISO-TP. PSA-RE bits 4.7-4.0. ";
CM_ SG_ 385 ConsecutiveData3 "TRANSPORT_CANDIDATE: normal-addressing ISO-TP. PSA-RE bits 4.7-4.0. ";
CM_ SG_ 385 SingleData3 "TRANSPORT_CANDIDATE: normal-addressing ISO-TP. PSA-RE bits 4.7-4.0. ";
CM_ SG_ 385 FirstData1 "TRANSPORT_CANDIDATE: normal-addressing ISO-TP. PSA-RE bits 3.7-3.0. ";
CM_ SG_ 385 UnknownData2 "TRANSPORT_CANDIDATE: normal-addressing ISO-TP. PSA-RE bits 3.7-3.0. ";
CM_ SG_ 385 ConsecutiveData2 "TRANSPORT_CANDIDATE: normal-addressing ISO-TP. PSA-RE bits 3.7-3.0. ";
CM_ SG_ 385 SingleData2 "TRANSPORT_CANDIDATE: normal-addressing ISO-TP. PSA-RE bits 3.7-3.0. ";
CM_ SG_ 385 SeparationTimeRaw "TRANSPORT_CANDIDATE: normal-addressing ISO-TP. PSA-RE bits 3.7-3.0. Raw STmin code; 0xF1..0xF9 are not milliseconds.";
CM_ SG_ 385 UnknownData1 "TRANSPORT_CANDIDATE: normal-addressing ISO-TP. PSA-RE bits 2.7-2.0. ";
CM_ SG_ 385 ConsecutiveData1 "TRANSPORT_CANDIDATE: normal-addressing ISO-TP. PSA-RE bits 2.7-2.0. ";
CM_ SG_ 385 SingleData1 "TRANSPORT_CANDIDATE: normal-addressing ISO-TP. PSA-RE bits 2.7-2.0. ";
CM_ SG_ 385 BlockSize "TRANSPORT_CANDIDATE: normal-addressing ISO-TP. PSA-RE bits 2.7-2.0. ";
CM_ SG_ 385 UnknownPciLow "TRANSPORT_CANDIDATE: normal-addressing ISO-TP. PSA-RE bits 1.3-1.0. ";
CM_ SG_ 385 FlowStatus "TRANSPORT_CANDIDATE: normal-addressing ISO-TP. PSA-RE bits 1.3-1.0. ";
CM_ SG_ 385 ConsecutiveSequence "TRANSPORT_CANDIDATE: normal-addressing ISO-TP. PSA-RE bits 1.3-1.0. ";
CM_ SG_ 385 FirstFrameLength "TRANSPORT_CANDIDATE: normal-addressing ISO-TP. PSA-RE bits 1.3-2.0. 12-bit declared PDU length; not a reassembled value.";
CM_ SG_ 385 SingleFrameLength "TRANSPORT_CANDIDATE: normal-addressing ISO-TP. PSA-RE bits 1.3-1.0. Declared data length; not a validity check.";
CM_ SG_ 385 IsoTpFrameType "TRANSPORT_CANDIDATE: normal-addressing ISO-TP. PSA-RE bits 1.7-1.4. PCI high nibble; normal addressing candidate.";
CM_ BO_ 387 "DATABASE_CANDIDATE: physical interpretation unverified; capture/layout evidence reported separately. INFO-DIV CAN, 125000 bit/s; CAN ID 0x183. PSA-RE title: ODI_EVENT_PACKET_BUFFER. Opaque data buffer of the embedded diagnostics interface (ODI) between the telematics unit and the diagnostic tool: event packet. Source: https://github.com/prototux/PSA-RE/blob/67f7581e7622410efdbb29c7eda3b86982b9b450/buses/AEE2010.full/LS.INFO-DIV/183.yml. Source sender alternatives: MDS; physical TX/gateway forwarding not verified. ";
CM_ SG_ 387 OdiEventPacketBuffer "DATABASE_CANDIDATE: physical interpretation unverified; capture/layout evidence reported separately. PSA-RE bits 1.7-4.0. Open Display Interface (ODI) event packet buffer";
CM_ BO_ 403 "DATABASE_CANDIDATE: physical interpretation unverified; capture/layout evidence reported separately. INFO-DIV CAN, 125000 bit/s; CAN ID 0x193. PSA-RE title: RF_KEY_CODE_MESSAGE_BML. Rolling-code fragments from the remote control (RF key fob), reassembled in reception order. Source: https://github.com/prototux/PSA-RE/blob/67f7581e7622410efdbb29c7eda3b86982b9b450/buses/AEE2010.full/LS.INFO-DIV/193.yml. Source sender alternatives: SDCM; physical TX/gateway forwarding not verified. ";
CM_ SG_ 403 HfReceiverCode8 "DATABASE_CANDIDATE: physical interpretation unverified; capture/layout evidence reported separately. PSA-RE bits 8.7-8.0. HF (remote control) receiver code.";
CM_ SG_ 403 HfReceiverCode7 "DATABASE_CANDIDATE: physical interpretation unverified; capture/layout evidence reported separately. PSA-RE bits 7.7-7.0. HF (remote control) receiver code.";
CM_ SG_ 403 HfReceiverCode6 "DATABASE_CANDIDATE: physical interpretation unverified; capture/layout evidence reported separately. PSA-RE bits 6.7-6.0. HF (remote control) receiver code.";
CM_ SG_ 403 HfReceiverCode5 "DATABASE_CANDIDATE: physical interpretation unverified; capture/layout evidence reported separately. PSA-RE bits 5.7-5.0. HF (remote control) receiver code.";
CM_ SG_ 403 HfReceiverCode4 "DATABASE_CANDIDATE: physical interpretation unverified; capture/layout evidence reported separately. PSA-RE bits 4.7-4.0. HF (remote control) receiver code.";
CM_ SG_ 403 HfReceiverCode3 "DATABASE_CANDIDATE: physical interpretation unverified; capture/layout evidence reported separately. PSA-RE bits 3.7-3.0. HF (remote control) receiver code.";
CM_ SG_ 403 HfReceiverCode2 "DATABASE_CANDIDATE: physical interpretation unverified; capture/layout evidence reported separately. PSA-RE bits 2.7-2.0. HF (remote control) receiver code.";
CM_ SG_ 403 HfReceiverCode1 "DATABASE_CANDIDATE: physical interpretation unverified; capture/layout evidence reported separately. PSA-RE bits 1.7-1.0. HF (remote control) receiver code.";
CM_ BO_ 411 "DATABASE_CANDIDATE: physical interpretation unverified; capture/layout evidence reported separately. INFO-DIV CAN, 125000 bit/s; CAN ID 0x19B. PSA-RE title: SPEED_LIMITER_PRESETS_STATUS. Speed limiter preset speeds (6 slots) and availability of cruise/limiter information. Source: https://github.com/prototux/PSA-RE/blob/67f7581e7622410efdbb29c7eda3b86982b9b450/buses/AEE2010.full/LS.INFO-DIV/19B.yml. Source sender alternatives: CMB,ICSV,BTEL,OVIP; physical TX/gateway forwarding not verified. ";
CM_ SG_ 411 Unused1 "DATABASE_CANDIDATE: physical interpretation unverified; capture/layout evidence reported separately. PSA-RE bits 7.6-7.0. ";
CM_ SG_ 411 CruiseMenuInfoAvailability "DATABASE_CANDIDATE: physical interpretation unverified; capture/layout evidence reported separately. PSA-RE bits 7.7. Cruise control menu information availability Upstream default raw=0 (not necessarily valid data).";
CM_ SG_ 411 Stop6SpeedValue "DATABASE_CANDIDATE: physical interpretation unverified; capture/layout evidence reported separately. PSA-RE bits 6.7-6.0. Value of stop 6 speed Raw invalid=255; numeric DBC decoders may still scale it: check raw before use. Upstream default raw=0 (not necessarily valid data).";
CM_ SG_ 411 SpeedLimitZone5Speed "DATABASE_CANDIDATE: physical interpretation unverified; capture/layout evidence reported separately. PSA-RE bits 5.7-5.0. Speed limiter zone 5 speed value Upstream default raw=0 (not necessarily valid data).";
CM_ SG_ 411 SpeedLimitZone4Speed "DATABASE_CANDIDATE: physical interpretation unverified; capture/layout evidence reported separately. PSA-RE bits 4.7-4.0. Speed limiter zone 4 speed value Upstream default raw=0 (not necessarily valid data).";
CM_ SG_ 411 SpeedLimitZone3Speed "DATABASE_CANDIDATE: physical interpretation unverified; capture/layout evidence reported separately. PSA-RE bits 3.7-3.0. Speed limiter zone 3 speed value Upstream default raw=0 (not necessarily valid data).";
CM_ SG_ 411 SpeedLimitZone2Speed "DATABASE_CANDIDATE: physical interpretation unverified; capture/layout evidence reported separately. PSA-RE bits 2.7-2.0. Speed limiter zone 2 speed value Upstream default raw=0 (not necessarily valid data).";
CM_ SG_ 411 SpeedLimitZone1Speed "DATABASE_CANDIDATE: physical interpretation unverified; capture/layout evidence reported separately. PSA-RE bits 1.7-1.0. Speed limiter zone 1 speed value Upstream default raw=0 (not necessarily valid data).";
CM_ BO_ 412 "DATABASE_CANDIDATE: physical interpretation unverified; capture/layout evidence reported separately. INFO-DIV CAN, 125000 bit/s; CAN ID 0x19C. PSA-RE title: ECO_DRIVING_ADVICE. Eco-driving coach advice messages: distance/time until the next free-wheeling opportunity and active advice text flags. Source: https://github.com/prototux/PSA-RE/blob/67f7581e7622410efdbb29c7eda3b86982b9b450/buses/AEE2010.full/LS.INFO-DIV/19C.yml. Source sender alternatives: BSI; physical TX/gateway forwarding not verified. Observed 587 frames in info_apka.csv,info_buzeni_obc.csv,info_charging.csv,info_standby.csv,info_start_jizda.csv,infocan.csv; DLCs [8]. Unresolved alternative source layouts preserved in source JSON. ";
CM_ SG_ 412 Unused3 "DATABASE_CANDIDATE: physical interpretation unverified; capture/layout evidence reported separately. PSA-RE bits 8.0. ";
CM_ SG_ 412 EcocoachAdvice31Active "DATABASE_CANDIDATE: physical interpretation unverified; capture/layout evidence reported separately. PSA-RE bits 8.1. Eco Coaching advice 31 active Upstream default raw=0 (not necessarily valid data).";
CM_ SG_ 412 EcocoachAdvice30Active "DATABASE_CANDIDATE: physical interpretation unverified; capture/layout evidence reported separately. PSA-RE bits 8.2. Eco Coaching advice 30 active Upstream default raw=0 (not necessarily valid data).";
CM_ SG_ 412 EcocoachAdvice29Active "DATABASE_CANDIDATE: physical interpretation unverified; capture/layout evidence reported separately. PSA-RE bits 8.3. Eco Coaching advice 29 active Upstream default raw=0 (not necessarily valid data).";
CM_ SG_ 412 EcocoachAdvice28Active "DATABASE_CANDIDATE: physical interpretation unverified; capture/layout evidence reported separately. PSA-RE bits 8.4. Eco Coaching advice 28 active Upstream default raw=0 (not necessarily valid data).";
CM_ SG_ 412 EcocoachAdvice27Active "DATABASE_CANDIDATE: physical interpretation unverified; capture/layout evidence reported separately. PSA-RE bits 8.5. Eco Coaching advice 27 active Upstream default raw=0 (not necessarily valid data).";
CM_ SG_ 412 EcocoachAdvice26Active "DATABASE_CANDIDATE: physical interpretation unverified; capture/layout evidence reported separately. PSA-RE bits 8.6. Eco Coaching advice 26 active Upstream default raw=0 (not necessarily valid data).";
CM_ SG_ 412 EcocoachAdvice25Active "DATABASE_CANDIDATE: physical interpretation unverified; capture/layout evidence reported separately. PSA-RE bits 8.7. Eco Coaching advice 25 active Upstream default raw=0 (not necessarily valid data).";
CM_ SG_ 412 EcocoachAdvice24Active "DATABASE_CANDIDATE: physical interpretation unverified; capture/layout evidence reported separately. PSA-RE bits 7.0. Eco Coaching advice 24 active Upstream default raw=0 (not necessarily valid data).";
CM_ SG_ 412 EcocoachAdvice23Active "DATABASE_CANDIDATE: physical interpretation unverified; capture/layout evidence reported separately. PSA-RE bits 7.1. Eco Coaching advice 23 active Upstream default raw=0 (not necessarily valid data).";
CM_ SG_ 412 EcocoachAdvice22Active "DATABASE_CANDIDATE: physical interpretation unverified; capture/layout evidence reported separately. PSA-RE bits 7.2. Eco Coaching advice 22 active Upstream default raw=0 (not necessarily valid data).";
CM_ SG_ 412 EcocoachAdvice21Active "DATABASE_CANDIDATE: physical interpretation unverified; capture/layout evidence reported separately. PSA-RE bits 7.3. Eco Coaching advice 21 active Upstream default raw=0 (not necessarily valid data).";
CM_ SG_ 412 EcocoachAdvice20Active "DATABASE_CANDIDATE: physical interpretation unverified; capture/layout evidence reported separately. PSA-RE bits 7.4. Eco Coaching advice 20 active Upstream default raw=0 (not necessarily valid data).";
CM_ SG_ 412 EcocoachAdvice19Active "DATABASE_CANDIDATE: physical interpretation unverified; capture/layout evidence reported separately. PSA-RE bits 7.5. Eco Coaching advice 19 active Upstream default raw=0 (not necessarily valid data).";
CM_ SG_ 412 EcocoachAdvice18Active "DATABASE_CANDIDATE: physical interpretation unverified; capture/layout evidence reported separately. PSA-RE bits 7.6. Eco Coaching advice 18 active Upstream default raw=0 (not necessarily valid data).";
CM_ SG_ 412 EcocoachAdvice17Active "DATABASE_CANDIDATE: physical interpretation unverified; capture/layout evidence reported separately. PSA-RE bits 7.7. Eco Coaching advice 17 active Upstream default raw=0 (not necessarily valid data).";
CM_ SG_ 412 EcocoachAdvice16Active "DATABASE_CANDIDATE: physical interpretation unverified; capture/layout evidence reported separately. PSA-RE bits 6.0. Eco Coaching advice 16 active Upstream default raw=0 (not necessarily valid data).";
CM_ SG_ 412 EcocoachAdvice15Active "DATABASE_CANDIDATE: physical interpretation unverified; capture/layout evidence reported separately. PSA-RE bits 6.1. Eco Coaching advice 15 active Upstream default raw=0 (not necessarily valid data).";
CM_ SG_ 412 EcocoachAdvice14Active "DATABASE_CANDIDATE: physical interpretation unverified; capture/layout evidence reported separately. PSA-RE bits 6.2. Eco Coaching advice 14 active Upstream default raw=0 (not necessarily valid data).";
CM_ SG_ 412 EcocoachAdvice13Active "DATABASE_CANDIDATE: physical interpretation unverified; capture/layout evidence reported separately. PSA-RE bits 6.3. Eco Coaching advice 13 active Upstream default raw=0 (not necessarily valid data).";
CM_ SG_ 412 EcocoachAdvice12Active "DATABASE_CANDIDATE: physical interpretation unverified; capture/layout evidence reported separately. PSA-RE bits 6.4. Eco Coaching advice 12 active Upstream default raw=0 (not necessarily valid data).";
CM_ SG_ 412 EcocoachAdvice11Active "DATABASE_CANDIDATE: physical interpretation unverified; capture/layout evidence reported separately. PSA-RE bits 6.5. Eco Coaching advice 11 active Upstream default raw=0 (not necessarily valid data).";
CM_ SG_ 412 EcocoachAdvice10Active "DATABASE_CANDIDATE: physical interpretation unverified; capture/layout evidence reported separately. PSA-RE bits 6.6. Eco Coaching advice 10 active Upstream default raw=0 (not necessarily valid data).";
CM_ SG_ 412 EcocoachAdvice9Active "DATABASE_CANDIDATE: physical interpretation unverified; capture/layout evidence reported separately. PSA-RE bits 6.7. Eco Coaching advice 9 active Upstream default raw=0 (not necessarily valid data).";
CM_ SG_ 412 EcocoachAdvice8Active "DATABASE_CANDIDATE: physical interpretation unverified; capture/layout evidence reported separately. PSA-RE bits 5.0. Eco Coaching advice 8 active Upstream default raw=0 (not necessarily valid data).";
CM_ SG_ 412 EcocoachAdvice7Active "DATABASE_CANDIDATE: physical interpretation unverified; capture/layout evidence reported separately. PSA-RE bits 5.1. Eco Coaching advice 7 active Upstream default raw=0 (not necessarily valid data).";
CM_ SG_ 412 EcocoachAdvice6Active "DATABASE_CANDIDATE: physical interpretation unverified; capture/layout evidence reported separately. PSA-RE bits 5.2. Eco Coaching advice 6 active Upstream default raw=0 (not necessarily valid data).";
CM_ SG_ 412 EcocoachAdvice5Active "DATABASE_CANDIDATE: physical interpretation unverified; capture/layout evidence reported separately. PSA-RE bits 5.3. Eco Coaching advice 5 active Upstream default raw=0 (not necessarily valid data).";
CM_ SG_ 412 EcocoachAdvice4Active "DATABASE_CANDIDATE: physical interpretation unverified; capture/layout evidence reported separately. PSA-RE bits 5.4. Eco Coaching advice 4 active Upstream default raw=0 (not necessarily valid data).";
CM_ SG_ 412 EcocoachAdvice3Active "DATABASE_CANDIDATE: physical interpretation unverified; capture/layout evidence reported separately. PSA-RE bits 5.5. Eco Coaching advice 3 active Upstream default raw=0 (not necessarily valid data).";
CM_ SG_ 412 EcocoachAdvice2Active "DATABASE_CANDIDATE: physical interpretation unverified; capture/layout evidence reported separately. PSA-RE bits 5.6. Eco Coaching advice 2 active Upstream default raw=0 (not necessarily valid data).";
CM_ SG_ 412 EcocoachAdvice1Active "DATABASE_CANDIDATE: physical interpretation unverified; capture/layout evidence reported separately. PSA-RE bits 5.7. Eco Coaching advice 1 active Upstream default raw=0 (not necessarily valid data).";
CM_ SG_ 412 Unused2 "DATABASE_CANDIDATE: physical interpretation unverified; capture/layout evidence reported separately. PSA-RE bits 4.0. ";
CM_ SG_ 412 EcocoachFreewheelTime "DATABASE_CANDIDATE: physical interpretation unverified; capture/layout evidence reported separately. PSA-RE bits 3.7-4.1. Time spent freewheeling during the Eco Coaching trip Raw invalid=32767; numeric DBC decoders may still scale it: check raw before use. Upstream default raw=0 (not necessarily valid data).";
CM_ SG_ 412 Unused1 "DATABASE_CANDIDATE: physical interpretation unverified; capture/layout evidence reported separately. PSA-RE bits 2.1-2.0. ";
CM_ SG_ 412 EcocoachFreewheelDistance "DATABASE_CANDIDATE: physical interpretation unverified; capture/layout evidence reported separately. PSA-RE bits 1.7-2.2. Distance covered in freewheeling during the Eco Coaching trip Raw invalid=16383; numeric DBC decoders may still scale it: check raw before use. Upstream default raw=0 (not necessarily valid data).";
CM_ BO_ 416 "DATABASE_CANDIDATE: physical interpretation unverified; capture/layout evidence reported separately. INFO-DIV CAN, 125000 bit/s; CAN ID 0x1A0. PSA-RE title: CD_CHANGER_CONFIG_STATUS. CD changer configuration and status: scan, random track and repertoire settings. Source: https://github.com/prototux/PSA-RE/blob/67f7581e7622410efdbb29c7eda3b86982b9b450/buses/AEE2010.full/LS.INFO-DIV/1A0.yml. Source sender alternatives: ICSV,CDC; physical TX/gateway forwarding not verified. ";
CM_ SG_ 416 Unused1 "DATABASE_CANDIDATE: physical interpretation unverified; capture/layout evidence reported separately. PSA-RE bits 2.3-2.0. ";
CM_ SG_ 416 CdChangerAlbumShuffleStatus "DATABASE_CANDIDATE: physical interpretation unverified; capture/layout evidence reported separately. PSA-RE bits 2.4. CD changer album shuffle mode activation status Upstream default raw=0 (not necessarily valid data).";
CM_ SG_ 416 CdChangerAlbumShuffleOption "DATABASE_CANDIDATE: physical interpretation unverified; capture/layout evidence reported separately. PSA-RE bits 2.6-2.5. CD changer album shuffle mode option Upstream default raw=0 (not necessarily valid data).";
CM_ SG_ 416 RepeatEnabled "DATABASE_CANDIDATE: physical interpretation unverified; capture/layout evidence reported separately. PSA-RE bits 2.7. Disc/directory repeat mode activation status Upstream default raw=0 (not necessarily valid data).";
CM_ SG_ 416 CdChangerDiscRepeatOption "DATABASE_CANDIDATE: physical interpretation unverified; capture/layout evidence reported separately. PSA-RE bits 1.1-1.0. CD changer disc/directory repeat mode option Upstream default raw=0 (not necessarily valid data).";
CM_ SG_ 416 RandomEnabled "DATABASE_CANDIDATE: physical interpretation unverified; capture/layout evidence reported separately. PSA-RE bits 1.2. Track/file shuffle mode activation status Upstream default raw=0 (not necessarily valid data).";
CM_ SG_ 416 CdChangerRandomTrackOption "DATABASE_CANDIDATE: physical interpretation unverified; capture/layout evidence reported separately. PSA-RE bits 1.4-1.3. CD changer random track/file playback mode option Upstream default raw=0 (not necessarily valid data).";
CM_ SG_ 416 TrackIntroEnabled "DATABASE_CANDIDATE: physical interpretation unverified; capture/layout evidence reported separately. PSA-RE bits 1.5. Track intro-scan mode activation status Upstream default raw=0 (not necessarily valid data).";
CM_ SG_ 416 CdChangerTrackIntroOption "DATABASE_CANDIDATE: physical interpretation unverified; capture/layout evidence reported separately. PSA-RE bits 1.7-1.6. CD changer track intro-scan mode option Upstream default raw=0 (not necessarily valid data).";
CM_ BO_ 417 "DATABASE_CANDIDATE: physical interpretation unverified; capture/layout evidence reported separately. INFO-DIV CAN, 125000 bit/s; CAN ID 0x1A1. PSA-RE title: BSI_DISPLAY_MESSAGE. New message pointer sent by the BSI to the display on change: message priority, media and content pointer. Source: https://github.com/prototux/PSA-RE/blob/67f7581e7622410efdbb29c7eda3b86982b9b450/buses/AEE2010.full/LS.INFO-DIV/1A1.yml. Source sender alternatives: ICSV,BSI; physical TX/gateway forwarding not verified. Observed 2935 frames in info_apka.csv,info_buzeni_obc.csv,info_charging.csv,info_standby.csv,info_start_jizda.csv,infocan.csv; DLCs [8]. ";
CM_ SG_ 417 MessageArgs "DATABASE_CANDIDATE: physical interpretation unverified; capture/layout evidence reported separately. PSA-RE bits 4.7-8.0. Parameters related to the pointer Upstream default raw=1099511627775 (not necessarily valid data).";
CM_ SG_ 417 Priority "DATABASE_CANDIDATE: physical interpretation unverified; capture/layout evidence reported separately. PSA-RE bits 3.3-3.0. Priority level of the message pointer Upstream default raw=0 (not necessarily valid data).";
CM_ SG_ 417 CheckInProgress "DATABASE_CANDIDATE: physical interpretation unverified; capture/layout evidence reported separately. PSA-RE bits 3.4. Check in progress Upstream default raw=0 (not necessarily valid data).";
CM_ SG_ 417 DisplayAvailabilityAuthorization "DATABASE_CANDIDATE: physical interpretation unverified; capture/layout evidence reported separately. PSA-RE bits 3.5. Display availability authorization Upstream default raw=0 (not necessarily valid data).";
CM_ SG_ 417 DestCmb "DATABASE_CANDIDATE: physical interpretation unverified; capture/layout evidence reported separately. PSA-RE bits 3.6. Pointer to be consumed by a type-B media (e.g. CMB) Upstream default raw=0 (not necessarily valid data).";
CM_ SG_ 417 DestEmf "DATABASE_CANDIDATE: physical interpretation unverified; capture/layout evidence reported separately. PSA-RE bits 3.7. Pointer to be consumed by a type-A media (e.g. EMF) Upstream default raw=0 (not necessarily valid data).";
CM_ SG_ 417 MessageId "DATABASE_CANDIDATE: physical interpretation unverified; capture/layout evidence reported separately. PSA-RE bits 1.6-2.0. Points to the message to display Upstream default raw=0 (not necessarily valid data).";
CM_ SG_ 417 DisplayMessage "DATABASE_CANDIDATE: physical interpretation unverified; capture/layout evidence reported separately. PSA-RE bits 1.7. New message to display (toggle bit) Upstream default raw=0 (not necessarily valid data).";
CM_ BO_ 418 "DATABASE_CANDIDATE: physical interpretation unverified; capture/layout evidence reported separately. INFO-DIV CAN, 125000 bit/s; CAN ID 0x1A2. PSA-RE title: CD_CHANGER_DISK_STATUS. CD changer disk status: elapsed time (minutes/seconds), disk count and current MP3 folder. Source: https://github.com/prototux/PSA-RE/blob/67f7581e7622410efdbb29c7eda3b86982b9b450/buses/AEE2010.full/LS.INFO-DIV/1A2.yml. Source sender alternatives: ICSV,CDC; physical TX/gateway forwarding not verified. ";
CM_ SG_ 418 Unused1 "DATABASE_CANDIDATE: physical interpretation unverified; capture/layout evidence reported separately. PSA-RE bits 5.7-5.0. ";
CM_ SG_ 418 CdcMp3DirectoryNumber "DATABASE_CANDIDATE: physical interpretation unverified; capture/layout evidence reported separately. PSA-RE bits 4.7-4.0. Current MP3 directory number Raw invalid=255; numeric DBC decoders may still scale it: check raw before use. Upstream default raw=0 (not necessarily valid data).";
CM_ SG_ 418 TotalDurationSeconds "DATABASE_CANDIDATE: physical interpretation unverified; capture/layout evidence reported separately. PSA-RE bits 3.7-3.0. Total duration of the CD/directory, seconds Upstream default raw=255 (not necessarily valid data).";
CM_ SG_ 418 TotalDurationMinutes "DATABASE_CANDIDATE: physical interpretation unverified; capture/layout evidence reported separately. PSA-RE bits 2.7-2.0. Total duration of the CD/directory, minutes Upstream default raw=255 (not necessarily valid data).";
CM_ SG_ 418 Tracks "DATABASE_CANDIDATE: physical interpretation unverified; capture/layout evidence reported separately. PSA-RE bits 1.7-1.0. Number of tracks on the disc/directory being played Upstream default raw=255 (not necessarily valid data).";
CM_ BO_ 419 "DATABASE_CANDIDATE: physical interpretation unverified; capture/layout evidence reported separately. INFO-DIV CAN, 125000 bit/s; CAN ID 0x1A3. PSA-RE title: HANDSFREE_KIT_GENERAL_INFO. Hands-free (Bluetooth) kit general status: phone connected, call in progress, battery charging and streaming state. Source: https://github.com/prototux/PSA-RE/blob/67f7581e7622410efdbb29c7eda3b86982b9b450/buses/AEE2010.full/LS.INFO-DIV/1A3.yml. Source sender alternatives: RAD,ICSV; physical TX/gateway forwarding not verified. ";
CM_ SG_ 419 Unused1 "DATABASE_CANDIDATE: physical interpretation unverified; capture/layout evidence reported separately. PSA-RE bits 7.1-7.0. ";
CM_ SG_ 419 AutoHoldModeConfig "DATABASE_CANDIDATE: physical interpretation unverified; capture/layout evidence reported separately. PSA-RE bits 7.3-7.2. Automatic call-holding mode configuration Upstream default raw=0 (not necessarily valid data).";
CM_ SG_ 419 AutoHoldMode "DATABASE_CANDIDATE: physical interpretation unverified; capture/layout evidence reported separately. PSA-RE bits 7.4. Automatic call-holding mode Upstream default raw=0 (not necessarily valid data).";
CM_ SG_ 419 CallType "DATABASE_CANDIDATE: physical interpretation unverified; capture/layout evidence reported separately. PSA-RE bits 7.7-7.5. Voice call mode Upstream default raw=0 (not necessarily valid data).";
CM_ SG_ 419 BatteryStatusSimple "DATABASE_CANDIDATE: physical interpretation unverified; capture/layout evidence reported separately. PSA-RE bits 6.7-6.0. Phone battery level (streaming device) Raw invalid=255; numeric DBC decoders may still scale it: check raw before use. Upstream default raw=254 (not necessarily valid data).";
CM_ SG_ 419 PairingListAccess "DATABASE_CANDIDATE: physical interpretation unverified; capture/layout evidence reported separately. PSA-RE bits 5.1-5.0. Access to the pairing list Upstream default raw=0 (not necessarily valid data).";
CM_ SG_ 419 ImportDirectoryAccess "DATABASE_CANDIDATE: physical interpretation unverified; capture/layout evidence reported separately. PSA-RE bits 5.3-5.2. Access to the import directory Upstream default raw=0 (not necessarily valid data).";
CM_ SG_ 419 CallLogAvailable "DATABASE_CANDIDATE: physical interpretation unverified; capture/layout evidence reported separately. PSA-RE bits 5.5-5.4. Access to the call log Upstream default raw=0 (not necessarily valid data).";
CM_ SG_ 419 CombinedDirectoryAccess "DATABASE_CANDIDATE: physical interpretation unverified; capture/layout evidence reported separately. PSA-RE bits 5.7-5.6. Access to the combined SIM-card and phone-memory directory Upstream default raw=0 (not necessarily valid data).";
CM_ SG_ 419 PhoneBatteryLevel "DATABASE_CANDIDATE: physical interpretation unverified; capture/layout evidence reported separately. PSA-RE bits 4.7-4.0. Phone battery level Raw invalid=255; numeric DBC decoders may still scale it: check raw before use. Upstream default raw=254 (not necessarily valid data).";
CM_ SG_ 419 NetworkQuality "DATABASE_CANDIDATE: physical interpretation unverified; capture/layout evidence reported separately. PSA-RE bits 3.7-3.0. Network quality Raw invalid=255; numeric DBC decoders may still scale it: check raw before use. Upstream default raw=254 (not necessarily valid data).";
CM_ SG_ 419 PairingStatus "DATABASE_CANDIDATE: physical interpretation unverified; capture/layout evidence reported separately. PSA-RE bits 2.0. Pairing authorization Upstream default raw=0 (not necessarily valid data).";
CM_ SG_ 419 BluetoothAvailable "DATABASE_CANDIDATE: physical interpretation unverified; capture/layout evidence reported separately. PSA-RE bits 2.1. Bluetooth availability Upstream default raw=0 (not necessarily valid data).";
CM_ SG_ 419 KmlMuteRequest "DATABASE_CANDIDATE: physical interpretation unverified; capture/layout evidence reported separately. PSA-RE bits 2.2. KML mute request Upstream default raw=0 (not necessarily valid data).";
CM_ SG_ 419 Charging "DATABASE_CANDIDATE: physical interpretation unverified; capture/layout evidence reported separately. PSA-RE bits 2.3. Phone battery charging status Upstream default raw=0 (not necessarily valid data).";
CM_ SG_ 419 CallForwarding "DATABASE_CANDIDATE: physical interpretation unverified; capture/layout evidence reported separately. PSA-RE bits 2.4. Call forwarding Upstream default raw=0 (not necessarily valid data).";
CM_ SG_ 419 VoicemailStatus "DATABASE_CANDIDATE: physical interpretation unverified; capture/layout evidence reported separately. PSA-RE bits 2.5. Voicemail box status Upstream default raw=0 (not necessarily valid data).";
CM_ SG_ 419 MessagesStatus "DATABASE_CANDIDATE: physical interpretation unverified; capture/layout evidence reported separately. PSA-RE bits 2.7-2.6. SMS inbox status Upstream default raw=0 (not necessarily valid data).";
CM_ SG_ 419 VoicemailAvailable "DATABASE_CANDIDATE: physical interpretation unverified; capture/layout evidence reported separately. PSA-RE bits 1.0. Voicemail availability Upstream default raw=0 (not necessarily valid data).";
CM_ SG_ 419 RoamingStatus "DATABASE_CANDIDATE: physical interpretation unverified; capture/layout evidence reported separately. PSA-RE bits 1.1. International (roaming) operator present Upstream default raw=0 (not necessarily valid data).";
CM_ SG_ 419 SecretMode "DATABASE_CANDIDATE: physical interpretation unverified; capture/layout evidence reported separately. PSA-RE bits 1.2. Secret mode status Upstream default raw=0 (not necessarily valid data).";
CM_ SG_ 419 HeadsetStatus "DATABASE_CANDIDATE: physical interpretation unverified; capture/layout evidence reported separately. PSA-RE bits 1.3. Headset profile status Upstream default raw=0 (not necessarily valid data).";
CM_ SG_ 419 AutoAnswerModeConfig "DATABASE_CANDIDATE: physical interpretation unverified; capture/layout evidence reported separately. PSA-RE bits 1.5-1.4. Automatic answering mode configuration Upstream default raw=0 (not necessarily valid data).";
CM_ SG_ 419 AutoAnswerMode "DATABASE_CANDIDATE: physical interpretation unverified; capture/layout evidence reported separately. PSA-RE bits 1.6. Automatic answering mode Upstream default raw=0 (not necessarily valid data).";
CM_ SG_ 419 NumberAvailable "DATABASE_CANDIDATE: physical interpretation unverified; capture/layout evidence reported separately. PSA-RE bits 1.7. Phone number availability Upstream default raw=0 (not necessarily valid data).";
CM_ BO_ 421 "DATABASE_CANDIDATE: physical interpretation unverified; capture/layout evidence reported separately. INFO-DIV CAN, 125000 bit/s; CAN ID 0x1A5. PSA-RE title: RADIO_STATUS_VOLUME. Radio volume level and its origin (source that set it). Source: https://github.com/prototux/PSA-RE/blob/67f7581e7622410efdbb29c7eda3b86982b9b450/buses/AEE2010.full/LS.INFO-DIV/1A5.yml. Source sender alternatives: ICSV,OVIP,BTEL,RAD; physical TX/gateway forwarding not verified. Observed 1174 frames in info_apka.csv,info_buzeni_obc.csv,info_charging.csv,info_standby.csv,info_start_jizda.csv,infocan.csv; DLCs [1]. ";
CM_ SG_ 421 Volume "DATABASE_CANDIDATE: physical interpretation unverified; capture/layout evidence reported separately. PSA-RE bits 1.4-1.0. Current level of sound volume Raw invalid=31; numeric DBC decoders may still scale it: check raw before use. Upstream default raw=0 (not necessarily valid data).";
CM_ SG_ 421 VolumeChanging "DATABASE_CANDIDATE: physical interpretation unverified; capture/layout evidence reported separately. PSA-RE bits 1.7-1.5. origin of sound adjustment Upstream default raw=7 (not necessarily valid data).";
CM_ BO_ 422 "DATABASE_CANDIDATE: physical interpretation unverified; capture/layout evidence reported separately. INFO-DIV CAN, 125000 bit/s; CAN ID 0x1A6. PSA-RE title: PARKING_VIEW_SYSTEM_COMMAND. Commands sent by the BSI to the parking view system: activation state, overlay and view type selection, brightness and contrast. Source: https://github.com/prototux/PSA-RE/blob/67f7581e7622410efdbb29c7eda3b86982b9b450/buses/AEE2010.full/LS.INFO-DIV/1A6.yml. Source sender alternatives: BTEL; physical TX/gateway forwarding not verified. ";
CM_ SG_ 422 RawByte3 "RAW. PSA-RE bits 3.7-3.0. Unmapped/padding bits, no physical interpretation.";
CM_ SG_ 422 ParkingViewActivationRequ_2e3d1c "DATABASE_CANDIDATE: physical interpretation unverified; capture/layout evidence reported separately. PSA-RE bits 2.0. Parking view activation request state";
CM_ SG_ 422 ParkingViewRefreshRequest "DATABASE_CANDIDATE: physical interpretation unverified; capture/layout evidence reported separately. PSA-RE bits 2.1. Parking camera view refresh or change request";
CM_ SG_ 422 ParkingViewType "DATABASE_CANDIDATE: physical interpretation unverified; capture/layout evidence reported separately. PSA-RE bits 2.3-2.2. Parking camera view type (windowed/panoramic/360°)";
CM_ SG_ 422 ParkingViewBrightness "DATABASE_CANDIDATE: physical interpretation unverified; capture/layout evidence reported separately. PSA-RE bits 2.7-2.4. Parking camera view brightness setting";
CM_ SG_ 422 ParkingViewSelection "DATABASE_CANDIDATE: physical interpretation unverified; capture/layout evidence reported separately. PSA-RE bits 1.3-1.0. Parking camera view selection (front/rear, standard/panoramic)";
CM_ SG_ 422 ParkingViewContrast "DATABASE_CANDIDATE: physical interpretation unverified; capture/layout evidence reported separately. PSA-RE bits 1.7-1.4. Parking camera view contrast setting";
CM_ BO_ 424 "DATABASE_CANDIDATE: physical interpretation unverified; capture/layout evidence reported separately. INFO-DIV CAN, 125000 bit/s; CAN ID 0x1A8. PSA-RE title: SPEED_CONTROL. Cruise control / speed limiter status: function active, engaged, activation attempt and set speed. Source: https://github.com/prototux/PSA-RE/blob/67f7581e7622410efdbb29c7eda3b86982b9b450/buses/AEE2010.full/LS.INFO-DIV/1A8.yml. Source sender alternatives: BSI; physical TX/gateway forwarding not verified. Observed 2933 frames in info_apka.csv,info_buzeni_obc.csv,info_charging.csv,info_standby.csv,info_start_jizda.csv,infocan.csv; DLCs [8]. ";
CM_ SG_ 424 OdometerPartial "DATABASE_CANDIDATE: physical interpretation unverified; capture/layout evidence reported separately. PSA-RE bits 6.7-8.0. Partial odometer (trip meter) Raw invalid=16777215; numeric DBC decoders may still scale it: check raw before use. Upstream default raw=0 (not necessarily valid data).";
CM_ SG_ 424 SpeedLimiterUpperStop "DATABASE_CANDIDATE: physical interpretation unverified; capture/layout evidence reported separately. PSA-RE bits 4.7-5.0. Status of the upper limit Raw invalid=65535; numeric DBC decoders may still scale it: check raw before use. Upstream default raw=65535 (not necessarily valid data). Unresolved source alternatives: [{\"note\": \"Also observed with another scaling (factor 1)\", \"factor\": 1}]";
CM_ SG_ 424 SpeedLimiterLowerStop "DATABASE_CANDIDATE: physical interpretation unverified; capture/layout evidence reported separately. PSA-RE bits 2.7-3.0. Status of the lower limit Raw invalid=65535; numeric DBC decoders may still scale it: check raw before use. Upstream default raw=65535 (not necessarily valid data). Unresolved source alternatives: [{\"note\": \"Also observed with another scaling (factor 1)\", \"factor\": 1}]";
CM_ SG_ 424 SpeedLimiterStopReached "DATABASE_CANDIDATE: physical interpretation unverified; capture/layout evidence reported separately. PSA-RE bits 1.0. Status of the setpoint limit reached Upstream default raw=0 (not necessarily valid data).";
CM_ SG_ 424 SpeedLimiterPreprogrammingStatus "DATABASE_CANDIDATE: physical interpretation unverified; capture/layout evidence reported separately. PSA-RE bits 1.1. Status of preprogramming Upstream default raw=0 (not necessarily valid data).";
CM_ SG_ 424 TachoColorSelection "DATABASE_CANDIDATE: physical interpretation unverified; capture/layout evidence reported separately. PSA-RE bits 1.2. Tachometer colour selection Upstream default raw=0 (not necessarily valid data).";
CM_ SG_ 424 Unused1 "DATABASE_CANDIDATE: physical interpretation unverified; capture/layout evidence reported separately. PSA-RE bits 1.7-1.3. ";
CM_ BO_ 425 "DATABASE_CANDIDATE: physical interpretation unverified; capture/layout evidence reported separately. INFO-DIV CAN, 125000 bit/s; CAN ID 0x1A9. PSA-RE title: IVI_BUTTON_REQUESTS. Telematic unit status, sent on change: dark push-button state, emergency call request and telematic function status. Source: https://github.com/prototux/PSA-RE/blob/67f7581e7622410efdbb29c7eda3b86982b9b450/buses/AEE2010.full/LS.INFO-DIV/1A9.yml. Source sender alternatives: ICSV,BTEL,OVIP; physical TX/gateway forwarding not verified. Observed 2970 frames in info_apka.csv,info_buzeni_obc.csv,info_charging.csv,info_standby.csv,info_start_jizda.csv,infocan.csv; DLCs [8]. ";
CM_ SG_ 425 ParkingCameraViewSelection "DATABASE_CANDIDATE: physical interpretation unverified; capture/layout evidence reported separately. PSA-RE bits 8.2-8.0. Parking camera view selection (standard, 180°, zoom, auto) Upstream default raw=0 (not necessarily valid data).";
CM_ SG_ 425 CruiseProgrammedSpeedRequest "DATABASE_CANDIDATE: physical interpretation unverified; capture/layout evidence reported separately. PSA-RE bits 8.3. Request to activate the programmed cruise control/speed limiter (XVV) speed Upstream default raw=0 (not necessarily valid data).";
CM_ SG_ 425 SurroundCameraPanoramicVi_18c86a "DATABASE_CANDIDATE: physical interpretation unverified; capture/layout evidence reported separately. PSA-RE bits 8.4. Button input to select the panoramic surround-view camera Upstream default raw=0 (not necessarily valid data).";
CM_ SG_ 425 SurroundCameraFrontViewButton "DATABASE_CANDIDATE: physical interpretation unverified; capture/layout evidence reported separately. PSA-RE bits 8.5. Button input to select the front surround-view camera Upstream default raw=0 (not necessarily valid data).";
CM_ SG_ 425 SurroundCameraRearViewButton "DATABASE_CANDIDATE: physical interpretation unverified; capture/layout evidence reported separately. PSA-RE bits 8.6. Button input to select the rear surround-view camera Upstream default raw=0 (not necessarily valid data).";
CM_ SG_ 425 SurroundCameraActivationButton "DATABASE_CANDIDATE: physical interpretation unverified; capture/layout evidence reported separately. PSA-RE bits 8.7. Button input to activate the surround-view camera system (AVP) Upstream default raw=0 (not necessarily valid data).";
CM_ SG_ 425 CheckButtonRequest "DATABASE_CANDIDATE: physical interpretation unverified; capture/layout evidence reported separately. PSA-RE bits 7.0. Request triggered by pressing the touchscreen Check button Upstream default raw=0 (not necessarily valid data).";
CM_ SG_ 425 TouchscreenBrightnessRequest "DATABASE_CANDIDATE: physical interpretation unverified; capture/layout evidence reported separately. PSA-RE bits 7.4-7.1. Brightness level requested for the touchscreen display Upstream default raw=8 (not necessarily valid data).";
CM_ SG_ 425 BtelOperatingPhase "DATABASE_CANDIDATE: physical interpretation unverified; capture/layout evidence reported separately. PSA-RE bits 7.6-7.5. Current operating phase of the BTEL telematics unit (boot, upgrade, normal, appearance change) Upstream default raw=0 (not necessarily valid data).";
CM_ SG_ 425 SttButtonStatus "DATABASE_CANDIDATE: physical interpretation unverified; capture/layout evidence reported separately. PSA-RE bits 7.7. Stop & Start push-button input Upstream default raw=0 (not necessarily valid data).";
CM_ SG_ 425 TpmsButtonInput "DATABASE_CANDIDATE: physical interpretation unverified; capture/layout evidence reported separately. PSA-RE bits 6.0. Button input related to the tyre pressure monitoring system (DSG) Upstream default raw=0 (not necessarily valid data).";
CM_ SG_ 425 PushButtonPressed "DATABASE_CANDIDATE: physical interpretation unverified; capture/layout evidence reported separately. PSA-RE bits 6.1. Push button press detected Upstream default raw=0 (not necessarily valid data).";
CM_ SG_ 425 ScpStateChangeRequest "DATABASE_CANDIDATE: physical interpretation unverified; capture/layout evidence reported separately. PSA-RE bits 6.2. Request to change the SCP state Upstream default raw=0 (not necessarily valid data).";
CM_ SG_ 425 MediaDisplayFaultArc "DATABASE_CANDIDATE: physical interpretation unverified; capture/layout evidence reported separately. PSA-RE bits 6.3. Media display fault reported by the ARC function Upstream default raw=0 (not necessarily valid data).";
CM_ SG_ 425 CruiseProgrammedSpeedPosition "DATABASE_CANDIDATE: physical interpretation unverified; capture/layout evidence reported separately. PSA-RE bits 6.6-6.4. Position (slot) of the programmed cruise control/speed limiter speed setpoint Upstream default raw=0 (not necessarily valid data).";
CM_ SG_ 425 CruiseProgrammedSpeedValidation "DATABASE_CANDIDATE: physical interpretation unverified; capture/layout evidence reported separately. PSA-RE bits 6.7. Validation flag for the programmed cruise control/speed limiter speed setpoint Upstream default raw=0 (not necessarily valid data).";
CM_ SG_ 425 CruiseProgrammedSpeedSetpoint "DATABASE_CANDIDATE: physical interpretation unverified; capture/layout evidence reported separately. PSA-RE bits 5.7-5.0. Programmed cruise control/speed limiter (XVV) speed setpoint Raw invalid=255; numeric DBC decoders may still scale it: check raw before use. Upstream default raw=255 (not necessarily valid data).";
CM_ SG_ 425 CruiseSetpointMemoRequest "DATABASE_CANDIDATE: physical interpretation unverified; capture/layout evidence reported separately. PSA-RE bits 4.0. Request related to the cruise control/speed limiter (XVV) speed setpoint memory Upstream default raw=0 (not necessarily valid data).";
CM_ SG_ 425 MpdButtonStatus "DATABASE_CANDIDATE: physical interpretation unverified; capture/layout evidence reported separately. PSA-RE bits 4.1. Parking space measurement (MPD) push-button input Upstream default raw=0 (not necessarily valid data).";
CM_ SG_ 425 AasButtonStatus "DATABASE_CANDIDATE: physical interpretation unverified; capture/layout evidence reported separately. PSA-RE bits 4.2. Parking sensor (AAS) push-button input Upstream default raw=0 (not necessarily valid data).";
CM_ SG_ 425 CafrButtonInput "DATABASE_CANDIDATE: physical interpretation unverified; capture/layout evidence reported separately. PSA-RE bits 4.3. CAFR button input state Upstream default raw=0 (not necessarily valid data).";
CM_ SG_ 425 SideTrajectoryButtonStatus "DATABASE_CANDIDATE: physical interpretation unverified; capture/layout evidence reported separately. PSA-RE bits 4.4. Lane departure warning push-button input Upstream default raw=0 (not necessarily valid data).";
CM_ SG_ 425 SamButtonStatus "DATABASE_CANDIDATE: physical interpretation unverified; capture/layout evidence reported separately. PSA-RE bits 4.5. Blind spot monitoring push-button input Upstream default raw=0 (not necessarily valid data).";
CM_ SG_ 425 ArtivPlusButtonStatus "DATABASE_CANDIDATE: physical interpretation unverified; capture/layout evidence reported separately. PSA-RE bits 4.6. ARTIV setpoint increase push-button input Upstream default raw=0 (not necessarily valid data).";
CM_ SG_ 425 ArtivMinusButtonStatus "DATABASE_CANDIDATE: physical interpretation unverified; capture/layout evidence reported separately. PSA-RE bits 4.7. ARTIV setpoint decrease push-button input Upstream default raw=0 (not necessarily valid data).";
CM_ SG_ 425 InteractiveMessagePointer "DATABASE_CANDIDATE: physical interpretation unverified; capture/layout evidence reported separately. PSA-RE bits 2.6-3.0. Displayed message requiring a driver response Upstream default raw=32767 (not necessarily valid data).";
CM_ SG_ 425 CheckStopRequest "DATABASE_CANDIDATE: physical interpretation unverified; capture/layout evidence reported separately. PSA-RE bits 2.7. Request to stop the Check function Upstream default raw=0 (not necessarily valid data).";
CM_ SG_ 425 ResetTotalsTrip2Request "DATABASE_CANDIDATE: physical interpretation unverified; capture/layout evidence reported separately. PSA-RE bits 1.0. Reset request for trip 2 cumulative totals Upstream default raw=0 (not necessarily valid data).";
CM_ SG_ 425 ResetTotalsTrip1Request "DATABASE_CANDIDATE: physical interpretation unverified; capture/layout evidence reported separately. PSA-RE bits 1.1. Reset request for trip 1 cumulative totals Upstream default raw=0 (not necessarily valid data).";
CM_ SG_ 425 ArtivButtonStatus "DATABASE_CANDIDATE: physical interpretation unverified; capture/layout evidence reported separately. PSA-RE bits 1.2. ARTIV push-button input Upstream default raw=0 (not necessarily valid data).";
CM_ SG_ 425 CpkMenuSelection "DATABASE_CANDIDATE: physical interpretation unverified; capture/layout evidence reported separately. PSA-RE bits 1.4-1.3. Menu selected on the CPK system Upstream default raw=0 (not necessarily valid data).";
CM_ SG_ 425 TelematicsFunctionsStatus "DATABASE_CANDIDATE: physical interpretation unverified; capture/layout evidence reported separately. PSA-RE bits 1.5. Telematics functions status Upstream default raw=0 (not necessarily valid data).";
CM_ SG_ 425 EmergencyCallStatus "DATABASE_CANDIDATE: physical interpretation unverified; capture/layout evidence reported separately. PSA-RE bits 1.6. Emergency call (eCall) in progress Upstream default raw=0 (not necessarily valid data).";
CM_ SG_ 425 BlackPanelStatus "DATABASE_CANDIDATE: physical interpretation unverified; capture/layout evidence reported separately. PSA-RE bits 1.7. Black Panel (dark display) function status Upstream default raw=0 (not necessarily valid data).";
VAL_ 305 ValidatedItemNumber 0 "No validation" 1 "Validation of the 1st item displayed" 2 "Validation of the 2nd displayed item" 3 "Validation of 3rd item displayed" 4 "Validation of 4th item displayed" 5 "Validation of 5th item displayed" 6 "Validation of 6th item displayed" ;
VAL_ 305 UnicodeSupport 0 "'Japan/China' unicode not handled by the MAUD" 1 "'Japan/China' unicode managed by the MAUD" ;
VAL_ 305 CdChangerListMode 0 "Not requested" 1 "Requested" ;
VAL_ 305 ListFocusItemNumber 0 "No focus requested" 1 "Focus on the 1st item" 2 "Focus on 2nd item" 3 "Focus on the 3rd item" 4 "Focus on 4th item" 5 "Focus on the 5th item" 6 "Focus on the 6th item" ;
VAL_ 305 DiscNumberCommand 0 "None" 1 "Disc 1" 2 "Disc 2" 3 "Disc 3" 4 "Disc 4" 5 "Disc 5" 6 "Disc 6" 7 "Disc 7" 8 "Disc 8" 9 "Disc 9" 10 "Disc 10" 11 "Disc 11" 12 "Disc 12" 13 "Disc 13" 14 "Disc 14" 15 "Disc 15" ;
VAL_ 305 NextDiscNumberCommand 0 "None" 1 "Disc 1" 2 "Disc 2" 3 "Disc 3" 4 "Disc 4" 5 "Disc 5" 6 "Disc 6" 7 "Disc 7" 8 "Disc 8" 9 "Disc 9" 10 "Disc 10" 11 "Disc 11" 12 "Disc 12" 13 "Disc 13" 14 "Disc 14" 15 "Disc 15" ;
VAL_ 305 CdPlayMode 0 "Normal mode" 1 "Random track playback" 2 "Random current folder playing" ;
VAL_ 305 TrackDiscRepeatMode 0 "Normal mode" 1 "Track repeat" 2 "Disc repeat" ;
VAL_ 305 AudioMasterMp3Compatible 0 "Not compatible" 1 "Compatible" ;
VAL_ 305 CdChangerCommandSeries 0 "Rest" 1 "Up" 2 "Down" 3 "Invalid" 4 "OK" 5 "ESC" ;
VAL_ 305 CdChangerCommand 0 "Eject" 1 "Stop" 2 "Paused" 3 "Playing" 4 "Fast forward" 5 "Fast rewind" 7 "Intro scan" ;
VAL_ 305 RandomTrackRestartRequest 0 "Not requested" 1 "Requested" ;
VAL_ 305 CdcKnobSyncRequest 0 "Synchronization requested" 1 "No synchronization requested" ;
VAL_ 305 RandomTableSeek 0 "Rest" 1 "seek up the random table" 2 "Seek down the random table" 3 "Invalid" ;
VAL_ 305 CdChangerOnOff 0 "Stop" 1 "On" ;
VAL_ 321 FlowStatus 0 "ContinueToSend" 1 "Wait" 2 "Overflow" ;
VAL_ 321 IsoTpFrameType 0 "SingleFrame" 1 "FirstFrame" 2 "ConsecutiveFrame" 3 "FlowControl" ;
VAL_ 347 AmlaActivationRequest 0 "Inactive" 1 "Active" ;
VAL_ 347 AfsActivationRequest 0 "No request" 1 "Requested" ;
VAL_ 347 ArsActivationRequest 0 "No request" 1 "Requested" ;
VAL_ 347 IrvInhibitRequest 0 "No inhibition" 1 "Inhibition" ;
VAL_ 347 DaeModeSelection4wd 0 "Sport mode" 1 "Normal mode" ;
VAL_ 347 DaeModeSelection 0 "Sport mode" 1 "Normal mode" ;
VAL_ 347 DriverAlertAssistActivati_e419b7 0 "Inactive" 1 "Active" ;
VAL_ 347 LoadedArmAccessLockRequest 0 "Inactive" 1 "Active" ;
VAL_ 347 LoadedArmAccessRequest 0 "Inactive" 1 "Active" ;
VAL_ 347 IlvScreenRequest 0 "Function off" 1 "Function active" ;
VAL_ 347 GrilleLightingFunctionStatus 0 "Function off" 1 "Function active" ;
VAL_ 347 CafrActivationRequest 0 "Function off" 1 "Function active" ;
VAL_ 347 UserProfileSelection 0 "Default profile" 1 "User profile 1" 2 "User profile 2" 3 "User profile 3" ;
VAL_ 347 EtsrActivationRequest 0 "Inactive" 1 "Active" ;
VAL_ 347 SeeModeSelection 0 "Permanent deselection" 1 "Temporary deselection" ;
VAL_ 347 ReverseMirrorIndexingRequest 0 "Function off" 1 "Function active" ;
VAL_ 347 TpmsInitFunctionRequest 0 "Function off" 1 "Function active" ;
VAL_ 347 CollisionRiskBrakingType 0 "Function off" 1 "Function active" ;
VAL_ 347 ArcSensitivityLevel 1 "Sensitivity 1" 2 "Sensitivity 2" 3 "Sensitivity 3" ;
VAL_ 347 ArcFunctionActive 0 "Function off" 1 "Function active" ;
VAL_ 347 ConfigurableButtonFunction 0 "Dome light lighting" 1 "Black Panel" 2 "Access to the alert log (JDA)" 3 "Customisation" 4 "Instrument cluster colouring" 5 "Manual check" ;
VAL_ 347 RearFlapMotorizationFunct_177f8c 0 "Function off" 1 "Function active" ;
VAL_ 347 AutomaticRearWiperInReverse 0 "Function off" 1 "Function active" ;
VAL_ 347 BlindSpotMonitoringFeedbackType 0 "Function off" 1 "Function active" ;
VAL_ 347 ParkingAidSetup 0 "Function off" 1 "Function active" ;
VAL_ 347 AutomaticHeadlightsSwitchingOn 0 "Function off" 1 "Function active" ;
VAL_ 347 UnlockingLightingDuration 0 "15 s" 1 "30 s" 2 "60 s" ;
VAL_ 347 UnlockingLightingFunction 0 "Function off" 1 "Function active" ;
VAL_ 347 MotorwayLightingFunction 0 "Function off" 1 "Function active" ;
VAL_ 347 FollowMeHomeDuration 0 "15 s" 1 "30 s" 2 "60 s" ;
VAL_ 347 FollowMeHome 0 "Function off" 1 "Function active" ;
VAL_ 347 AmbientLighting 0 "Function off" 1 "Function active" ;
VAL_ 347 DlrFunction 0 "Function off" 1 "Function active" ;
VAL_ 347 AdaptiveLighting 0 "Function off" 1 "Function active" ;
VAL_ 347 DriverGreeting 0 "Function deactivated" 1 "Function activated" ;
VAL_ 347 RearOpeningsSelectivityStatus 0 "Function off" 1 "Function active" ;
VAL_ 347 CabOpeningsSelectivityFun_dd2313 0 "Function off" 1 "Function active" ;
VAL_ 347 DoorUnlockingModeOnKey 0 "Function off" 1 "Function active" ;
VAL_ 347 AutomaticElectricParkingB_11b15b 0 "Function off" 1 "Function active" ;
VAL_ 347 VehicleSoundHarmony 0 "Harmony 1" 1 "Harmony 2" 2 "Harmony 3" 3 "Harmony 4" ;
VAL_ 347 VehicleConfigurationDataValid 0 "Unavailable" 1 "Available" ;
VAL_ 347 AmbientLightingLevel 0 "Level 0" 1 "Level 1" 2 "Level 2" 3 "Level 3" 4 "Level 4" 5 "Level 5" 6 "Level 6" 7 "Invalid" ;
VAL_ 347 TemperatureUnit 0 "Degrees Celsius" 1 "Degrees Fahrenheit" ;
VAL_ 347 ConfigVolumeUnit 0 "litre" 1 "Gallon" ;
VAL_ 347 ConfigConsumptionUnit 0 "Volume for 100 distance units (e.g. 1/100 km)" 1 "Distance per volume unit (e.g. mpg, km/l)" ;
VAL_ 347 DistanceUnit 0 "km" 1 "miles" ;
VAL_ 347 VehicleLanguage 0 "French" 1 "English" 2 "German" 3 "Spanish" 4 "Italian" 5 "Portuguese" 6 "Dutch" 7 "Greek" 8 "Brazilian Portuguese" 9 "Polish" 10 "Traditional Chinese" 11 "Simplified Chinese" 12 "Turkish" 13 "Japanese" 14 "Russian" 15 "Czech" 16 "Croatian" 17 "Hungarian" 18 "Arabic" 19 "Bulgarian" 20 "Korean" 21 "Danish" 22 "Estonian" 23 "Farsi" 24 "Finnish" 25 "Hebrew" 26 "Norwegian" 27 "Romanian" 28 "Serbian" 29 "Swedish" 30 "Ukrainian" 31 "Vietnamese" ;
VAL_ 347 UnitLanguageDataValidity 0 "Unavailable" 1 "Available" ;
VAL_ 352 ChargeScheduleTargetLevel 0 "10" 1 "20" 2 "FULL" ;
VAL_ 352 ChargeTypeMenuStatus 0 "Immediate" 1 "Delayed" ;
VAL_ 352 ChargeScheduleStatusAvailability 0 "Unavailable" 1 "Available" ;
VAL_ 354 CdcFrontPushButtonNumber 0 "None" 1 "Disc 1" 2 "Disc 2" 3 "Disc 3" 4 "Disc 4" 5 "Disc 5" 6 "Disc 6" 7 "Disc 7" 8 "Disc 8" 9 "Disc 9" 10 "Disc 10" 11 "Disc 11" 12 "Disc 12" 13 "Disc 13" 14 "Disc 14" 15 "Disc 15" ;
VAL_ 354 CdcEjectLoadButtonPressed 0 "None" 1 "EJECT key" 2 "LOAD key" 3 "Invalid" ;
VAL_ 354 DiscPresenceCd1 0 "Disc 1 absent" 1 "Disc 1 present" ;
VAL_ 354 DiscPresenceCd2 0 "No disc 2" 1 "Disc 2 present" ;
VAL_ 354 DiscPresenceCd3 0 "No disc 3" 1 "Disc 3 present" ;
VAL_ 354 DiscPresenceCd4 0 "No disc 4" 1 "Disc 4 present" ;
VAL_ 354 DiscPresenceCd5 0 "No disc 5" 1 "Disc 5 present" ;
VAL_ 354 DiscPresenceCd6 0 "Disc 6 absent" 1 "Disc 6 present" ;
VAL_ 354 DiscPresenceCd7 0 "No disc 7" 1 "Disc 7 present" ;
VAL_ 354 DiscPresenceCd8 0 "No disc 8" 1 "Disc 8 present" ;
VAL_ 354 CdcAccessType 0 "None" 1 "Insert or change CD" 2 "Eject" ;
VAL_ 354 CdcCapacity 1 "1 CD" 2 "2 CDs" 3 "3 CD" 4 "4 CD" 5 "5 CD" 6 "6 CD" 7 "7 CD" 8 "8 CD" 9 "9 CD" 10 "10 CD" 11 "11 CDs" 12 "12 CD" 13 "13 CD" 14 "14 CD" 15 "15 CDs (max)" ;
VAL_ 354 CdcMagazinePresence 0 "Absent" 1 "Present" ;
VAL_ 354 CdcDoorStatus 0 "Closed" 1 "Open" ;
VAL_ 354 CdcStatusError 0 "Normal" 1 "Error" ;
VAL_ 354 CdcOverTemperature 0 "Normal temperature" 1 "Overheating" ;
VAL_ 354 CdcPlayerState 0 "No disc" 1 "Stop" 2 "Paused" 3 "Playing" 4 "Fast forward" 5 "Fast rewind" 7 "Intro scan" ;
VAL_ 354 CdcTextAvailable 0 "Not available" 1 "Available" ;
VAL_ 354 DiscError 0 "Disc readable" 1 "Cannot read disc" ;
VAL_ 354 DiscUpsideDown 0 "Disc right side up" 1 "Disc upside-down" ;
VAL_ 354 CdcMp3Support 0 "CDC managing audio CDs only" 1 "CDC managing MP3/WMA/AAC CDs and text CDs" ;
VAL_ 354 CdcDiscAccessInProgress 0 "Available" 1 "Access in progress" ;
VAL_ 354 CdcTrackDiscRepeatState 0 "Normal mode" 1 "Track repeat" 2 "Disc repeat" ;
VAL_ 354 CdcChangerType 0 "Magazine changer" 1 "Front-panel changer" ;
VAL_ 354 CdcListModeRequest 0 "Not requested" 1 "Requested" ;
VAL_ 354 CdcOnOffStatus 0 "Stop" 1 "On" ;
VAL_ 355 FlowStatus 0 "ContinueToSend" 1 "Wait" 2 "Overflow" ;
VAL_ 355 IsoTpFrameType 0 "SingleFrame" 1 "FirstFrame" 2 "ConsecutiveFrame" 3 "FlowControl" ;
VAL_ 357 MixedChannelMute 0 "Inactive" 1 "Active" ;
VAL_ 357 BtSrc 0 "Not present" 1 "Present, not usable" 2 "Present and usable" 3 "Invalid" ;
VAL_ 357 SupportedDigitalRadio 0 "None" 1 "DAB" 2 "DVB-T" ;
VAL_ 357 CdAudioCompression 0 "None" 1 "MPx" ;
VAL_ 357 NoSrc 0 "Not refused" 1 "To tuner" 2 "To internal CD" 3 "To CDC" 4 "To auxiliary 1" 5 "To auxiliary 2" 6 "To USB" 7 "To streaming" ;
VAL_ 357 SrcKml 0 "No passage" 1 "Passage done" ;
VAL_ 357 SrcSel 0 "None (no longitudinal control)" 1 "Tuner" 2 "Internal CD" 3 "CD changer" 4 "Auxiliary 1" 5 "Auxiliary 2" 6 "USB" 7 "Streaming" ;
VAL_ 357 SrcMix 0 "No mix with current source" 1 "Mix with the current source" ;
VAL_ 357 TimeshiftHoldRequest 0 "No Hold on asked" 1 "Hold on requested" ;
VAL_ 357 UsbSrc 0 "Not present" 1 "Present, not usable" 2 "Present and usable" 3 "Invalid" ;
VAL_ 357 CdcSrc 0 "Not present" 1 "Present and not usable" 2 "Present and usable" ;
VAL_ 357 CdSrc 0 "Not present" 1 "Present and not usable" 2 "Present and usable" ;
VAL_ 357 TunSrc 0 "Not present" 1 "Present" ;
VAL_ 357 UsbSourceType 0 "USB" 1 "iPod" ;
VAL_ 357 DynamicsCompression 0 "No compression" 1 "Compression" ;
VAL_ 357 HifiVersion 0 "No" 1 "Yes" ;
VAL_ 357 BiTuner 0 "No" 1 "Yes" ;
VAL_ 357 RadioOnRequest 0 "No request" 1 "Requested" ;
VAL_ 357 Mute 0 "Inactive" 1 "Active" ;
VAL_ 357 AmpliOn 0 "Off" 1 "On" ;
VAL_ 357 Power 0 "Off" 1 "On" ;
VAL_ 358 ParkingSlotDepthSource 0 "Estimated" 1 "Measured" ;
VAL_ 358 VparkCameraStatus 0 "VPK info absent" 1 "Rear camera" 2 "Front camera" 3 "Front/rear camera info (VPK)" ;
VAL_ 358 VparkAutoDisplay 0 "Not activated" 1 "Activated" ;
VAL_ 358 VparkActivationStatus 0 "Inactive" 1 "Active" ;
VAL_ 358 VparkViewDisplayRequest 0 "No VPARK display" 1 "display view front" 2 "Display rear view" 3 "Display front zoom view" 4 "Display rear zoom view" 5 "Display front side view" 6 "Rear side view display" 7 "Invalid" ;
VAL_ 358 ParkCameraViewDisplay 0 "No AVP display" 1 "Front view display" 2 "Panoramic view display" 3 "Rear view display" ;
VAL_ 358 AvpActivationStatus 0 "Not activated" 1 "Activated" ;
VAL_ 359 MainMenuSelection 0 "Wi-Fi settings" 1 "Data roaming" 2 "Privacy settings" 3 "Cancel" 7 "No display" ;
VAL_ 359 WifiSettingsUpdateAck 0 "Not updated" 1 "Updated" ;
VAL_ 359 HmiUserAction 0 "No action" 1 "Dismiss" 2 "Yes" ;
VAL_ 359 HmiPopupIdAck 0 "No display" 1 "Incoming advisor call" 2 "Initiated advisor call" 3 "Emergency call initiated" 4 "Connected Advisor call" 5 "Connected emergency call" 6 "Sending vehicle location" 7 "OnStar main menu" 8 "Roaming active" 9 "Roaming ended" ;
VAL_ 359 CheckStopRequest 0 "Not requested" 1 "Requested" ;
VAL_ 359 TotalMileageForTrip 65535 "Not_available" ;
VAL_ 359 TelematicsFunctionsStatus 0 "No telematics function activated" 1 "At least one telematics function activated" ;
VAL_ 359 BlackPanelStatus 0 "Function deactivated" 1 "Function activated" ;
VAL_ 359 ThermalPreconditioningRequest 0 "No request" 1 "Requested" ;
VAL_ 359 ResetMaintenanceRequest 0 "Zero reset" 1 "No reset" ;
VAL_ 359 EmergencyCallStatus 0 "No emergency call" 1 "Emergency call in progress" ;
VAL_ 359 CheckAlertRequest 0 "No request" 1 "Requested" ;
VAL_ 359 ResetTotalsTrip2Request 0 "No request" 1 "Requested" ;
VAL_ 359 ResetTotalsTrip1Request 0 "No request" 1 "Requested" ;
VAL_ 360 HadcWarningLightControl 0 "Light off" 1 "Light on" 2 "Light blink" 3 "Slow blink" ;
VAL_ 360 LaneDepartureWarningLightRequest 0 "Off" 1 "Steady on" 2 "Flashing fault" 3 "flashing warning" ;
VAL_ 360 HudRightWarningLight 0 "Off" 1 "Flashing" ;
VAL_ 360 HudLeftWarningLight 0 "Off" 1 "Flashing" ;
VAL_ 360 FarcIndicatorRequest 0 "Off" 1 "Steady on" 2 "On, blinking" ;
VAL_ 360 BrakeAssistFault 0 "No fault detected" 1 "Fault present" ;
VAL_ 360 CurrentGearDrive 0 "Disengaged" 1 "Gear 1" 2 "Gear 2" 3 "Gear 3" 4 "Gear 4" 5 "Gear 5" 6 "Gear ratio 6" 7 "Gear 7" 8 "Gear 8" 9 "gear 9" ;
VAL_ 360 EmfAvailabilityAck 0 "Not acknowledged" 1 "Acknowledged" ;
VAL_ 360 AmbienceButtonAuthorization 0 "Not authorized" 1 "Authorised" ;
VAL_ 360 HudEnabled 0 "Not authorized" 1 "Authorised" ;
VAL_ 360 DaFaultLightTestMode 0 "No request to light the warning lamp" 1 "Request to light the telltale" ;
VAL_ 360 DaFault2UpdateBit 0 "Info not refreshed" 1 "Information refreshed" ;
VAL_ 360 DaFaultType 0 "No DA fault" 1 "Power steering fault, severity 4" 2 "G3 DA fault" 3 "G3 and G4 DA fault" ;
VAL_ 360 DaFault1UpdateBit 0 "Info not refreshed" 1 "Information refreshed" ;
VAL_ 360 DaFaultIndicatorRequest 0 "No request to light the warning lamp" 1 "Request to light the red warning lamp" 2 "Request to light orange lamp" ;
VAL_ 360 SttIndicator 0 "Off" 1 "Steady on" 2 "On, blinking" 3 "Invalid" ;
VAL_ 360 PowerSteeringFault 0 "No fault detected" 1 "Fault present" ;
VAL_ 360 Caar 0 "Off" 1 "Steady on" 2 "On, blinking" 3 "Invalid" ;
VAL_ 360 SafetyFault 0 "No fault detected" 1 "Fault present" ;
VAL_ 360 TurnLightsFault 0 "No fault detected" 1 "Fault present" ;
VAL_ 360 DieselWaterFault 0 "No fault detected" 1 "Fault present" ;
VAL_ 360 MilRequestUpdateBit 0 "Info not refreshed" 1 "Information refreshed" ;
VAL_ 360 EobdFault 0 "No fault detected" 1 "Fault present" ;
VAL_ 360 BrakesFault 0 "No fault detected" 1 "Fault present" ;
VAL_ 360 GearboxFault 0 "No fault detected" 1 "Fault present" ;
VAL_ 360 AsrFault 0 "No fault detected" 1 "Fault present" ;
VAL_ 360 AbsFault 0 "No fault detected" 1 "Fault present" ;
VAL_ 360 ParkingBrakeTightFault 0 "No fault detected" 1 "Fault present" ;
VAL_ 360 ParkingBrakeFault 0 "No fault detected" 1 "Fault present" ;
VAL_ 360 AlternatorFault 0 "No fault detected" 1 "Fault present" ;
VAL_ 360 BatteryFault 0 "No fault detected" 1 "Fault present" ;
VAL_ 360 SuspensionFault 0 "No fault detected" 1 "Fault present" ;
VAL_ 360 RefEhbFault 0 "No fault detected" 1 "Fault present" ;
VAL_ 360 RearRearRightSeatbeltBlink 0 "Steady" 1 "Flashing lamp" ;
VAL_ 360 RearRearRightSeatbelt 0 "Normal" 1 "Unfastened" ;
VAL_ 360 RearRearLeftSeatbeltBlink 0 "Steady" 1 "Flashing lamp" ;
VAL_ 360 RearRearLeftSeatbelt 0 "Normal" 1 "Unfastened" ;
VAL_ 360 PlusStartIndicator 0 "Off" 1 "On" ;
VAL_ 360 MaxRpmLvl2 0 "Off" 1 "On" ;
VAL_ 360 MaxRpmLvl1 0 "Off" 1 "On" ;
VAL_ 360 AutoWipeStatus 0 "Inactive" 1 "Active" ;
VAL_ 360 ParticleFilterFault 0 "Off" 1 "Steady on" ;
VAL_ 360 PollutionFault 0 "No fault detected" 1 "Fault present" ;
VAL_ 360 PunctureAlert 0 "No alert" 1 "Alarm present" ;
VAL_ 360 UnderinflationAlert 0 "No alert" 1 "Alarm present" ;
VAL_ 360 DsgFaultLightState 0 "No ignition" 1 "Ignition" ;
VAL_ 360 ColdEngineAlert 0 "No alert" 1 "Alert" ;
VAL_ 360 BrakeLevelAlert 0 "No alert" 1 "Alarm present" ;
VAL_ 360 OilPressureAlert 0 "No alert" 1 "Alarm present" ;
VAL_ 360 OilLevelAlert 0 "No alert" 1 "Alarm present" ;
VAL_ 360 CoolantLevelAlert 0 "No alert" 1 "Alarm present" ;
VAL_ 360 GearboxRatioCount 0 "6 or less" 1 "Greater than 6" ;
VAL_ 360 CoolantTemperatureAlert 0 "No alert" 1 "Alarm present" ;
VAL_ 361 ArrivalMinute 63 "Not_available" ;
VAL_ 361 ArrivalHour 31 "Not_available" ;
VAL_ 361 DistanceToNextManeuver 0 "0 m or 0 Yd" 1 "10 m or 10 yd" 2 "20 m or 20 yd" 3 "30 m or 30 yd" 4 "40 m or 40 yd" 5 "50 m or 50 yd" 6 "60 m or 60 yd" 7 "70 m or 70 yd" 8 "80 m or 80 yd" 9 "90 m or 90 yd" 10 "100 m or 100 yd" 11 "150 m or 150 yd" 12 "200 m or 200 yd" 13 "250 m or 250 yd" 14 "300 m or 300 yd" 15 "350 m or 350 yd" 16 "400 m or 400 yd" 17 "600 m or 600 yd" 18 "800 m or 800 yd" 19 "1 km or 1 mile" 20 "1.2 km or 1.2 mile" 21 "1.4 km or 1.4 mile" 22 "1.6 km or 1.6 mile" 23 "1.8 km or 1.8 mile" 24 "2.0 km or 2.0 mile" 25 "2.2 km or 2.2 miles" 26 "2.4 km or 2.4 miles" 27 "2.6 km or 2.6 mile" 28 "2.8 km or 2.8 mile" 29 "3.0 km or 3.0 miles" 30 "4.0 km or 4.0 mile" 31 "5.0 km or 5.0 mile" 32 "6.0 km or 6.0 mile" 33 "7.0 km or 7,0 mile" 34 "8.0 km or 8.0 mile" 4095 "4069 km or 4069 miles" 4096 "4070 km or 4070 mile" 8189 "8163 km or 8163 miles" 8190 "8164 km or 8164 miles" 8191 "Invalid" ;
VAL_ 361 DistanceToDestination 0 "0 km or mile" 1 "1 km or mile" 2 "2 km or miles" 3 "3 km or mile" 4 "4 km or mile" 5 "5 km or miles" 6 "6 km or mile" 7 "7 km or miles" 8 "8 Km or mile" 9 "9 km or miles" 10 "10 km or mile" 11 "11 km or mile" 12 "12 km or miles" 13 "13 km or mile" 14 "14 km or mile" 9998 "9998 Km or mile" 9999 "9999 km or mile" 10000 "10 m or 10 yd" 10001 "20 m or 20 yd" 10002 "30 m or 30 yd" 10003 "40 m or 40 yd" 10004 "50 m or 50 yd" 10005 "60 m or 60 yd" 10006 "70 m or 70 yd" 10007 "80 m or 80 yd" 10008 "90 m or 90 yd" 10009 "100 m or 100 yd" 10010 "150 m or 150 yd" 10011 "200 m or 200 yd" 10012 "250 m or 250 yd" 10013 "300 m or 300 yd" 10014 "350 m or 350 yd" 10015 "400 m or 400 yd" 10016 "600 m or 600 yd" 10017 "800 m or 800 yd" 10018 "1.2 km or 1.2 mile" 10019 "1.4 km or 1.4 mile" 10020 "1.6 km or 1.6 mile" 10021 "1.8 km or 1.8 mile" 10022 "2.2 km or 2.2 miles" 10023 "2.4 km or 2.4 miles" 10024 "2.6 km or 2.6 mile" 10025 "2.8 km or 2.8 mile" 10026 "Invalid" ;
VAL_ 361 ArrivalTimePictogramRequest 0 "Not requested" 1 "Requested" ;
VAL_ 361 FinishFlagPictogramRequest 0 "Not requested" 1 "Requested" ;
VAL_ 361 VehicleAltitude 16383 "Not_available" ;
VAL_ 361 ManeuverPictogramNumber 0 "Flowing road" 1 "Left fork" 2 "Right fork" 3 "Left U-turn" 4 "Right U-turn" 5 "Roundabout" 6 "Turn left" 7 "Turn right" 8 "Heading south" 9 "Heading south-south-east" 10 "Heading south-east" 11 "Heading south-south-east" 12 "Heading East" 13 "Head North East East" 14 "Heading North-East" 15 "Heading North-North-East" 16 "Heading North" 17 "Heading north-northwest" 18 "Heading north-west" 19 "Heading west-north-west" 20 "Heading west" 21 "Heading south-west-west" 22 "Heading South West" 23 "Heading South-South-West" 24 "Checkered flag" 25 "Stage checkered flag" 26 "Checkered flag stage 1" 27 "Finish flag, stage 2" 28 "Finish flag, step 3" 29 "Checkered flag, stage 4" 30 "Checkered flag, stage 5" 31 "Checkered flag, stage 6" 32 "Checkered flag, stage 7" 33 "Checkered flag stage 8" 34 "Checkered flag, stage 9" 35 "Checkered flag stage 10" 36 "Checkered flag, stage 11" 37 "Stage 12 finish flag" ;
VAL_ 361 NavigationCalculationInProgress 0 "No calculation ongoing" 1 "Calculating" ;
VAL_ 361 NavigationStatus 0 "Navigation inactive" 1 "Navigation active" ;
VAL_ 385 FlowStatus 0 "ContinueToSend" 1 "Wait" 2 "Overflow" ;
VAL_ 385 IsoTpFrameType 0 "SingleFrame" 1 "FirstFrame" 2 "ConsecutiveFrame" 3 "FlowControl" ;
VAL_ 411 CruiseMenuInfoAvailability 0 "Unavailable" 1 "Available" ;
VAL_ 411 Stop6SpeedValue 255 "Not_available" ;
VAL_ 412 EcocoachAdvice31Active 0 "Inactive" 1 "Active" ;
VAL_ 412 EcocoachAdvice30Active 0 "Inactive" 1 "Active" ;
VAL_ 412 EcocoachAdvice29Active 0 "Inactive" 1 "Active" ;
VAL_ 412 EcocoachAdvice28Active 0 "Inactive" 1 "Active" ;
VAL_ 412 EcocoachAdvice27Active 0 "Inactive" 1 "Active" ;
VAL_ 412 EcocoachAdvice26Active 0 "Inactive" 1 "Active" ;
VAL_ 412 EcocoachAdvice25Active 0 "Inactive" 1 "Active" ;
VAL_ 412 EcocoachAdvice24Active 0 "Inactive" 1 "Active" ;
VAL_ 412 EcocoachAdvice23Active 0 "Inactive" 1 "Active" ;
VAL_ 412 EcocoachAdvice22Active 0 "Inactive" 1 "Active" ;
VAL_ 412 EcocoachAdvice21Active 0 "Inactive" 1 "Active" ;
VAL_ 412 EcocoachAdvice20Active 0 "Inactive" 1 "Active" ;
VAL_ 412 EcocoachAdvice19Active 0 "Inactive" 1 "Active" ;
VAL_ 412 EcocoachAdvice18Active 0 "Inactive" 1 "Active" ;
VAL_ 412 EcocoachAdvice17Active 0 "Inactive" 1 "Active" ;
VAL_ 412 EcocoachAdvice16Active 0 "Inactive" 1 "Active" ;
VAL_ 412 EcocoachAdvice15Active 0 "Inactive" 1 "Active" ;
VAL_ 412 EcocoachAdvice14Active 0 "Inactive" 1 "Active" ;
VAL_ 412 EcocoachAdvice13Active 0 "Inactive" 1 "Active" ;
VAL_ 412 EcocoachAdvice12Active 0 "Inactive" 1 "Active" ;
VAL_ 412 EcocoachAdvice11Active 0 "Inactive" 1 "Active" ;
VAL_ 412 EcocoachAdvice10Active 0 "Inactive" 1 "Active" ;
VAL_ 412 EcocoachAdvice9Active 0 "Inactive" 1 "Active" ;
VAL_ 412 EcocoachAdvice8Active 0 "Inactive" 1 "Active" ;
VAL_ 412 EcocoachAdvice7Active 0 "Inactive" 1 "Active" ;
VAL_ 412 EcocoachAdvice6Active 0 "Inactive" 1 "Active" ;
VAL_ 412 EcocoachAdvice5Active 0 "Inactive" 1 "Active" ;
VAL_ 412 EcocoachAdvice4Active 0 "Inactive" 1 "Active" ;
VAL_ 412 EcocoachAdvice3Active 0 "Inactive" 1 "Active" ;
VAL_ 412 EcocoachAdvice2Active 0 "Inactive" 1 "Active" ;
VAL_ 412 EcocoachAdvice1Active 0 "Inactive" 1 "Active" ;
VAL_ 412 EcocoachFreewheelTime 32767 "Not_available" ;
VAL_ 412 EcocoachFreewheelDistance 16383 "Not_available" ;
VAL_ 416 CdChangerAlbumShuffleStatus 0 "Option deactivated" 1 "Option activated" ;
VAL_ 416 CdChangerAlbumShuffleOption 0 "Option unavailable" 1 "Option cannot be activated" 2 "Option can be activated" ;
VAL_ 416 RepeatEnabled 0 "Option deactivated" 1 "Option activated" ;
VAL_ 416 CdChangerDiscRepeatOption 0 "Option unavailable" 1 "Option cannot be activated" 2 "Option can be activated" ;
VAL_ 416 RandomEnabled 0 "Option deactivated" 1 "Option activated" ;
VAL_ 416 CdChangerRandomTrackOption 0 "Option unavailable" 1 "Option cannot be activated" 2 "Option can be activated" ;
VAL_ 416 TrackIntroEnabled 0 "Option deactivated" 1 "Option activated" ;
VAL_ 416 CdChangerTrackIntroOption 0 "Option unavailable" 1 "Option cannot be activated" 2 "Option can be activated" ;
VAL_ 417 CheckInProgress 0 "No check in progress" 1 "Checking in progress" ;
VAL_ 417 DisplayAvailabilityAuthorization 0 "Authorised" 1 "Not authorized" ;
VAL_ 417 DestCmb 0 "Media type B, not consuming" 1 "Media type B consumer" ;
VAL_ 417 DestEmf 0 "Media type A, not a consumer" 1 "Media type A consumer" ;
VAL_ 417 DisplayMessage 0 "Value 1" 1 "Value 2" ;
VAL_ 418 CdcMp3DirectoryNumber 255 "Not_available" ;
VAL_ 419 AutoHoldModeConfig 0 "Option unavailable" 1 "Option cannot be activated" 2 "Option can be activated" ;
VAL_ 419 AutoHoldMode 0 "Inactive" 1 "Active" ;
VAL_ 419 CallType 0 "No mode" 1 "Voice recognition impossible" 2 "Voice command menu" 3 "Invalid" 4 "Invalid" 5 "Call via voice shortcut" 6 "Voice-dialled call" 7 "Keyword not recognized" ;
VAL_ 419 BatteryStatusSimple 255 "Not_available" ;
VAL_ 419 PairingListAccess 0 "Unavailable" 1 "no activation possible" 2 "Can be activated" ;
VAL_ 419 ImportDirectoryAccess 0 "Unavailable" 1 "no activation possible" 2 "Can be activated" ;
VAL_ 419 CallLogAvailable 0 "Unavailable" 1 "no activation possible" 2 "Can be activated" ;
VAL_ 419 CombinedDirectoryAccess 0 "Unavailable" 1 "no activation possible" 2 "Can be activated" ;
VAL_ 419 PhoneBatteryLevel 255 "Not_available" ;
VAL_ 419 NetworkQuality 255 "Not_available" ;
VAL_ 419 PairingStatus 0 "Not authorized" 1 "Authorised" ;
VAL_ 419 BluetoothAvailable 0 "Function unavailable" 1 "Function available" ;
VAL_ 419 KmlMuteRequest 0 "Inactive" 1 "Active" ;
VAL_ 419 Charging 0 "Battery discharging" 1 "Battery charging" ;
VAL_ 419 CallForwarding 0 "No return" 1 "Return" ;
VAL_ 419 VoicemailStatus 0 "No voice message" 1 "One or more voice messages" ;
VAL_ 419 MessagesStatus 0 "None" 1 "One or more SMS received" 2 "Full" ;
VAL_ 419 VoicemailAvailable 0 "Unavailable" 1 "Available" ;
VAL_ 419 RoamingStatus 0 "No international roaming in progress" 1 "International roaming in progress" ;
VAL_ 419 SecretMode 0 "Inactive" 1 "Active" ;
VAL_ 419 HeadsetStatus 0 "Different headset profile" 1 "Headset profile" ;
VAL_ 419 AutoAnswerModeConfig 0 "Option unavailable" 1 "Option cannot be activated" 2 "Option can be activated" ;
VAL_ 419 AutoAnswerMode 0 "Inactive" 1 "Active" ;
VAL_ 419 NumberAvailable 0 "Unavailable" 1 "Available" ;
VAL_ 421 Volume 31 "Not_available" ;
VAL_ 421 VolumeChanging 0 "User setting" 1 "Source change" 2 "Volume/speed control" 3 "Source mixing for AAS" 4 "Thermal protection" 5 "Overtaking" 6 "Phone user setting" 7 "Other or idle" ;
VAL_ 422 ParkingViewActivationRequ_2e3d1c 0 "No request" 1 "Request" ;
VAL_ 422 ParkingViewRefreshRequest 0 "Inactive" 1 "Active" ;
VAL_ 422 ParkingViewType 0 "No request" 1 "Windowed view" 2 "Panoramic view" 3 "360° view" ;
VAL_ 422 ParkingViewSelection 0 "No request" 1 "Standard front view" 2 "Standard rear view" 3 "Panoramic front view" 4 "Panoramic rear view" 5 "Left lateral view" 6 "Right side view" 7 "360 view Left" 8 "360° view, right" 9 "360 view suspended" ;
VAL_ 424 OdometerPartial 16777215 "Not_available" ;
VAL_ 424 SpeedLimiterUpperStop 65535 "Not_available" ;
VAL_ 424 SpeedLimiterLowerStop 65535 "Not_available" ;
VAL_ 424 SpeedLimiterStopReached 0 "False" 1 "True" ;
VAL_ 424 SpeedLimiterPreprogrammingStatus 0 "Inactive" 1 "Active" ;
VAL_ 424 TachoColorSelection 0 "No request" 1 "Requested" ;
VAL_ 425 ParkingCameraViewSelection 0 "No request" 1 "Standard view" 2 "180-degree view" 3 "Zoom view" 4 "Automatic view" 5 "Unavailable" 6 "Unavailable" 7 "Unavailable" ;
VAL_ 425 CruiseProgrammedSpeedRequest 0 "No request" 1 "Requested" ;
VAL_ 425 SurroundCameraPanoramicVi_18c86a 0 "No request" 1 "Requested" ;
VAL_ 425 SurroundCameraFrontViewButton 0 "No request" 1 "Requested" ;
VAL_ 425 SurroundCameraRearViewButton 0 "No request" 1 "Requested" ;
VAL_ 425 SurroundCameraActivationButton 0 "No request" 1 "Requested" ;
VAL_ 425 CheckButtonRequest 0 "No request" 1 "Requested" ;
VAL_ 425 BtelOperatingPhase 0 "Boot in progress" 1 "Upgrade in progress" 2 "Normal" 3 "Change of appearance" ;
VAL_ 425 SttButtonStatus 0 "Not activated" 1 "Activated" ;
VAL_ 425 TpmsButtonInput 0 "Not activated" 1 "Activated" ;
VAL_ 425 PushButtonPressed 0 "Not pressed" 1 "Pressed" ;
VAL_ 425 ScpStateChangeRequest 0 "No request" 1 "Requested" ;
VAL_ 425 MediaDisplayFaultArc 0 "No fault detected" 1 "Failure detected" ;
VAL_ 425 CruiseProgrammedSpeedPosition 0 "None (no longitudinal control)" 1 "Position 1" 2 "Position 2" 3 "Position 3" 4 "Position 4" 5 "Position 5" 6 "Position 6" ;
VAL_ 425 CruiseProgrammedSpeedValidation 0 "Value 1" 1 "Value 2" ;
VAL_ 425 CruiseProgrammedSpeedSetpoint 255 "Not_available" ;
VAL_ 425 CruiseSetpointMemoRequest 0 "No request" 1 "Requested" ;
VAL_ 425 MpdButtonStatus 0 "Not activated" 1 "Activated" ;
VAL_ 425 AasButtonStatus 0 "Not activated" 1 "Activated" ;
VAL_ 425 CafrButtonInput 0 "Not activated" 1 "Activated" ;
VAL_ 425 SideTrajectoryButtonStatus 0 "Not activated" 1 "Activated" ;
VAL_ 425 SamButtonStatus 0 "Not activated" 1 "Activated" ;
VAL_ 425 ArtivPlusButtonStatus 0 "Not activated" 1 "Activated" ;
VAL_ 425 ArtivMinusButtonStatus 0 "Not activated" 1 "Activated" ;
VAL_ 425 CheckStopRequest 0 "Not requested" 1 "Requested" ;
VAL_ 425 ResetTotalsTrip2Request 0 "No request" 1 "Requested" ;
VAL_ 425 ResetTotalsTrip1Request 0 "No request" 1 "Requested" ;
VAL_ 425 ArtivButtonStatus 0 "Not activated" 1 "Activated" ;
VAL_ 425 CpkMenuSelection 0 "No request" 1 "SCP6" 2 "SCP9" 3 "AMSP" ;
VAL_ 425 TelematicsFunctionsStatus 0 "No telematics function activated" 1 "At least one telematics function activated" ;
VAL_ 425 EmergencyCallStatus 0 "No emergency call" 1 "Emergency call in progress" ;
VAL_ 425 BlackPanelStatus 0 "Function deactivated" 1 "Function activated" ;
SG_MUL_VAL_ 321 SingleFrameLength IsoTpFrameType 0-0;
SG_MUL_VAL_ 321 FirstFrameLength IsoTpFrameType 1-1;
SG_MUL_VAL_ 321 ConsecutiveSequence IsoTpFrameType 2-2;
SG_MUL_VAL_ 321 FlowStatus IsoTpFrameType 3-3;
SG_MUL_VAL_ 321 UnknownPciLow IsoTpFrameType 4-15;
SG_MUL_VAL_ 321 BlockSize IsoTpFrameType 3-3;
SG_MUL_VAL_ 321 SingleData1 IsoTpFrameType 0-0;
SG_MUL_VAL_ 321 ConsecutiveData1 IsoTpFrameType 2-2;
SG_MUL_VAL_ 321 UnknownData1 IsoTpFrameType 4-15;
SG_MUL_VAL_ 321 SeparationTimeRaw IsoTpFrameType 3-3;
SG_MUL_VAL_ 321 SingleData2 IsoTpFrameType 0-0;
SG_MUL_VAL_ 321 ConsecutiveData2 IsoTpFrameType 2-2;
SG_MUL_VAL_ 321 UnknownData2 IsoTpFrameType 4-15;
SG_MUL_VAL_ 321 FirstData1 IsoTpFrameType 1-1;
SG_MUL_VAL_ 321 SingleData3 IsoTpFrameType 0-0;
SG_MUL_VAL_ 321 ConsecutiveData3 IsoTpFrameType 2-2;
SG_MUL_VAL_ 321 UnknownData3 IsoTpFrameType 4-15;
SG_MUL_VAL_ 321 FirstData2 IsoTpFrameType 1-1;
SG_MUL_VAL_ 321 FlowPadding1 IsoTpFrameType 3-3;
SG_MUL_VAL_ 321 SingleData4 IsoTpFrameType 0-0;
SG_MUL_VAL_ 321 ConsecutiveData4 IsoTpFrameType 2-2;
SG_MUL_VAL_ 321 UnknownData4 IsoTpFrameType 4-15;
SG_MUL_VAL_ 321 FirstData3 IsoTpFrameType 1-1;
SG_MUL_VAL_ 321 FlowPadding2 IsoTpFrameType 3-3;
SG_MUL_VAL_ 321 SingleData5 IsoTpFrameType 0-0;
SG_MUL_VAL_ 321 ConsecutiveData5 IsoTpFrameType 2-2;
SG_MUL_VAL_ 321 UnknownData5 IsoTpFrameType 4-15;
SG_MUL_VAL_ 321 FirstData4 IsoTpFrameType 1-1;
SG_MUL_VAL_ 321 FlowPadding3 IsoTpFrameType 3-3;
SG_MUL_VAL_ 321 SingleData6 IsoTpFrameType 0-0;
SG_MUL_VAL_ 321 ConsecutiveData6 IsoTpFrameType 2-2;
SG_MUL_VAL_ 321 UnknownData6 IsoTpFrameType 4-15;
SG_MUL_VAL_ 321 FirstData5 IsoTpFrameType 1-1;
SG_MUL_VAL_ 321 FlowPadding4 IsoTpFrameType 3-3;
SG_MUL_VAL_ 321 SingleData7 IsoTpFrameType 0-0;
SG_MUL_VAL_ 321 ConsecutiveData7 IsoTpFrameType 2-2;
SG_MUL_VAL_ 321 UnknownData7 IsoTpFrameType 4-15;
SG_MUL_VAL_ 321 FirstData6 IsoTpFrameType 1-1;
SG_MUL_VAL_ 321 FlowPadding5 IsoTpFrameType 3-3;
SG_MUL_VAL_ 355 SingleFrameLength IsoTpFrameType 0-0;
SG_MUL_VAL_ 355 FirstFrameLength IsoTpFrameType 1-1;
SG_MUL_VAL_ 355 ConsecutiveSequence IsoTpFrameType 2-2;
SG_MUL_VAL_ 355 FlowStatus IsoTpFrameType 3-3;
SG_MUL_VAL_ 355 UnknownPciLow IsoTpFrameType 4-15;
SG_MUL_VAL_ 355 BlockSize IsoTpFrameType 3-3;
SG_MUL_VAL_ 355 SingleData1 IsoTpFrameType 0-0;
SG_MUL_VAL_ 355 ConsecutiveData1 IsoTpFrameType 2-2;
SG_MUL_VAL_ 355 UnknownData1 IsoTpFrameType 4-15;
SG_MUL_VAL_ 355 SeparationTimeRaw IsoTpFrameType 3-3;
SG_MUL_VAL_ 355 SingleData2 IsoTpFrameType 0-0;
SG_MUL_VAL_ 355 ConsecutiveData2 IsoTpFrameType 2-2;
SG_MUL_VAL_ 355 UnknownData2 IsoTpFrameType 4-15;
SG_MUL_VAL_ 355 FirstData1 IsoTpFrameType 1-1;
SG_MUL_VAL_ 355 SingleData3 IsoTpFrameType 0-0;
SG_MUL_VAL_ 355 ConsecutiveData3 IsoTpFrameType 2-2;
SG_MUL_VAL_ 355 UnknownData3 IsoTpFrameType 4-15;
SG_MUL_VAL_ 355 FirstData2 IsoTpFrameType 1-1;
SG_MUL_VAL_ 355 FlowPadding1 IsoTpFrameType 3-3;
SG_MUL_VAL_ 355 SingleData4 IsoTpFrameType 0-0;
SG_MUL_VAL_ 355 ConsecutiveData4 IsoTpFrameType 2-2;
SG_MUL_VAL_ 355 UnknownData4 IsoTpFrameType 4-15;
SG_MUL_VAL_ 355 FirstData3 IsoTpFrameType 1-1;
SG_MUL_VAL_ 355 FlowPadding2 IsoTpFrameType 3-3;
SG_MUL_VAL_ 355 SingleData5 IsoTpFrameType 0-0;
SG_MUL_VAL_ 355 ConsecutiveData5 IsoTpFrameType 2-2;
SG_MUL_VAL_ 355 UnknownData5 IsoTpFrameType 4-15;
SG_MUL_VAL_ 355 FirstData4 IsoTpFrameType 1-1;
SG_MUL_VAL_ 355 FlowPadding3 IsoTpFrameType 3-3;
SG_MUL_VAL_ 355 SingleData6 IsoTpFrameType 0-0;
SG_MUL_VAL_ 355 ConsecutiveData6 IsoTpFrameType 2-2;
SG_MUL_VAL_ 355 UnknownData6 IsoTpFrameType 4-15;
SG_MUL_VAL_ 355 FirstData5 IsoTpFrameType 1-1;
SG_MUL_VAL_ 355 FlowPadding4 IsoTpFrameType 3-3;
SG_MUL_VAL_ 355 SingleData7 IsoTpFrameType 0-0;
SG_MUL_VAL_ 355 ConsecutiveData7 IsoTpFrameType 2-2;
SG_MUL_VAL_ 355 UnknownData7 IsoTpFrameType 4-15;
SG_MUL_VAL_ 355 FirstData6 IsoTpFrameType 1-1;
SG_MUL_VAL_ 355 FlowPadding5 IsoTpFrameType 3-3;
SG_MUL_VAL_ 385 SingleFrameLength IsoTpFrameType 0-0;
SG_MUL_VAL_ 385 FirstFrameLength IsoTpFrameType 1-1;
SG_MUL_VAL_ 385 ConsecutiveSequence IsoTpFrameType 2-2;
SG_MUL_VAL_ 385 FlowStatus IsoTpFrameType 3-3;
SG_MUL_VAL_ 385 UnknownPciLow IsoTpFrameType 4-15;
SG_MUL_VAL_ 385 BlockSize IsoTpFrameType 3-3;
SG_MUL_VAL_ 385 SingleData1 IsoTpFrameType 0-0;
SG_MUL_VAL_ 385 ConsecutiveData1 IsoTpFrameType 2-2;
SG_MUL_VAL_ 385 UnknownData1 IsoTpFrameType 4-15;
SG_MUL_VAL_ 385 SeparationTimeRaw IsoTpFrameType 3-3;
SG_MUL_VAL_ 385 SingleData2 IsoTpFrameType 0-0;
SG_MUL_VAL_ 385 ConsecutiveData2 IsoTpFrameType 2-2;
SG_MUL_VAL_ 385 UnknownData2 IsoTpFrameType 4-15;
SG_MUL_VAL_ 385 FirstData1 IsoTpFrameType 1-1;
SG_MUL_VAL_ 385 SingleData3 IsoTpFrameType 0-0;
SG_MUL_VAL_ 385 ConsecutiveData3 IsoTpFrameType 2-2;
SG_MUL_VAL_ 385 UnknownData3 IsoTpFrameType 4-15;
SG_MUL_VAL_ 385 FirstData2 IsoTpFrameType 1-1;
SG_MUL_VAL_ 385 FlowPadding1 IsoTpFrameType 3-3;
SG_MUL_VAL_ 385 SingleData4 IsoTpFrameType 0-0;
SG_MUL_VAL_ 385 ConsecutiveData4 IsoTpFrameType 2-2;
SG_MUL_VAL_ 385 UnknownData4 IsoTpFrameType 4-15;
SG_MUL_VAL_ 385 FirstData3 IsoTpFrameType 1-1;
SG_MUL_VAL_ 385 FlowPadding2 IsoTpFrameType 3-3;
SG_MUL_VAL_ 385 SingleData5 IsoTpFrameType 0-0;
SG_MUL_VAL_ 385 ConsecutiveData5 IsoTpFrameType 2-2;
SG_MUL_VAL_ 385 UnknownData5 IsoTpFrameType 4-15;
SG_MUL_VAL_ 385 FirstData4 IsoTpFrameType 1-1;
SG_MUL_VAL_ 385 FlowPadding3 IsoTpFrameType 3-3;
SG_MUL_VAL_ 385 SingleData6 IsoTpFrameType 0-0;
SG_MUL_VAL_ 385 ConsecutiveData6 IsoTpFrameType 2-2;
SG_MUL_VAL_ 385 UnknownData6 IsoTpFrameType 4-15;
SG_MUL_VAL_ 385 FirstData5 IsoTpFrameType 1-1;
SG_MUL_VAL_ 385 FlowPadding4 IsoTpFrameType 3-3;
SG_MUL_VAL_ 385 SingleData7 IsoTpFrameType 0-0;
SG_MUL_VAL_ 385 ConsecutiveData7 IsoTpFrameType 2-2;
SG_MUL_VAL_ 385 UnknownData7 IsoTpFrameType 4-15;
SG_MUL_VAL_ 385 FirstData6 IsoTpFrameType 1-1;
SG_MUL_VAL_ 385 FlowPadding5 IsoTpFrameType 3-3;
